VERSION ""

NS_ :

BS_:

BU_: TBOX Tester WCM MFS HUD CGW IHU

BO_ 1535 CGW_CEM_BCM_3: 8 CGW
 SG_ CEM_Remote_key_start : 54|1@0+ (1,0) [0|1] "" Vector__XXX
 SG_ CEM_6_Driver_massageSts : 63|1@0+ (1,0) [0|1] ""  IHU
 SG_ CEM_6_DriverVibrationSts : 62|2@0+ (1,0) [0|3] ""  IHU
 SG_ CEM_6_Driver_massagemodeSts : 60|3@0+ (1,0) [0|7] ""  IHU
 SG_ CEM_3_Windows_Inhibit_SW : 32|1@0+ (1,0) [0|1] ""  IHU
 SG_ CEM_3_CurrentTelematicsMode : 5|2@0+ (1,0) [0|3] ""  IHU
 SG_ CEM_3_GalleryModeSts : 26|2@0+ (1,0) [0|3] ""  IHU
 SG_ CEM_3_passenger_Welcome_Seat_Sts : 57|2@0+ (1,0) [0|3] "Bit"  IHU
 SG_ CEM_DHM_Doorkonbmode_feedback : 53|2@0+ (1,0) [0|2] "Bit"  IHU
 SG_ CEM_DHM_Driver_unlockmode_feedba : 51|2@0+ (1,0) [0|2] "bit"  IHU
 SG_ CEM_UVC_LuminanceBf : 47|3@0+ (1,0) [0|7] "Bit"  IHU
 SG_ CEM_UVC_WorkingBf : 36|2@0+ (1,0) [0|3] "Bit"  IHU
 SG_ CEM_3_Welcome_Seat_Sts : 34|2@0+ (1,0) [0|3] "Bit"  IHU
 SG_ CEM_IPM_3_ACMAXReq_Sts : 38|2@0+ (1,0) [0|3] "Bit"  IHU
 SG_ CEM_3_PM25DisplayToggle_Sts : 49|2@0+ (1,0) [0|3] "Bit"  IHU
 SG_ CEM_3_DWM_Sts_Msg : 17|2@0+ (1,0) [0|3] "Bit"  IHU
 SG_ CEM_3_EngineControlSts : 9|1@0+ (1,0) [0|1] "Bit"  IHU

BO_ 914 CGW_CEM_BCM_2: 8 CGW
 SG_ UnlockingBreathStatus : 52|2@0+ (1,0) [0|3] ""  IHU
 SG_ AidTurningIlluminationSts : 49|1@0+ (1,0) [0|1] ""  IHU
 SG_ CEM_2_AlarmMode : 59|4@0+ (1,0) [0|15] "Bit"  IHU
 SG_ CEM_2_RemoteTrunkOnlySts : 62|1@0+ (1,0) [0|1] "Bit"  IHU
 SG_ CEM_2_AutoLockSts : 63|1@0+ (1,0) [0|1] "Bit"  IHU
 SG_ CEM_2RearDefrosts : 60|1@0+ (1,0) [0|1] "Bit"  IHU
 SG_ CEM_2_HazardLampForUrgencyBrakeS : 48|1@0+ (1,0) [0|1] "Bit"  IHU
 SG_ CEM_2_Mirror_FlipSts : 50|1@0+ (1,0) [0|1] "Bit"  IHU
 SG_ CEM_2_RemoteLockFeedbackSts : 54|2@0+ (1,0) [0|3] "Bit"  IHU
 SG_ CEM_2_AutoUnlockSts : 55|1@0+ (1,0) [0|1] "Bit"  IHU
 SG_ CEM_2_WiperSts : 47|2@0+ (1,0) [0|3] "Bit"  IHU
 SG_ CEM_2_RainDetected : 45|1@0+ (1,0) [0|1] "Bit"  IHU
 SG_ CEM_2_WiperSensitivitySWSts : 44|3@0+ (1,0) [0|7] "Bit"  IHU
 SG_ CEM_2_RainSensorFailSts : 41|1@0+ (1,0) [0|1] "Bit"  IHU
 SG_ CEM_2_RARDfstCmd : 40|1@0+ (1,0) [0|1] "Bit"  IHU
 SG_ CEM_2_WiperSelectionSts : 39|2@0+ (1,0) [0|3] "Bit"  IHU
 SG_ CEM_2_FrontFogLightSts : 37|1@0+ (1,0) [0|1] "Bit"  IHU
 SG_ CEM_2_Laser_High_Beam_Assist_Sta : 36|1@0+ (1,0) [0|1] "Bit"  IHU
 SG_ CEM_2_ReverseGearSwitch : 35|1@0+ (1,0) [0|1] "Bit"  IHU
 SG_ CEM_2_RearFogLightSts : 34|1@0+ (1,0) [0|1] "Bit"  IHU
 SG_ CEM_2_External_WelcomelightSts : 33|2@0+ (1,0) [0|3] "Bit"  IHU
 SG_ CEM_2_Mirror_Fold_Sts : 31|1@0+ (1,0) [0|1] "Bit"  IHU
 SG_ CEM_2_TrunkSts : 30|1@0+ (1,0) [0|1] "Bit"  IHU
 SG_ CEM_2_LHRdoorSts : 29|1@0+ (1,0) [0|1] "Bit"  IHU
 SG_ CEM_2_RHRDoorSts : 28|1@0+ (1,0) [0|1] "Bit"  IHU
 SG_ CEM_2_SunRoofSts : 27|1@0+ (1,0) [0|1] "Bit"  IHU
 SG_ CEM_2_HoodSts : 26|1@0+ (1,0) [0|1] "Bit"  IHU
 SG_ CEM_2_PsngrDoorSts : 25|1@0+ (1,0) [0|1] "Bit"  IHU
 SG_ CEM_2_DriverDoorSts : 24|1@0+ (1,0) [0|1] "Bit"  IHU
 SG_ CEM_2_FollowMeTimeSts : 23|4@0+ (1,0) [0|15] "Bit"  IHU
 SG_ CEM_2_BlankingnumberSts : 19|2@0+ (1,0) [0|3] "Bit"  IHU
 SG_ CEM_2_DirectionIndLeft : 17|1@0+ (1,0) [0|1] "Bit"  IHU
 SG_ CEM_2_DirectionIndRight : 16|1@0+ (1,0) [0|1] "Bit"  IHU
 SG_ CEM_2_DRLSts : 15|1@0+ (1,0) [0|1] "Bit"  IHU
 SG_ CEM_2_LowBeamSts : 14|1@0+ (1,0) [0|1] "Bit"  IHU
 SG_ CEM_2_Laser_LightSts : 13|1@0+ (1,0) [0|1] "Bit"  IHU
 SG_ CEM_2_HighBeamSts : 12|1@0+ (1,0) [0|1] "Bit"  IHU
 SG_ CEM_2_ParkTailLightSts : 11|1@0+ (1,0) [0|1] "Bit"  IHU
 SG_ CEM_2_BrakePedalSts : 10|1@0+ (1,0) [0|1] "Bit"  IHU
 SG_ CEM_2_LHTurnlightSts : 9|1@0+ (1,0) [0|1] "Bit"  IHU
 SG_ CEM_2_RHTurnlightSts : 8|1@0+ (1,0) [0|1] "Bit"  IHU
 SG_ CEM_2_BlankchanginglaneSts : 7|1@0+ (1,0) [0|1] "Bit"  IHU
 SG_ CEM_2_KeySts : 6|2@0+ (1,0) [0|3] "Bit"  IHU
 SG_ CEM_2_FollowMeHomeSts : 4|1@0+ (1,0) [0|1] "Bit"  IHU
 SG_ CEM_2_KeyRemindWarning : 3|1@0+ (1,0) [0|1] "Bit"  IHU
 SG_ CEM_2_ParkLightOnWarning : 2|1@0+ (1,0) [0|1] "Bit"  IHU
 SG_ CEM_2_FollowMeHomeTimeSts : 1|2@0+ (1,0) [0|3] "Bit"  IHU

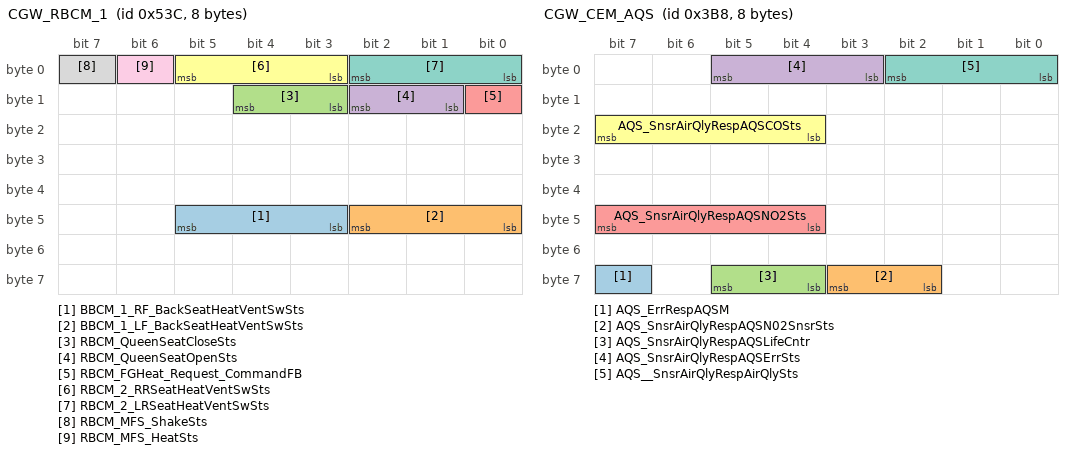
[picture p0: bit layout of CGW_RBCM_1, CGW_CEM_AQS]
BO_ 1340 CGW_RBCM_1: 8 CGW
 SG_ BBCM_1_RF_BackSeatHeatVentSwSts : 45|3@0+ (1,0) [0|4] ""  IHU
 SG_ BBCM_1_LF_BackSeatHeatVentSwSts : 42|3@0+ (1,0) [0|4] ""  IHU
 SG_ RBCM_QueenSeatCloseSts : 12|2@0+ (1,0) [0|3] ""  IHU
 SG_ RBCM_QueenSeatOpenSts : 10|2@0+ (1,0) [0|3] ""  IHU
 SG_ RBCM_FGHeat_Request_CommandFB : 8|1@0+ (1,0) [0|1] "Bit"  IHU
 SG_ RBCM_2_RRSeatHeatVentSwSts : 5|3@0+ (1,0) [0|7] "Bit"  IHU
 SG_ RBCM_2_LRSeatHeatVentSwSts : 2|3@0+ (1,0) [0|7] "Bit"  IHU
 SG_ RBCM_MFS_ShakeSts : 7|1@0+ (1,0) [0|1] "Bit"  IHU
 SG_ RBCM_MFS_HeatSts : 6|1@0+ (1,0) [0|1] "Bit"  IHU

BO_ 1306 CGW_CEM_IPM: 8 CGW
 SG_ CEM_IPM_FRSeatHeatVentSwSts : 61|3@0+ (1,0) [0|7] ""  IHU
 SG_ CEM_IPM_FLSeatHeatVentSwSts : 58|3@0+ (1,0) [0|7] ""  IHU
 SG_ CEM_IPM_ACFastHeatASts : 52|1@0+ (1,0) [0|1] ""  IHU
 SG_ CEM_IPM_FrontDefroststs : 16|1@0+ (1,0) [0|1] ""  IHU
 SG_ CEM_IPM_Blower_DelaySts : 49|1@0+ (1,0) [0|1] ""  IHU
 SG_ CEM_IPM_BT_Reduce_Wind_SpeedSts : 48|1@0+ (1,0) [0|1] "bit"  IHU
 SG_ TMM_IHU_OffRoadSts : 46|1@0+ (1,0) [0|1] "Bit"  IHU
 SG_ CEM_IPM_AC_DisplaySts : 45|1@0+ (1,0) [0|1] "Bit"  IHU
 SG_ CEM_IPM_Custom_Air_Conditioning : 54|2@0+ (1,0) [0|2] "Bit"  IHU
 SG_ CEM_IPM_Automatic_Ventilation : 51|1@0+ (1,0) [0|1] "Bit"  IHU
 SG_ CEM_IPM_First_BlowingSts : 50|1@0+ (1,0) [0|1] "Bit"  IHU
 SG_ CEM_IPM_TempknobRollingCounter : 35|5@0+ (1,0) [0|31] "Bit"  IHU
 SG_ CEM_IPM_AnionPurify : 63|1@0+ (1,0) [0|1] "Bit"  IHU
 SG_ CEM_IPM_PM25_Detect : 55|1@0+ (1,0) [0|1] "Bit"  IHU
 SG_ CEM_IPM_SyncSts : 44|1@0+ (1,0) [0|1] "Bit"  IHU
 SG_ CEM_IPM_FrontAutoACSts : 43|1@0+ (1,0) [0|1] "Bit"  IHU
 SG_ CEM_IPM_RearBlowModeSts : 42|2@0+ (1,0) [0|3] "Bit"  IHU
 SG_ CEM_IPM_RearAutoACSts : 40|1@0+ (1,0) [0|1] "Bit"  IHU
 SG_ CEM_IPM_RearBlowSpdCtrlSts : 39|4@0+ (1,0) [0|15] "Bit"  IHU
 SG_ CEM_IPM_RearTempsts : 29|6@0+ (0.5,0) [16|30] "℃"  IHU
 SG_ CEM_IPM_RearOFFsts : 31|1@0+ (1,0) [0|1] "Bit"  IHU
 SG_ CEM_IPM_RearDefrosts : 30|1@0+ (1,0) [0|1] "Bit"  IHU
 SG_ CEM_IPM_FrontOFFSts : 17|1@0+ (1,0) [0|1] "Bit"  IHU
 SG_ CEM_IPM_ACStatus : 21|1@0+ (1,0) [0|1] "Bit"  IHU
 SG_ CEM_IPM_RecyMode : 23|2@0+ (1,0) [0|3] "Bit"  IHU
 SG_ CEM_IPM_FrontBlowModeSts : 20|3@0+ (1,0) [0|7] "Bit"  IHU
 SG_ CEM_IPM_FrontBlowSpdCtrlsts : 11|4@0+ (1,0) [0|15] "Bit"  IHU
 SG_ CEM_IPM_FRTempsts : 7|6@0+ (0.5,0) [16|30] "℃"  IHU
 SG_ CEM_IPM_FLTempsts : 1|6@0+ (0.5,0) [16|30] "℃"  IHU

BO_ 952 CGW_CEM_AQS: 8 CGW
 SG_ AQS_ErrRespAQSM : 63|1@0+ (1,0) [0|1] "" Vector__XXX
 SG_ AQS_SnsrAirQlyRespAQSN02SnsrSts : 59|2@0+ (1,0) [0|3] "" Vector__XXX
 SG_ AQS_SnsrAirQlyRespAQSLifeCntr : 61|2@0+ (1,0) [0|3] ""  IHU
 SG_ AQS_SnsrAirQlyRespAQSErrSts : 5|3@0+ (1,0) [0|7] ""  IHU
 SG_ AQS_SnsrAirQlyRespAQSNO2Sts : 47|4@0+ (1,0) [0|15] ""  IHU
 SG_ AQS_SnsrAirQlyRespAQSCOSts : 23|4@0+ (1,0) [0|15] ""  IHU
 SG_ AQS__SnsrAirQlyRespAirQlySts : 2|3@0+ (1,0) [0|7] ""  IHU

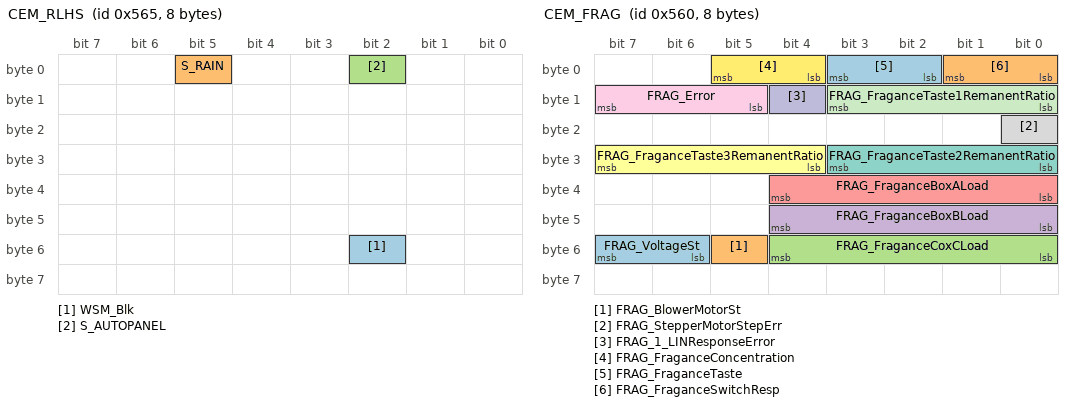
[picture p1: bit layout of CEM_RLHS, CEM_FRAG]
BO_ 1381 CEM_RLHS: 8 CGW
 SG_ WSM_Blk : 50|1@0+ (1,0) [0|1] ""  IHU
 SG_ S_RAIN : 5|1@0+ (1,0) [0|1] "Bit"  IHU
 SG_ S_AUTOPANEL : 2|1@0+ (1,0) [0|1] "Bit"  IHU

BO_ 1376 CEM_FRAG: 8 CGW
 SG_ FRAG_VoltageSt : 55|2@0+ (1,0) [0|3] "Bit"  IHU
 SG_ FRAG_BlowerMotorSt : 53|1@0+ (1,0) [0|1] "Bit"  IHU
 SG_ FRAG_FraganceCoxCLoad : 52|5@0+ (1,0) [0|31] "Bit"  IHU
 SG_ FRAG_FraganceBoxBLoad : 44|5@0+ (1,0) [0|31] "Bit"  IHU
 SG_ FRAG_FraganceBoxALoad : 36|5@0+ (1,0) [0|31] "Bit"  IHU
 SG_ FRAG_FraganceTaste3RemanentRatio : 31|4@0+ (1,0) [0|15] "Bit"  IHU
 SG_ FRAG_FraganceTaste2RemanentRatio : 27|4@0+ (1,0) [0|15] "Bit"  IHU
 SG_ FRAG_StepperMotorStepErr : 16|1@0+ (1,0) [0|1] "Bit"  IHU
 SG_ FRAG_Error : 15|3@0+ (1,0) [0|7] "Bit"  IHU
 SG_ FRAG_1_LINResponseError : 12|1@0+ (1,0) [0|1] "Bit"  IHU
 SG_ FRAG_FraganceTaste1RemanentRatio : 11|4@0+ (1,0) [0|15] "Bit"  IHU
 SG_ FRAG_FraganceConcentration : 5|2@0+ (1,0) [0|3] "Bit"  IHU
 SG_ FRAG_FraganceTaste : 3|2@0+ (1,0) [0|3] "Bit"  IHU
 SG_ FRAG_FraganceSwitchResp : 1|2@0+ (1,0) [0|3] "Bit"  IHU

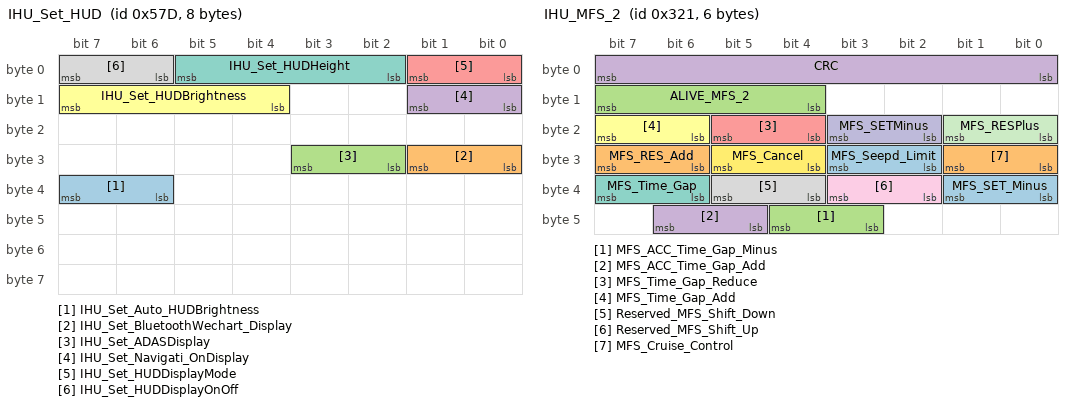
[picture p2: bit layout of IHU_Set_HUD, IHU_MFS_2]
BO_ 1405 IHU_Set_HUD: 8 IHU
 SG_ IHU_Set_Auto_HUDBrightness : 39|2@0+ (1,0) [0|3] "Bit"  CGW
 SG_ IHU_Set_BluetoothWechart_Display : 25|2@0+ (1,0) [0|3] "Bit"  CGW
 SG_ IHU_Set_ADASDisplay : 27|2@0+ (1,0) [0|3] "Bit"  CGW
 SG_ IHU_Set_Navigati_OnDisplay : 9|2@0+ (1,0) [0|3] "Bit"  CGW
 SG_ IHU_Set_HUDDisplayMode : 1|2@0+ (1,0) [0|3] "Bit"  CGW
 SG_ IHU_Set_HUDBrightness : 15|4@0+ (1,0) [0|15] "Bit"  CGW
 SG_ IHU_Set_HUDHeight : 5|4@0+ (1,0) [0|15] "Bit"  CGW
 SG_ IHU_Set_HUDDisplayOnOff : 7|2@0+ (1,0) [0|3] "Bit"  CGW

BO_ 1389 IHU_WCM_Reserved: 8 IHU
 SG_ IHU_WCM_DVD_NFC_Connect_BM_Addr : 7|48@0+ (1,0) [0|281474976710660] "Bit"  CGW

BO_ 801 IHU_MFS_2: 6 CGW
 SG_ MFS_SET_Minus : 33|2@0+ (1,0) [0|3] ""  IHU
 SG_ MFS_RES_Add : 31|2@0+ (1,0) [0|3] ""  IHU
 SG_ MFS_ACC_Time_Gap_Minus : 44|2@0+ (1,0) [0|3] ""  IHU
 SG_ MFS_ACC_Time_Gap_Add : 46|2@0+ (1,0) [0|3] ""  IHU
 SG_ MFS_Time_Gap_Reduce : 21|2@0+ (1,0) [0|3] ""  IHU
 SG_ MFS_Time_Gap_Add : 23|2@0+ (1,0) [0|3] ""  IHU
 SG_ MFS_Time_Gap : 39|2@0+ (1,0) [0|3] "Bit"  IHU
 SG_ Reserved_MFS_Shift_Down : 37|2@0+ (1,0) [0|3] "Bit"  IHU
 SG_ Reserved_MFS_Shift_Up : 35|2@0+ (1,0) [0|3] "Bit"  IHU
 SG_ MFS_SETMinus : 19|2@0+ (1,0) [0|3] "Bit"  IHU
 SG_ MFS_RESPlus : 17|2@0+ (1,0) [0|3] "Bit"  IHU
 SG_ MFS_Cancel : 29|2@0+ (1,0) [0|3] "Bit"  IHU
 SG_ MFS_Seepd_Limit : 27|2@0+ (1,0) [0|3] "Bit"  IHU
 SG_ MFS_Cruise_Control : 25|2@0+ (1,0) [0|3] "Bit"  IHU
 SG_ ALIVE_MFS_2 : 15|4@0+ (1,0) [0|15] "Bit"  IHU
 SG_ CRC : 7|8@0+ (1,0) [0|255] "Bit"  IHU

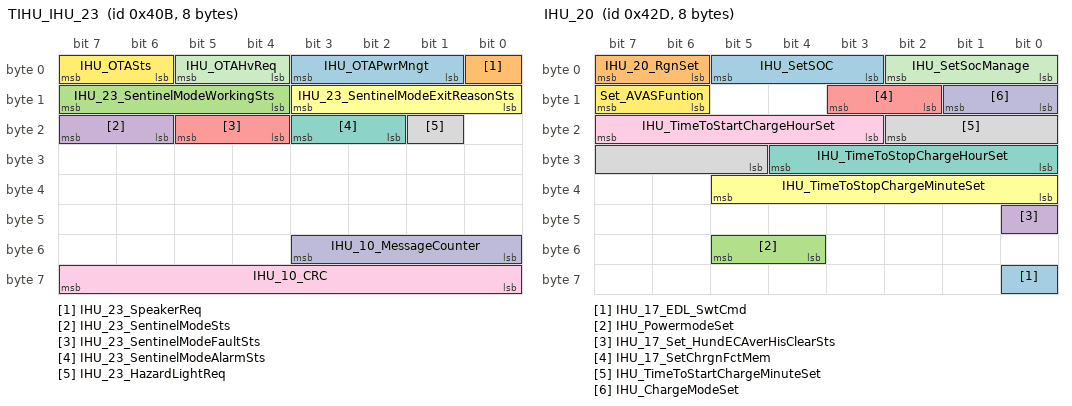
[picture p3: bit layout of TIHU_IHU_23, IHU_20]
BO_ 1035 TIHU_IHU_23: 8 IHU
 SG_ IHU_OTAPwrMngt : 3|3@0+ (1,0) [0|7] ""  CGW
 SG_ IHU_23_SpeakerReq : 0|1@0+ (1,0) [0|1] ""  CGW
 SG_ IHU_23_SentinelModeWorkingSts : 15|4@0+ (1,0) [0|15] ""  CGW
 SG_ IHU_23_SentinelModeSts : 23|2@0+ (1,0) [0|3] ""  CGW
 SG_ IHU_23_SentinelModeFaultSts : 21|2@0+ (1,0) [0|3] ""  CGW
 SG_ IHU_23_SentinelModeExitReasonSts : 11|4@0+ (1,0) [0|15] ""  CGW
 SG_ IHU_23_SentinelModeAlarmSts : 19|2@0+ (1,0) [0|3] ""  CGW
 SG_ IHU_23_HazardLightReq : 17|1@0+ (1,0) [0|1] ""  CGW
 SG_ IHU_10_CRC : 63|8@0+ (1,0) [0|255] ""  CGW
 SG_ IHU_10_MessageCounter : 51|4@0+ (1,0) [0|15] ""  CGW
 SG_ IHU_OTAHvReq : 5|2@0+ (1,0) [0|3] ""  CGW
 SG_ IHU_OTASts : 7|2@0+ (1,0) [0|3] ""  CGW

BO_ 1058 IHU_21: 8 IHU
 SG_ IHU_RIPM_Req : 39|2@0+ (1,0) [0|3] ""  CGW
 SG_ IHU_RestDriverseatMemoryReq : 23|1@0+ (1,0) [0|1] "bit"  CGW
 SG_ IHU_21_AmbientLight_SceneMode : 22|3@0+ (1,0) [0|7] "bit"  CGW
 SG_ IHU_OfficeDriverseatMemoryReq : 2|1@0+ (1,0) [0|1] "bit"  CGW
 SG_ IHU_21_Random_showLamp_SW : 37|2@0+ (1,0) [0|3] "bit"  CGW
 SG_ IHU_21NavigationalTurnType : 35|2@0+ (1,0) [0|3] "bit"  CGW
 SG_ IHU_21AssociatedNavigationModeSw : 33|1@0+ (1,0) [0|1] "bit"  CGW
 SG_ IHU_21MessageCounter : 32|6@0+ (1,0) [0|63] "bit"  CGW
 SG_ IHU_21VoiceBroadcast : 42|1@0+ (1,0) [0|1] "bit"  CGW
 SG_ IHU_21VoiceWake : 41|2@0+ (1,0) [0|3] "bit"  CGW
 SG_ IHU_21_FatigueDrivingReminder_Se : 31|3@0+ (1,0) [0|7] "h"  CGW
 SG_ IHU_21_OverspeedAlarm_Set : 28|5@0+ (5,30) [30|130] "KM/L"  CGW
 SG_ IHU_ICMBrightnessManualAdj : 15|4@0+ (1,0) [0|15] ""  CGW
 SG_ IHU_SET_ICMBrightnessMode : 11|1@0+ (1,0) [0|1] ""  CGW
 SG_ IHU_LockAnimation : 10|3@0+ (1,0) [0|7] ""  CGW
 SG_ IHU_UnlockAnimation : 7|3@0+ (1,0) [0|7] ""  CGW
 SG_ IHU_FatigueDriving : 4|1@0+ (1,0) [0|1] ""  CGW
 SG_ IHU_SmartSceneMode : 19|4@0+ (1,0) [0|15] ""  CGW

BO_ 1069 IHU_20: 8 IHU
 SG_ IHU_17_EDL_SwtCmd : 56|1@0+ (1,0) [0|1] ""  CGW
 SG_ IHU_20_RgnSet : 7|2@0+ (1,0) [0|3] ""  CGW
 SG_ IHU_PowermodeSet : 53|2@0+ (1,0) [0|3] ""  CGW
 SG_ IHU_17_Set_HundECAverHisClearSts : 40|1@0+ (1,0) [0|1] ""  CGW
 SG_ IHU_17_SetChrgnFctMem : 11|2@0+ (1,0) [0|3] ""  CGW
 SG_ IHU_TimeToStopChargeMinuteSet : 37|6@0+ (1,0) [0|59] ""  CGW
 SG_ IHU_TimeToStopChargeHourSet : 28|5@0+ (1,0) [0|23] ""  CGW
 SG_ IHU_TimeToStartChargeMinuteSet : 18|6@0+ (1,0) [0|59] ""  CGW
 SG_ IHU_TimeToStartChargeHourSet : 23|5@0+ (1,0) [0|23] ""  CGW
 SG_ IHU_ChargeModeSet : 9|2@0+ (1,0) [0|3] ""  CGW
 SG_ IHU_SetSocManage : 2|3@0+ (1,0) [0|7] ""  CGW
 SG_ Set_AVASFuntion : 15|2@0+ (1,0) [0|3] ""  CGW
 SG_ IHU_SetSOC : 5|3@0+ (1,0) [0|7] ""  CGW

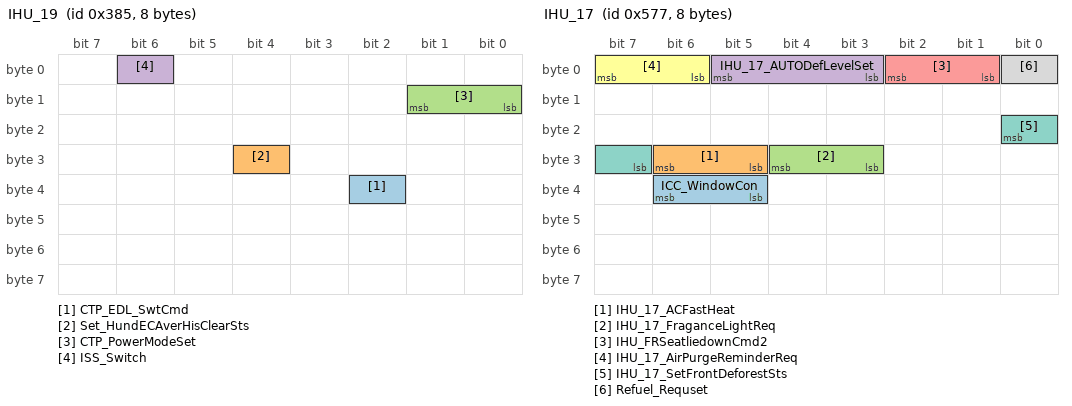
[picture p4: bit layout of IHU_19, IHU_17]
BO_ 901 IHU_19: 8 IHU
 SG_ CTP_EDL_SwtCmd : 34|1@0+ (1,0) [0|1] ""  CGW
 SG_ Set_HundECAverHisClearSts : 28|1@0+ (1,0) [0|1] ""  CGW
 SG_ CTP_PowerModeSet : 9|2@0+ (1,0) [0|3] ""  CGW
 SG_ ISS_Switch : 6|1@0+ (1,0) [0|1] "Bit"  CGW

BO_ 1399 IHU_17: 8 IHU
 SG_ ICC_WindowCon : 38|2@0+ (1,0) [0|3] ""  CGW
 SG_ IHU_17_ACFastHeat : 30|2@0+ (1,0) [0|3] ""  CGW
 SG_ IHU_17_FraganceLightReq : 28|2@0+ (1,0) [0|3] ""  CGW
 SG_ IHU_17_AUTODefLevelSet : 5|3@0+ (1,0) [0|7] ""  CGW
 SG_ IHU_FRSeatliedownCmd2 : 2|2@0+ (1,0) [0|3] ""  CGW
 SG_ IHU_17_AirPurgeReminderReq : 7|2@0+ (1,0) [0|3] ""  CGW
 SG_ IHU_17_SetFrontDeforestSts : 16|2@0+ (1,0) [0|3] ""  CGW
 SG_ Refuel_Requset : 0|1@0+ (1,0) [0|1] "Bit"  CGW

BO_ 1407 IHU_15: 8 IHU
 SG_ IHU_IPM_Delayventilation_Req : 39|2@0+ (1,0) [0|3] ""  CGW
 SG_ IHU_15_door_lock_req : 29|2@0+ (1,0) [0|3] ""  CGW
 SG_ IHU_15_GalleryModeReg : 27|2@0+ (1,0) [0|3] ""  CGW
 SG_ IHU_15_AutoDefogEnaSw : 25|2@0+ (1,0) [0|3] ""  CGW
 SG_ IHU_15_Parkingairconditioning : 31|2@0+ (1,0) [0|3] ""  CGW
 SG_ SET_IHU_ACMAXReq : 61|2@0+ (1,0) [0|3] "Bit"  CGW
 SG_ IHU15_MessageCounter : 59|4@0+ (1,0) [0|15] "Bit"  CGW
 SG_ IHU_SpeechControl : 55|2@0+ (1,0) [0|3] "Bit"  CGW
 SG_ SET_Mirror_Fold_Switch : 23|2@0+ (1,0) [0|3] "Bit"  CGW
 SG_ SET_Passenger_Mirror_Location : 20|5@0+ (1,0) [0|21] "Bit"  CGW
 SG_ SET_Driver_Mirror_Location : 50|5@0+ (1,0) [0|15] "Bit"  CGW
 SG_ SET_IPM_Automatic_Ventilation : 9|2@0+ (1,0) [0|3] "Bit"  CGW
 SG_ SET_Mirror_Flip_CFG : 12|3@0+ (1,0) [0|7] "Bit"  CGW
 SG_ SET_RightMirrorCtrl : 53|3@0+ (1,0) [0|7] "Bit"  CGW
 SG_ SET_LeftMirrorCtrl : 15|3@0+ (1,0) [0|7] "Bit"  CGW
 SG_ SET_IPMCustom_Air_Conditioning : 1|2@0+ (1,0) [0|3] "Bit"  CGW
 SG_ SET_FRSeatHeatVentSwReq : 7|3@0+ (1,0) [0|7] "Bit"  CGW
 SG_ SET_FLSeatHeatVentSwReq : 4|3@0+ (1,0) [0|7] "Bit"  CGW

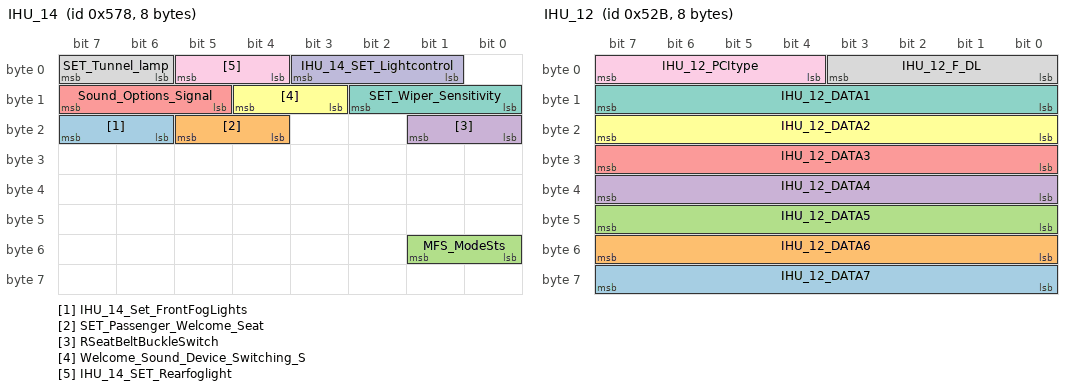
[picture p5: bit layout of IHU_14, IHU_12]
BO_ 1400 IHU_14: 8 IHU
 SG_ IHU_14_Set_FrontFogLights : 23|2@0+ (1,0) [0|3] ""  CGW
 SG_ SET_Passenger_Welcome_Seat : 21|2@0+ (1,0) [0|3] "Bit"  CGW
 SG_ MFS_ModeSts : 49|2@0+ (1,0) [0|3] ""  CGW
 SG_ RSeatBeltBuckleSwitch : 17|2@0+ (1,0) [0|3] "Bit"  CGW
 SG_ Sound_Options_Signal : 15|3@0+ (1,0) [0|5] "Bit"  CGW
 SG_ Welcome_Sound_Device_Switching_S : 12|2@0+ (1,0) [0|3] "Bit"  CGW
 SG_ SET_Wiper_Sensitivity : 10|3@0+ (1,0) [0|7] "Bit"  CGW
 SG_ SET_Tunnel_lamp : 7|2@0+ (1,0) [0|2] "Bit"  CGW
 SG_ IHU_14_SET_Rearfoglight : 5|2@0+ (1,0) [0|2] "Bit"  CGW
 SG_ IHU_14_SET_Lightcontrol : 3|3@0+ (1,0) [0|4] "Bit"  CGW

BO_ 1401 IHU_13: 8 IHU
 SG_ IHU13_MessageCounter : 59|4@0+ (1,0) [0|15] "Bit"  CGW
 SG_ SET_Welcome_Seat : 63|2@0+ (1,0) [0|3] "Bit"  CGW
 SG_ SET_MFS_Shake : 61|2@0+ (1,0) [0|3] "Bit"  CGW
 SG_ SET_MFS_Heat : 55|2@0+ (1,0) [0|3] "Bit"  CGW
 SG_ SET_UnderVoltage : 53|2@0+ (1,0) [0|3] "Bit"  CGW
 SG_ SET_RearWiper_Switch : 51|2@0+ (1,0) [0|3] "Bit"  CGW
 SG_ SET_Wiper_Maintenance : 49|2@0+ (1,0) [0|3] "Bit"  CGW
 SG_ SET_Abat_VentCMD : 47|4@0+ (1,0) [0|15] "Bit"  CGW
 SG_ SET_PSRFCMD : 43|4@0+ (1,0) [0|15] "Bit"  CGW
 SG_ SET_Massagemode : 39|3@0+ (1,0) [0|7] "Bit"  CGW
 SG_ SET_Vibrationmode : 36|3@0+ (1,0) [0|7] "Bit"  CGW
 SG_ SET_Passenger_Massage : 33|2@0+ (1,0) [0|3] "Bit"  CGW
 SG_ SET_PLG_Control : 13|2@0+ (1,0) [0|3] "Bit"  CGW
 SG_ SET_Doorkonbmode : 11|2@0+ (1,0) [0|3] "Bit"  CGW
 SG_ SET_Doorkonb_time : 9|2@0+ (1,0) [0|3] "Bit"  CGW
 SG_ SET_Driver_unlockmode : 6|2@0+ (1,0) [0|3] "Bit"  CGW
 SG_ SET_Smart_LowBeam : 4|2@0+ (1,0) [0|3] "Bit"  CGW
 SG_ SET_LowBeam_Adjust : 2|3@0+ (1,0) [0|7] "Bit"  CGW

BO_ 1323 IHU_12: 8 IHU
 SG_ IHU_12_DATA7 : 63|8@0+ (1,0) [0|255] "Bit"  CGW
 SG_ IHU_12_DATA6 : 55|8@0+ (1,0) [0|255] "Bit"  CGW
 SG_ IHU_12_DATA5 : 47|8@0+ (1,0) [0|255] "Bit"  CGW
 SG_ IHU_12_DATA4 : 39|8@0+ (1,0) [0|255] "Bit"  CGW
 SG_ IHU_12_DATA3 : 31|8@0+ (1,0) [0|255] "Bit"  CGW
 SG_ IHU_12_DATA2 : 23|8@0+ (1,0) [0|255] "Bit"  CGW
 SG_ IHU_12_DATA1 : 15|8@0+ (1,0) [0|255] "Bit"  CGW
 SG_ IHU_12_F_DL : 3|4@0+ (1,0) [0|15] "Bit"  CGW
 SG_ IHU_12_PCItype : 7|4@0+ (1,0) [0|15] "Bit"  CGW

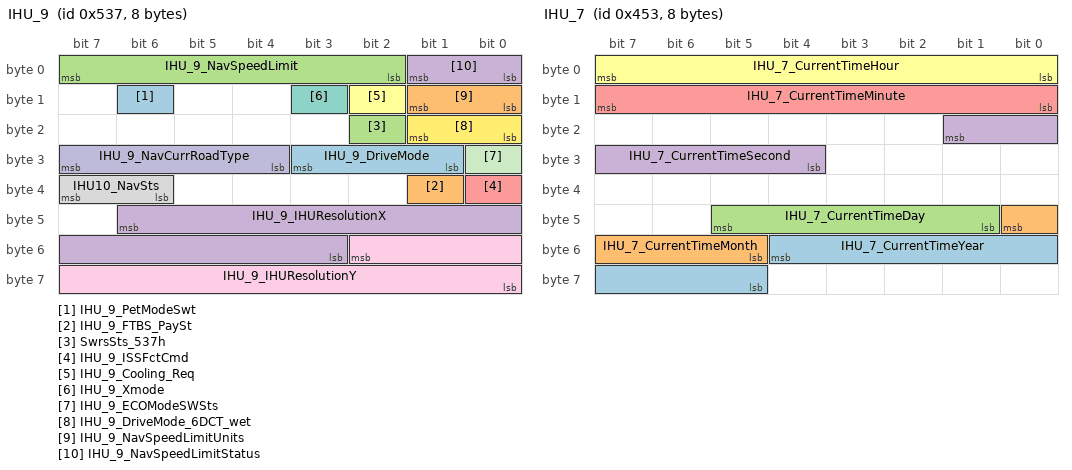
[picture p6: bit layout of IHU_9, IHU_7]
BO_ 1335 IHU_9: 8 IHU
 SG_ IHU_9_PetModeSwt : 14|1@0+ (1,0) [0|1] ""  CGW
 SG_ IHU_9_FTBS_PaySt : 33|1@0+ (1,0) [0|1] ""  CGW
 SG_ SwrsSts_537h : 18|1@0+ (1,0) [0|1] ""  CGW
 SG_ IHU_9_IHUResolutionX : 46|12@0+ (1,0) [0|4095] "Bit"  CGW
 SG_ IHU_9_ISSFctCmd : 32|1@0+ (1,0) [0|1] "bit"  CGW
 SG_ IHU_9_Cooling_Req : 10|1@0+ (1,0) [0|1] ""  CGW
 SG_ IHU_9_Xmode : 11|1@0+ (1,0) [0|1] ""  CGW
 SG_ IHU10_NavSts : 39|2@0+ (1,0) [0|3] "Bit"  CGW
 SG_ IHU_9_IHUResolutionY : 50|11@0+ (1,0) [0|2047] "Bit"  CGW
 SG_ IHU_9_NavCurrRoadType : 31|4@0+ (1,0) [0|15] "Bit"  CGW
 SG_ IHU_9_ECOModeSWSts : 24|1@0+ (1,0) [0|1] "Bit"  CGW
 SG_ IHU_9_DriveMode_6DCT_wet : 17|2@0+ (1,0) [0|3] "Bit"  CGW
 SG_ IHU_9_DriveMode : 27|3@0+ (1,0) [0|7] "Bit"  CGW
 SG_ IHU_9_NavSpeedLimitUnits : 9|2@0+ (1,0) [0|3] "Bit"  CGW
 SG_ IHU_9_NavSpeedLimit : 7|6@0+ (1,0) [0|63] "Bit"  CGW
 SG_ IHU_9_NavSpeedLimitStatus : 1|2@0+ (1,0) [0|3] "Bit"  CGW

BO_ 1309 IHU_8: 8 IHU
 SG_ IHU_EPBAUTO_Cmd : 33|2@0+ (1,0) [0|3] ""  CGW
 SG_ IHU_EPB_Cmd : 21|2@0+ (1,0) [0|3] ""  CGW
 SG_ IHU_SpeParkSet : 55|2@0+ (1,0) [0|3] ""  CGW
 SG_ IHU8Curvedeceleration_ON_OFF_Sts : 43|2@0+ (1,0) [0|3] ""  CGW
 SG_ IHU_8_CCOSwtReq : 53|2@0+ (1,0) [0|3] ""  CGW
 SG_ Child_Safety_Lock : 19|2@0+ (1,0) [0|3] "Bit"  CGW
 SG_ SET_PAS_Switch : 23|2@0+ (1,0) [0|3] "Bit"  CGW
 SG_ CGW_DVDSET_IPBAssociateDriveMode : 25|2@0+ (1,0) [0|3] "Bit"  CGW
 SG_ CGW_CST_SensitivityReq : 29|2@0+ (1,0) [0|3] "Bit"  CGW
 SG_ ESCOFF_ON_OFF : 17|2@0+ (1,0) [0|3] "Bit"  CGW
 SG_ HDC_ON_OFF : 31|2@0+ (1,0) [0|3] "Bit"  CGW
 SG_ AVH_ON_OFF : 39|2@0+ (1,0) [0|3] "Bit"  CGW
 SG_ IHU_CGW_BrakepedalfeelModeSetReq : 27|2@0+ (1,0) [0|3] "Bit"  CGW
 SG_ IHU_8_CGW_Set_CSTFunctionSts : 10|2@0+ (1,0) [0|3] "Bit"  CGW
 SG_ IHU_8_LDWLKA_LaneAssit_TypeReq : 37|2@0+ (1,0) [0|3] "Bit"  CGW
 SG_ IHU_8_SLAOnOffReq : 35|2@0+ (1,0) [0|3] "Bit"  CGW
 SG_ IHU_8_HMAOnOffReq : 41|2@0+ (1,0) [0|3] "Bit"  CGW
 SG_ IHU_8_LDW_LKA_SensitivityReq : 51|2@0+ (1,0) [0|3] "Bit"  CGW
 SG_ IHU_8_TimeGapLastSetReq : 49|2@0+ (1,0) [0|3] "Bit"  CGW
 SG_ IHU_8_DistanceWarning_On_Off : 12|2@0+ (1,0) [0|3] "Bit"  CGW
 SG_ IHU_8_TJA_ICA_ON_OFF : 14|2@0+ (1,0) [0|3] "Bit"  CGW
 SG_ IHU_8_AEB_ON_OFF : 0|2@0+ (1,0) [0|3] "Bit"  CGW
 SG_ IHU_8_FCW_OPTION : 7|2@0+ (1,0) [0|3] "Bit"  CGW
 SG_ IHU_8_FCW_ON_OFF : 5|2@0+ (1,0) [0|3] "Bit"  CGW
 SG_ IHU_8_TimeGapSet1Req : 3|3@0+ (1,0) [0|7] "Bit"  CGW

BO_ 1107 IHU_7: 8 IHU
 SG_ IHU_7_CurrentTimeYear : 52|8@0+ (1,2000) [2000|2255] "Year"  CGW
 SG_ IHU_7_CurrentTimeMonth : 40|4@0+ (1,0) [0|12] "Month"  CGW
 SG_ IHU_7_CurrentTimeDay : 45|5@0+ (1,0) [1|31] "Day"  CGW
 SG_ IHU_7_CurrentTimeSecond : 17|6@0+ (1,0) [0|59] "Second"  CGW
 SG_ IHU_7_CurrentTimeMinute : 15|8@0+ (1,0) [0|59] "Minute"  CGW
 SG_ IHU_7_CurrentTimeHour : 7|8@0+ (1,0) [0|23] "Hour"  CGW

BO_ 1344 IHU_6: 8 IHU
 SG_ IHU_6_AmbientLight_SceneMode : 38|3@0+ (1,0) [0|7] "Bit"  CGW
 SG_ IHU_6_SET_MusicLoudness_6000HZ : 35|4@0+ (1,0) [0|15] "Bit"  CGW
 SG_ IHU_6_SET_MusicLoudness_2000HZ : 47|4@0+ (1,0) [0|15] "Bit"  CGW
 SG_ IHU_6_SET_MusicLoudness_1500HZ : 43|4@0+ (1,0) [0|15] "Bit"  CGW
 SG_ IHU_6_SET_MusicLoudness_1000HZ : 55|4@0+ (1,0) [0|15] "Bit"  CGW
 SG_ IHU_6_SET_MusicLoudness_500HZ : 51|4@0+ (1,0) [0|15] "Bit"  CGW
 SG_ IHU_6_SET_MusicLoudness_250HZ : 63|4@0+ (1,0) [0|15] "Bit"  CGW
 SG_ IHU_6_SET_MusicLoudness_120HZ : 59|4@0+ (1,0) [0|15] "Bit"  CGW
 SG_ IHU_6_SET_Apiluminance : 19|4@0+ (1,0) [0|15] "Bit"  CGW
 SG_ IHU_6_SET_DMSMonitoring : 24|2@0+ (1,0) [0|3] "Bit"  CGW
 SG_ IHU_6_SET_PM2_5Monitoring : 14|2@0+ (1,0) [0|3] "Bit"  CGW
 SG_ IHU_6_SET_DriveApiluminance : 1|2@0+ (1,0) [0|3] "Bit"  CGW
 SG_ IHU_6_SET_64Colour : 31|7@0+ (1,0) [0|64] "Bit"  CGW
 SG_ IHU_6_SET_Static_Colour : 23|4@0+ (1,0) [0|15] "Bit"  CGW
 SG_ IHU_6_SET_StaticEffect : 12|3@0+ (1,0) [0|7] "Bit"  CGW
 SG_ IHU_6_SET_ControlSwitch : 9|2@0+ (1,0) [0|3] "Bit"  CGW
 SG_ IHU_6_SET_WelcomeWaterLamp : 7|2@0+ (1,0) [0|3] "Bit"  CGW
 SG_ IHU_6_SET_AssociatedWithDriverMo : 5|2@0+ (1,0) [0|3] "Bit"  CGW
 SG_ IHU_6_SET_Music : 3|2@0+ (1,0) [0|3] "Bit"  CGW

BO_ 1327 IHU_5: 8 IHU
 SG_ IHU_5_CoolantFill_Req : 23|1@0+ (1,0) [0|1] "" Vector__XXX
 SG_ IHU_5_UVC_LuminanceReq : 63|2@0+ (1,0) [0|3] "Bit"  CGW
 SG_ IHU_5_UVC_ControlReq : 61|2@0+ (1,0) [0|3] "Bit"  CGW
 SG_ IHU_5_PM25DisplayToggle : 59|2@0+ (1,0) [0|3] "Bit"  CGW
 SG_ IHU_5_DVD_DWMCon_Req : 57|2@0+ (1,0) [0|3] "Bit"  CGW
 SG_ IHU_5_SyncSwtich_Req : 49|2@0+ (1,0) [0|3] "Bit"  CGW
 SG_ IHU_5_L_Set_Temperature : 47|7@0+ (0.5,0) [16|30] "℃"  CGW
 SG_ IHU_5_R_Set_Temperature : 40|7@0+ (0.5,0) [16|30] "℃"  CGW
 SG_ IHU_5_AnionPurify_Req : 38|2@0+ (1,0) [0|3] "Bit"  CGW
 SG_ IHU_5_AutoState : 36|2@0+ (1,0) [0|3] "Bit"  CGW
 SG_ IHU_5_EngineControlEDReq : 3|1@0+ (1,0) [0|1] "Bit"  CGW
 SG_ IHU_5_RRWindowCon_Req : 34|3@0+ (1,0) [0|7] "Bit"  CGW
 SG_ IHU_5_LRWindowCon_Req : 31|3@0+ (1,0) [0|7] "Bit"  CGW
 SG_ IHU_5_FLWindowCon_Req : 28|3@0+ (1,0) [0|7] "Bit"  CGW
 SG_ IHU_5_FRWindowCon_Req : 25|3@0+ (1,0) [0|7] "Bit"  CGW
 SG_ IHU_5_Control_Mode_Req : 22|2@0+ (1,0) [0|3] "Bit"  CGW
 SG_ IHU_5_TempknobRollingCounterReq : 20|5@0+ (1,0) [0|31] "Bit"  CGW
 SG_ IHU_5_RearDefrostSwitch_Req : 15|2@0+ (1,0) [0|3] "Bit"  CGW
 SG_ IHU_5_ACRequestCommand : 13|2@0+ (1,0) [0|3] "Bit"  CGW
 SG_ IHU_5_FrontOFF_Req : 11|2@0+ (1,0) [0|3] "Bit"  CGW
 SG_ IHU_5_CirculationMode_Req : 9|2@0+ (1,0) [0|3] "Bit"  CGW
 SG_ IHU_5_ModeAdjust_Req : 2|3@0+ (1,0) [0|7] "Bit"  CGW
 SG_ IHU_5_BlowSpeedLevel_Req : 7|4@0+ (1,0) [0|15] "Bit"  CGW

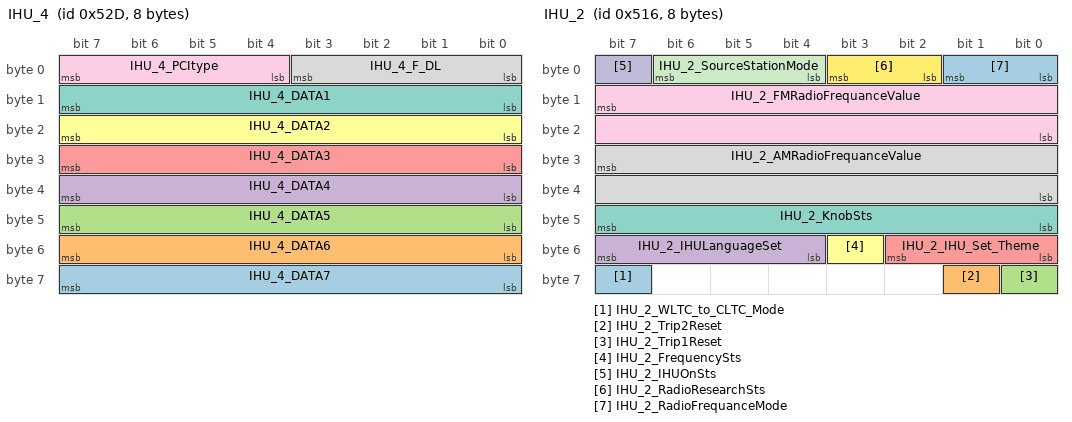
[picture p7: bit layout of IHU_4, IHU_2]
BO_ 1325 IHU_4: 8 IHU
 SG_ IHU_4_DATA7 : 63|8@0+ (1,0) [0|255] "Bit"  CGW
 SG_ IHU_4_DATA6 : 55|8@0+ (1,0) [0|255] "Bit"  CGW
 SG_ IHU_4_DATA5 : 47|8@0+ (1,0) [0|255] "Bit"  CGW
 SG_ IHU_4_DATA4 : 39|8@0+ (1,0) [0|255] "Bit"  CGW
 SG_ IHU_4_DATA3 : 31|8@0+ (1,0) [0|255] "Bit"  CGW
 SG_ IHU_4_DATA2 : 23|8@0+ (1,0) [0|255] "Bit"  CGW
 SG_ IHU_4_DATA1 : 15|8@0+ (1,0) [0|255] "Bit"  CGW
 SG_ IHU_4_F_DL : 3|4@0+ (1,0) [0|15] "Bit"  CGW
 SG_ IHU_4_PCItype : 7|4@0+ (1,0) [0|15] "Bit"  CGW

BO_ 1303 IHU_3: 8 IHU
 SG_ IHU_3_Set_Default : 63|3@0+ (1,0) [0|7] "Bit"  CGW
 SG_ IHU_3_DVD_SetScreen : 60|2@0+ (1,0) [0|3] "Bit"  CGW
 SG_ IHU_3_DVD_SetWorkModeSts : 58|3@0+ (1,0) [0|7] "Bit"  CGW
 SG_ IHU_3_DVD_OP_TP_Y : 47|16@0+ (1,0) [0|65535] "Bit"  CGW
 SG_ IHU_3_DVD_OP_TP_X : 31|16@0+ (1,0) [0|65535] "Bit"  CGW
 SG_ IHU_3_DVD_DefDispMode : 23|2@0+ (1,0) [0|3] "Bit"  CGW
 SG_ IHU_3_BT_PHONE_Sts : 21|2@0+ (1,0) [0|3] "Bit"  CGW
 SG_ IHU_3_DVD_Set_RCW : 19|2@0+ (1,0) [0|3] "Bit"  CGW
 SG_ IHU_3_DVD_Set_DOW : 17|2@0+ (1,0) [0|3] "Bit"  CGW
 SG_ IHU_3_DVD_Set_RadarWarining : 14|2@0+ (1,0) [0|3] "Bit"  CGW
 SG_ IHU_3_AVM_SET_LANG : 12|3@0+ (1,0) [0|7] "Bit"  CGW
 SG_ IHU_3_AVM_OP_VIEW_DVR_SW : 9|2@0+ (1,0) [0|3] "Bit"  CGW
 SG_ IHU_3_DVD_Set_SteeringWheel : 7|2@0+ (1,0) [0|3] "Bit"  CGW
 SG_ IHU_3_BSDSwitch : 5|2@0+ (1,0) [0|3] "Bit"  CGW
 SG_ IHU_3_LDWSwitch : 3|2@0+ (1,0) [0|3] "Bit"  CGW
 SG_ IHU_3_CalibrationRequest : 1|1@0+ (1,0) [0|1] "Bit"  CGW
 SG_ IHU_APA_OP_SW : 0|2@0+ (1,0) [0|3] "Bit"  CGW

BO_ 1302 IHU_2: 8 IHU
 SG_ IHU_2_WLTC_to_CLTC_Mode : 63|1@0+ (1,0) [0|1] ""  CGW
 SG_ IHU_2_Trip2Reset : 57|1@0+ (1,0) [0|1] "Bit"  CGW
 SG_ IHU_2_Trip1Reset : 56|1@0+ (1,0) [0|1] "Bit"  CGW
 SG_ IHU_2_IHULanguageSet : 55|4@0+ (1,0) [0|15] "Bit"  CGW
 SG_ IHU_2_IHU_Set_Theme : 50|3@0+ (1,0) [0|7] "Bit"  CGW
 SG_ IHU_2_FrequencySts : 51|1@0+ (1,0) [0|1] "Bit"  CGW
 SG_ IHU_2_KnobSts : 47|8@0+ (1,0) [0|39] "Bit"  CGW
 SG_ IHU_2_AMRadioFrequanceValue : 31|16@0+ (1,0) [520|1710] "KHz"  CGW
 SG_ IHU_2_FMRadioFrequanceValue : 15|16@0+ (0.005,0) [65|108] "MHz"  CGW
 SG_ IHU_2_IHUOnSts : 7|1@0+ (1,0) [0|1] "Bit"  CGW
 SG_ IHU_2_SourceStationMode : 6|3@0+ (1,0) [0|7] "Bit"  CGW
 SG_ IHU_2_RadioResearchSts : 3|2@0+ (1,0) [0|3] "Bit"  CGW
 SG_ IHU_2_RadioFrequanceMode : 1|2@0+ (1,0) [0|3] "Bit"  CGW

BO_ 1301 IHU_1: 8 IHU
 SG_ IHU_1_DVD_SET_Laser_High_Beam_As : 13|2@0+ (1,0) [0|3] ""  CGW
 SG_ IHU_1_DVD_SET_Mirror_Flip : 15|2@0+ (1,0) [0|3] ""  CGW
 SG_ IHU_1_DVD_SET_HazardLampForUrgen : 7|2@0+ (1,0) [0|3] ""  CGW
 SG_ DVD_EPS_AssociWithDriverModeSts : 53|2@0+ (1,0) [0|3] "bit"  CGW
 SG_ IHU_1_SET_DWD_Req : 55|2@0+ (1,0) [0|3] "Bit"  CGW
 SG_ IHU_1_RegenerateLevelCtrl : 51|2@0+ (1,0) [0|3] "Bit"  CGW
 SG_ IHU_1_DVD_SetFraganceTime : 41|2@0+ (1,0) [0|3] "Bit"  CGW
 SG_ DVD_Set_FraganceConcentration : 43|2@0+ (1,0) [0|3] "Bit"  CGW
 SG_ IHU_1_DVD_Set_FraganceTaste : 45|2@0+ (1,0) [0|3] "Bit"  CGW
 SG_ IHU_1_DVD_Set_FraganceSwitchSt : 47|2@0+ (1,0) [0|3] "Bit"  CGW
 SG_ IHU_1_DVD_SET_PLG_SAS : 63|8@0+ (1,0) [0|100] "%"  CGW
 SG_ IHU_1_DVD_Set_External_Welcome_L : 39|3@0+ (1,0) [0|7] "Bit"  CGW
 SG_ IHU_1_DVD_Set_Show_Mode : 36|2@0+ (1,0) [0|3] "Bit"  CGW
 SG_ IHU_1_DVD_SET_Polling : 34|2@0+ (1,0) [0|3] "Bit"  CGW
 SG_ IHU_1_DVD_SET_IPM_First_Blowing : 49|2@0+ (1,0) [0|3] "Bit"  CGW
 SG_ IHU_1_DVD_SET_IPM_Blower_Delay : 30|2@0+ (1,0) [0|3] "Bit"  CGW
 SG_ IHU_DVD_SET_BT_Reduce_Wind_Speed : 28|2@0+ (1,0) [0|3] "Bit"  CGW
 SG_ IHU_1_DVD_SET_RemoteLockFeedback : 26|3@0+ (1,0) [0|7] "Bit"  CGW
 SG_ IHU_1_DVD_SET_EPSmode : 23|2@0+ (1,0) [0|3] "Bit"  CGW
 SG_ IHU_1_DVD_Set_Wash_Car : 21|2@0+ (1,0) [0|3] "Bit"  CGW
 SG_ IHU_1_DVD_Set_12_24_Hour : 19|2@0+ (1,0) [0|3] "Bit"  CGW
 SG_ IHU_1_DVD_SET_Blankingnumber : 17|2@0+ (1,0) [0|3] "Bit"  CGW
 SG_ IHU_1_DVD_SET_AutoUnlockSts : 11|2@0+ (1,0) [0|3] "Bit"  CGW
 SG_ IHU_1_DVD_SET_AutoLockSts : 9|2@0+ (1,0) [0|3] "Bit"  CGW
 SG_ IHU_1_DVD_SET_AidTurningIllumina : 5|2@0+ (1,0) [0|3] "Bit"  CGW
 SG_ IHU_1_DVD_SET_FollowMeHome : 3|2@0+ (1,0) [0|3] "Bit"  CGW
 SG_ IHU_1_DVD_SET_Mirror_Fold : 1|2@0+ (1,0) [0|3] "Bit"  CGW

CM_ SG_ 1535 CEM_3_passenger_Welcome_Seat_Sts "座椅迎宾礼让反馈状态";
CM_ SG_ 1535 CEM_DHM_Doorkonbmode_feedback "门把手是否自动弹出模式反馈";
CM_ SG_ 1535 CEM_DHM_Driver_unlockmode_feedba "驾驶员解锁模式反馈";
CM_ SG_ 1535 CEM_UVC_LuminanceBf "UVC亮度反馈";
CM_ SG_ 1535 CEM_UVC_WorkingBf "UVC控制反馈";
CM_ SG_ 1535 CEM_3_Welcome_Seat_Sts "座椅迎宾礼让反馈状态";
CM_ SG_ 1535 CEM_IPM_3_ACMAXReq_Sts "AC MAX请求信号";
CM_ SG_ 1535 CEM_3_PM25DisplayToggle_Sts "PM2.5内外显示切换状态反馈";
CM_ SG_ 1535 CEM_3_DWM_Sts_Msg "天窗状况反馈";
CM_ SG_ 1535 CEM_3_EngineControlSts "语音启动发动机状态反馈";
CM_ SG_ 914 CEM_2_AlarmMode "设防状态信号";
CM_ SG_ 914 CEM_2_RemoteTrunkOnlySts "仅钥匙开启后背门反馈";
CM_ SG_ 914 CEM_2_AutoLockSts "自动上锁模式状态";
CM_ SG_ 914 CEM_2RearDefrosts "后除霜
（PHEV项目使用）";
CM_ SG_ 914 CEM_2_HazardLampForUrgencyBrakeS "紧急制动报警灯点亮提醒模式状态";
CM_ SG_ 914 CEM_2_Mirror_FlipSts "外后视镜倒车翻转";
CM_ SG_ 914 CEM_2_RemoteLockFeedbackSts "设防提示状态";
CM_ SG_ 914 CEM_2_AutoUnlockSts "自动解锁模式状态";
CM_ SG_ 914 CEM_2_WiperSts "雨刮器状态";
CM_ SG_ 914 CEM_2_RainDetected "雨量状态";
CM_ SG_ 914 CEM_2_WiperSensitivitySWSts "雨刮灵敏度开关状态反馈";
CM_ SG_ 914 CEM_2_RainSensorFailSts "雨量传感器故障状态";
CM_ SG_ 914 CEM_2_RARDfstCmd "后除霜信息";
CM_ SG_ 914 CEM_2_WiperSelectionSts "雨刮器选择状态";
CM_ SG_ 914 CEM_2_FrontFogLightSts "前雾灯状态";
CM_ SG_ 914 CEM_2_ReverseGearSwitch "倒挡开关状态";
CM_ SG_ 914 CEM_2_RearFogLightSts "后雾灯";
CM_ SG_ 914 CEM_2_External_WelcomelightSts "外部灯光迎宾";
CM_ SG_ 914 CEM_2_Mirror_Fold_Sts "后视镜折叠状态";
CM_ SG_ 914 CEM_2_TrunkSts "后背门状态";
CM_ SG_ 914 CEM_2_LHRdoorSts "左后门状态";
CM_ SG_ 914 CEM_2_RHRDoorSts "右后门状态";
CM_ SG_ 914 CEM_2_SunRoofSts "天窗状态";
CM_ SG_ 914 CEM_2_HoodSts "引擎盖状态";
CM_ SG_ 914 CEM_2_PsngrDoorSts "副驾门状态";
CM_ SG_ 914 CEM_2_DriverDoorSts "主驾门状态";
CM_ SG_ 914 CEM_2_FollowMeTimeSts "伴我回家时间状态";
CM_ SG_ 914 CEM_2_BlankingnumberSts "变道灯次数状态";
CM_ SG_ 914 CEM_2_DirectionIndLeft "左侧方向指示灯";
CM_ SG_ 914 CEM_2_DirectionIndRight "右侧方向指示灯";
CM_ SG_ 914 CEM_2_DRLSts "逻辑灯状态";
CM_ SG_ 914 CEM_2_LowBeamSts "近光状态";
CM_ SG_ 914 CEM_2_Laser_LightSts "照地灯状态";
CM_ SG_ 914 CEM_2_HighBeamSts "远光状态";
CM_ SG_ 914 CEM_2_ParkTailLightSts "制动灯状态";
CM_ SG_ 914 CEM_2_BrakePedalSts "刹车踏板信号";
CM_ SG_ 914 CEM_2_LHTurnlightSts "左后转向灯状态";
CM_ SG_ 914 CEM_2_RHTurnlightSts "右后转向灯状态";
CM_ SG_ 914 CEM_2_BlankchanginglaneSts "变道闪光开关状态";
CM_ SG_ 914 CEM_2_KeySts "钥匙状态";
CM_ SG_ 914 CEM_2_FollowMeHomeSts "伴我回家开关状态";
CM_ SG_ 914 CEM_2_KeyRemindWarning "钥匙遗忘提醒";
CM_ SG_ 914 CEM_2_ParkLightOnWarning "制动灯亮报警";
CM_ SG_ 914 CEM_2_FollowMeHomeTimeSts "伴我回家时间状态";
CM_ SG_ 1340 RBCM_FGHeat_Request_CommandFB "(前风档喷雾加热反馈)（JX65国际二阶段用）";
CM_ SG_ 1340 RBCM_2_RRSeatHeatVentSwSts "右后座椅加热状态（JX65国际二阶段用）";
CM_ SG_ 1340 RBCM_2_LRSeatHeatVentSwSts "左后座椅加热状态（JX65国际二阶段用）";
CM_ SG_ 1340 RBCM_MFS_ShakeSts "方向盘震动";
CM_ SG_ 1340 RBCM_MFS_HeatSts "方向盘加热";
CM_ SG_ 1306 CEM_IPM_AC_DisplaySts "AC显示状态反馈";
CM_ SG_ 1306 CEM_IPM_Custom_Air_Conditioning "自定义空调";
CM_ SG_ 1306 CEM_IPM_Automatic_Ventilation "空调自动通风";
CM_ SG_ 1306 CEM_IPM_First_BlowingSts "空调启动时第一口风状态；";
CM_ SG_ 1306 CEM_IPM_TempknobRollingCounter "温度档位_电动需求";
CM_ SG_ 1306 CEM_IPM_AnionPurify "负离子开启请求";
CM_ SG_ 1306 CEM_IPM_PM25_Detect "PM2_5检测功能";
CM_ SG_ 1306 CEM_IPM_SyncSts "同步功能";
CM_ SG_ 1306 CEM_IPM_FrontAutoACSts "前排自动功能";
CM_ SG_ 1306 CEM_IPM_RearBlowModeSts "后排吹风模式设置";
CM_ SG_ 1306 CEM_IPM_RearAutoACSts "空调工作状态
Active关闭空调
Not_Active打开空调";
CM_ SG_ 1306 CEM_IPM_RearBlowSpdCtrlSts "后排风速设置";
CM_ SG_ 1306 CEM_IPM_RearTempsts "后排温度设置功能";
CM_ SG_ 1306 CEM_IPM_RearOFFsts "后排关闭功能";
CM_ SG_ 1306 CEM_IPM_RearDefrosts "后除霜
（主项目使用）";
CM_ SG_ 1306 CEM_IPM_FrontOFFSts "空调关闭";
CM_ SG_ 1306 CEM_IPM_ACStatus "AC_状态";
CM_ SG_ 1306 CEM_IPM_RecyMode "内外循环";
CM_ SG_ 1306 CEM_IPM_FrontBlowModeSts "前排吹风模式设置";
CM_ SG_ 1306 CEM_IPM_FrontBlowSpdCtrlsts "前排风速设置";
CM_ SG_ 1306 CEM_IPM_FRTempsts "前排右侧温度设置";
CM_ SG_ 1306 CEM_IPM_FLTempsts "前排左侧温度设置";
CM_ SG_ 1381 S_RAIN "Rain_detected
检测到有无雨量";
CM_ SG_ 1381 S_AUTOPANEL "Auto_Panel_Dim_Request
自动亮灯:小灯";
CM_ SG_ 1376 FRAG_VoltageSt "电压状态";
CM_ SG_ 1376 FRAG_BlowerMotorSt "0=无故障，默认值；
1=故障";
CM_ SG_ 1376 FRAG_FraganceCoxCLoad "0=无香盒；
1-30：不同 ID 对应香盒；
31：无效香盒；";
CM_ SG_ 1376 FRAG_FraganceBoxBLoad "0=无香盒；
1-30：不同 ID 对应香盒；
31：无效香盒；";
CM_ SG_ 1376 FRAG_FraganceBoxALoad "0=无香盒；
1-30：不同 ID 对应香盒；
31：无效香盒；";
CM_ SG_ 1376 FRAG_FraganceTaste3RemanentRatio "香氛盒 3 香料（对应taste3）剩余量，10%精
度；";
CM_ SG_ 1376 FRAG_FraganceTaste2RemanentRatio "香氛盒 2 香料（对应taste2）剩余量，10%精
度；";
CM_ SG_ 1376 FRAG_StepperMotorStepErr "0=无故障；
1=故障；";
CM_ SG_ 1376 FRAG_Error "0=无故障，默认值； 
1=重启故障；
2=过压；
3=欠压；
4= Tx Bit error;
5=Checksum Error
6=Byte Field Framing Error
7=ID Parity Error";
CM_ SG_ 1376 FRAG_1_LINResponseError "LIN响应错误";
CM_ SG_ 1376 FRAG_FraganceTaste1RemanentRatio "香氛盒 1 香料（对应taste1）剩余量，10%精
度；";
CM_ SG_ 1376 FRAG_FraganceConcentration "0=无请求,默认值；1=低浓度，2=中浓度，3=高
浓度；";
CM_ SG_ 1376 FRAG_FraganceTaste "0=不动作,默认值；Taste1与装香装置 A 对应，
Taste2 与装香装置 B对应, Taste3 与装香装 置 C 对应";
CM_ SG_ 1376 FRAG_FraganceSwitchResp "0=关闭，默认值；1=开启；
注意：该信号用于主机显示香氛运行状态，非真正代表FRAG 内部实际运行和停止状态，考虑到香氛运行时候需要定时开启和关闭一段时间；";
CM_ SG_ 1405 IHU_Set_Auto_HUDBrightness "HUD亮度调节模式
Feedback:0x57E:STAT_Auto_HUDBrightness";
CM_ SG_ 1405 IHU_Set_BluetoothWechart_Display "开启和关闭蓝牙电话显示
Feedback:0x57E:STAT_BluetoothWechart_Display";
CM_ SG_ 1405 IHU_Set_ADASDisplay "开启和关闭智能驾驶辅助显示
Feedback:0x57E:STAT_ADASDisplay";
CM_ SG_ 1405 IHU_Set_Navigati_OnDisplay "开启和关闭导航信息显示
Feedback:0x57E:STAT_Navigati_OnDisplay";
CM_ SG_ 1405 IHU_Set_HUDDisplayMode "HUD模式设置
Feedback:0x57E:STAT_HUDDisplayMod";
CM_ SG_ 1405 IHU_Set_HUDBrightness "图像亮度调节
Feedback:0x57E:STAT_HUDBrightness";
CM_ SG_ 1405 IHU_Set_HUDHeight "图像高度调节
Feedback:0x57E:STAT_HUDHeight";
CM_ SG_ 1405 IHU_Set_HUDDisplayOnOff "HUD开关
Feedback:0x57E:STAT_HUDDisplayOnOff";
CM_ SG_ 1389 IHU_WCM_DVD_NFC_Connect_BM_Addr "6字节蓝牙地址";
CM_ SG_ 801 MFS_Time_Gap_Reduce "跟车时距调节（ACC配置）:车间距减少1";
CM_ SG_ 801 MFS_Time_Gap_Add "跟车时距调节（ACC配置）:车间距增加1";
CM_ SG_ 801 MFS_Time_Gap "跟车时距调节（ACC配置）：车间距增加1";
CM_ SG_ 801 Reserved_MFS_Shift_Down "预留";
CM_ SG_ 801 Reserved_MFS_Shift_Up "预留";
CM_ SG_ 801 MFS_SETMinus "短按：进入巡航，巡航以1km/h减小；
长按：巡航速度持续减小，以10km/h为止;";
CM_ SG_ 801 MFS_RESPlus "短按：恢复巡航，巡航以1km/h增加；
长按：巡航速度持续增加，以10km/h为止;";
CM_ SG_ 801 MFS_Cancel "暂时退出巡航（ACC配置）";
CM_ SG_ 801 MFS_Seepd_Limit "电子限速";
CM_ SG_ 801 MFS_Cruise_Control "进入预巡航/退出预巡航
Feedback:
0x0FA:
EMS_1_CruiseControlStatus
0x4B2:GSM_GearShiftPos
ACC_Cruise_Control";
CM_ SG_ 801 ALIVE_MFS_2 "计数";
CM_ SG_ 801 CRC "CRC";
CM_ BO_ 1035 "PHEV";
CM_ SG_ 1035 IHU_10_CRC "SAE J1850 CRC-8";
CM_ SG_ 1035 IHU_10_MessageCounter "Alivecounter";
CM_ SG_ 1035 IHU_OTAHvReq "OTA high voltage power down request";
CM_ SG_ 1035 IHU_OTASts "OTA status";
CM_ SG_ 1058 IHU_21_Random_showLamp_SW "随机音乐灯光秀开关";
CM_ SG_ 1058 IHU_21NavigationalTurnType "导航转向类型";
CM_ SG_ 1058 IHU_21AssociatedNavigationModeSw "关联导航模式开关";
CM_ SG_ 1058 IHU_21MessageCounter "同步信号";
CM_ SG_ 1058 IHU_21VoiceBroadcast "语音播报";
CM_ SG_ 1058 IHU_21VoiceWake "语音唤醒信号";
CM_ SG_ 1058 IHU_21_FatigueDrivingReminder_Se "疲劳驾驶提示设置";
CM_ SG_ 1058 IHU_21_OverspeedAlarm_Set "超速报警设置";
CM_ SG_ 1058 IHU_ICMBrightnessManualAdj "仪表亮度手动调节
Feedback:0x530:ICM_4_BrightnessFed";
CM_ SG_ 1058 IHU_SET_ICMBrightnessMode "设置仪表亮度调节模式";
CM_ SG_ 1058 IHU_LockAnimation "闭锁动画";
CM_ SG_ 1058 IHU_UnlockAnimation "解锁动画";
CM_ SG_ 1058 IHU_FatigueDriving "疲劳驾驶";
CM_ SG_ 1058 IHU_SmartSceneMode "智能场景模式
0x1:赛道模式
0x2:舒享模式(休息模式、主驾驶）
0x3:女王模式(副驾)
0x4:智能健康座舱模式
0x5:看护模式
0x6:冥想模式
0xF:场景模式关闭";
CM_ BO_ 1069 "HCU开关";
CM_ SG_ 1069 IHU_TimeToStopChargeHourSet "预约充电时间设置";
CM_ SG_ 1069 IHU_TimeToStartChargeMinuteSet "预约充电时间设置";
CM_ SG_ 1069 IHU_TimeToStartChargeHourSet "预约充电时间设置";
CM_ SG_ 1069 IHU_ChargeModeSet "充电模式设置开关";
CM_ SG_ 1069 IHU_SetSocManage "电量模式切换开关";
CM_ SG_ 1069 Set_AVASFuntion "行人提示设置开关";
CM_ SG_ 1069 IHU_SetSOC "SOC设置开关
发3次，间隔20ms，之后发3帧Not_ActiveIHU在Save、charge模式下显示的目标电池电量SOC与真实SOC对应关系如下表所示：

IHU_SetSOC信号取值  HCU_SetSOCFed信号取值 对应IHU显示的SOC 对应HCU真实SOC
      0x1            0x0             20%        30%
      0x2            0x1             30%        39%
      0x3            0x2             40%         47%
      0x4            0x3             50%         55%
      0x5            0x4             60%         63%
      0x6            0x5             70%          71%";
CM_ BO_ 901 "HCU开关及启停设置(原BCM_15)";
CM_ SG_ 901 CTP_PowerModeSet "动力模式切换";
CM_ SG_ 901 ISS_Switch "启停开关状态";
CM_ BO_ 1399 "PHEV HCU设置";
CM_ SG_ 1399 Refuel_Requset "油箱盖请求开启信号";
CM_ SG_ 1407 SET_IHU_ACMAXReq "AC MAX请求信号
Feedback:0x5FF:
CEM_IPM_3_ACMAXReq_Sts";
CM_ SG_ 1407 IHU15_MessageCounter "计数";
CM_ SG_ 1407 IHU_SpeechControl "当前车机指令状态";
CM_ SG_ 1407 SET_Mirror_Fold_Switch "后视镜折叠开关
Feedback:0x5C4：CEM_Mirror Fold_switchSts";
CM_ SG_ 1407 SET_Passenger_Mirror_Location "副驾座椅记忆
Feedback:0x53C：
RBCM__Psngrseat_location";
CM_ SG_ 1407 SET_Driver_Mirror_Location "外后视镜及主驾座椅记忆
Feedback:0x5C4：
CEM_Mirror_Driverseat_location";
CM_ SG_ 1407 SET_IPM_Automatic_Ventilation "座舱自动换气
Feedback:0x51A:
CEM_IPM_Automatic_Ventilation";
CM_ SG_ 1407 SET_Mirror_Flip_CFG "外后视镜倒车翻转设置
Feedback:0x5C4：
CEM_MirrorFlip_CFGSts";
CM_ SG_ 1407 SET_RightMirrorCtrl "右后视镜镜片控制
Feedback:0x5C4:
CEM_RightMirrorCtrlSts";
CM_ SG_ 1407 SET_LeftMirrorCtrl "左后视镜镜片控制
Feedback:0x5C4:
CEM_LeftMirrorCtrlSts";
CM_ SG_ 1407 SET_IPMCustom_Air_Conditioning "自定义空调
Feedback:0x51A:
CEM_IPM_Custom_Air_Conditioning";
CM_ SG_ 1407 SET_FRSeatHeatVentSwReq "副驾温度及通风设置
Feedback:0x51A:
CEM_IPM_FRSeatHeatVentSwSts";
CM_ SG_ 1407 SET_FLSeatHeatVentSwReq "主驾温度及通风设置
Feedback:0x51A:
CEM_IPM_FLSeatHeatVentSwSts";
CM_ SG_ 1400 SET_Passenger_Welcome_Seat "座椅迎宾礼让开关";
CM_ SG_ 1400 RSeatBeltBuckleSwitch "后排座椅安全带未系开关
Feedback:0x452:
ICM_2_RSeatBeltBuckleSwitchSts";
CM_ SG_ 1400 Sound_Options_Signal "声音选择信号
Feedback:0x401:
Welcome_OutsoundSts";
CM_ SG_ 1400 Welcome_Sound_Device_Switching_S "迎宾装置开关信号
Feedback:0x401:
Welcome_Outsound_SwitchSts";
CM_ SG_ 1400 SET_Wiper_Sensitivity "雨刮灵敏度
需要大屏记忆
Feedback:0x392:CEM_2_WiperSensitivitySWSts";
CM_ SG_ 1400 SET_Tunnel_lamp "隧道灯是否开启
需要大屏记忆";
CM_ SG_ 1400 IHU_14_SET_Rearfoglight "后雾灯命令开关
需要大屏记忆
Feedback:0x392:CEM_2_RearFogLightSts";
CM_ SG_ 1400 IHU_14_SET_Lightcontrol "灯光模式控制
需要大屏记忆";
CM_ BO_ 1401 "域控事件设置（座椅及灯光设置）";
CM_ SG_ 1401 IHU13_MessageCounter "计数";
CM_ SG_ 1401 SET_Welcome_Seat "座椅迎宾礼让开关
Feedback:0x5FF:
CEM_3_Welcome_Seat_Sts";
CM_ SG_ 1401 SET_MFS_Shake "方向盘震动
Feedback:0x53C:
RBCM_MFS_ShakeSts";
CM_ SG_ 1401 SET_MFS_Heat "方向盘加热
Feedback:0x53C:
RBCM_MFS_HeatSts";
CM_ SG_ 1401 SET_UnderVoltage "亏电提醒
Feedback:0x5C4:
CEM_UnderVoltageSts";
CM_ SG_ 1401 SET_RearWiper_Switch "后雨刮倒车自动开启
Feedback:0x5C4:
CEM_RearWiper_SwitchSts";
CM_ SG_ 1401 SET_Wiper_Maintenance "雨刮维修模式
Feedback:0x5C4:CEM_Wiper_MaintenanceSts";
CM_ SG_ 1401 SET_Abat_VentCMD "遮阳帘开启百分制命令
Feedback:0x5E0:
CEM_Abat_VentCMDSts";
CM_ SG_ 1401 SET_PSRFCMD "天窗开启百分制命令
Feedback:0x5E0：
CEM_PSRFCMDSts";
CM_ SG_ 1401 SET_Massagemode "副驾按摩模式设置
Feedback:0x53C:
RBCM_massagemodeSts";
CM_ SG_ 1401 SET_Vibrationmode "副驾按摩强度设置
Feedback:0x53C:
RBCM_passageVibrationSts";
CM_ SG_ 1401 SET_Passenger_Massage "副驾按摩开关
Feedback:0x53C:
RBCM_Passenger_massageSts";
CM_ SG_ 1401 SET_PLG_Control "电尾门开启请求
Feedback:0x436:
PLG_1_RearDoorStatus,PLG_1_RearDoorMoveDir";
CM_ SG_ 1401 SET_Doorkonbmode "门把手是否自动弹出请求
Feedback:0x5EE：
CEM_DHM_Doorkonbmode_Feedback";
CM_ SG_ 1401 SET_Doorkonb_time "门把手收回时间请求
Feedback:0x5E3:
DHM_1_Doorkonb_Time_Freeback";
CM_ SG_ 1401 SET_Driver_unlockmode "驾驶员解锁模式请求
Feedback:0x5EE:
CEM_DHM_Driver_unlockmode_feedback";
CM_ SG_ 1401 SET_Smart_LowBeam "智能大灯使能开关
Feedback:0x5C4：
CEM_Smart_HighBeamSts";
CM_ SG_ 1401 SET_LowBeam_Adjust "大灯高度调节请求
Feedback:0x5C4：
CEM_HighBeam_adjustSts";
CM_ SG_ 1335 IHU_9_IHUResolutionX "屏幕分辨率X轴";
CM_ SG_ 1335 IHU10_NavSts "导航状态
导航是否开启，给HCU智能电量模式使用";
CM_ SG_ 1335 IHU_9_IHUResolutionY "屏幕分辨率Y轴";
CM_ SG_ 1335 IHU_9_NavCurrRoadType "Nav道路类型";
CM_ SG_ 1335 IHU_9_ECOModeSWSts "ECO模式干式6DCT预留拆帧路由
Feedback:0x301:DriveMode";
CM_ SG_ 1335 IHU_9_DriveMode_6DCT_wet "驾驶模式开关湿式6DCT专用拆帧路由
Feedback:0x301:DriveMode";
CM_ SG_ 1335 IHU_9_DriveMode "驾驶模式开关
Feedback:0x301:DriveMode";
CM_ SG_ 1335 IHU_9_NavSpeedLimitUnits "Nav速度限制单位";
CM_ SG_ 1335 IHU_9_NavSpeedLimit "Nav速度限制";
CM_ SG_ 1335 IHU_9_NavSpeedLimitStatus "Nav速度限制状态";
CM_ SG_ 1309 Child_Safety_Lock "儿童锁开关";
CM_ SG_ 1309 SET_PAS_Switch "前雷达开关
Feedback:0x440:RAD1_Pas_Switch";
CM_ SG_ 1309 CGW_DVDSET_IPBAssociateDriveMode "制动踏板感关联驾驶模式请求";
CM_ SG_ 1309 CGW_CST_SensitivityReq "制动俯仰控制灵敏度请求";
CM_ SG_ 1309 ESCOFF_ON_OFF "车身稳定控制系统关闭ESC—OFF开关";
CM_ SG_ 1309 HDC_ON_OFF "陡坡缓降AVH开关";
CM_ SG_ 1309 AVH_ON_OFF "自动驻车AUTO_HOLD开关
add_Last_Memory";
CM_ SG_ 1309 IHU_CGW_BrakepedalfeelModeSetReq "制动踏板感模式设置请求";
CM_ SG_ 1309 IHU_8_CGW_Set_CSTFunctionSts "制动俯仰控制CST功能开关";
CM_ SG_ 1309 IHU_8_LDWLKA_LaneAssit_TypeReq "车道偏离预警_车道保持辅助选择
需要大屏记忆
Feedback:0x307:
FCM_2_LDWLKA_LaneAssitfeedback";
CM_ SG_ 1309 IHU_8_SLAOnOffReq "限速标识识别开关请求
Feedback:0x307:
FCM_2_SLAOnOffsts";
CM_ SG_ 1309 IHU_8_HMAOnOffReq "DVD上软开关HMA funtion switch signal
Feedback:0x307:
FCM_2_HMAOnOffsts";
CM_ SG_ 1309 IHU_8_LDW_LKA_SensitivityReq "LDW灵敏度
Feedback:0x307:
FCM_2_LDWLKA_Sensitivityfeedback";
CM_ SG_ 1309 IHU_8_TimeGapLastSetReq "时距设置请求开关
Feedback:0x305:
FRM_3_TimeGapLastSet_DVD";
CM_ SG_ 1309 IHU_8_DistanceWarning_On_Off "安全距离报警开关
Feedback:0x305:
FRM_3_DistanceWarning_On_Off_Sts";
CM_ SG_ 1309 IHU_8_TJA_ICA_ON_OFF "交通拥堵辅助—自适应巡航辅助开关
Feedback:0x307:
FCM_2_TJA_ICA_ON_OFF_Sts";
CM_ SG_ 1309 IHU_8_AEB_ON_OFF "自动紧急制动开关
Feedback:0x305:
FRM_3_AEB_ON_OFF_Sts";
CM_ SG_ 1309 IHU_8_FCW_OPTION "前碰撞预警灵敏度
Feedback:0x305:
FRM_3_FCW_OPTION_Sts";
CM_ SG_ 1309 IHU_8_FCW_ON_OFF "前碰撞预警开关—AEB
Feedback:0x305:
FRM_3_FCW_ON_OFF_Sts";
CM_ SG_ 1309 IHU_8_TimeGapSet1Req "跟车时距信号设置
Feedback:0x305:
FRM_3_TimeGapSet_DVD";
CM_ SG_ 1107 IHU_7_CurrentTimeYear "年";
CM_ SG_ 1107 IHU_7_CurrentTimeMonth "月";
CM_ SG_ 1107 IHU_7_CurrentTimeDay "日";
CM_ SG_ 1107 IHU_7_CurrentTimeSecond "秒";
CM_ SG_ 1107 IHU_7_CurrentTimeMinute "分";
CM_ SG_ 1107 IHU_7_CurrentTimeHour "小时";
CM_ SG_ 1344 IHU_6_AmbientLight_SceneMode "氛围灯关联智能场景开关
Feedback:0x490:
CEM_ALM_1_SceneMode_ControlSwitch";
CM_ SG_ 1344 IHU_6_SET_MusicLoudness_6000HZ "均衡器设置
当前60000HZ音乐律动，当前6000HZ颜色及亮度调节";
CM_ SG_ 1344 IHU_6_SET_MusicLoudness_2000HZ "均衡器设置
当前2000HZ音乐律动，当前2000HZ颜色及亮度调节";
CM_ SG_ 1344 IHU_6_SET_MusicLoudness_1500HZ "均衡器设置
当前1500HZ音乐律动，当前1500HZ颜色及亮度调节";
CM_ SG_ 1344 IHU_6_SET_MusicLoudness_1000HZ "均衡器设置
当前1000HZ音乐律动，当前1000HZ颜色及亮度调节";
CM_ SG_ 1344 IHU_6_SET_MusicLoudness_500HZ "均衡器设置
当前500HZ音乐律动，当前500HZ颜色及亮度调节";
CM_ SG_ 1344 IHU_6_SET_MusicLoudness_250HZ "均衡器设置
当前250HZ音乐律动，当前250HZ颜色及亮度调节";
CM_ SG_ 1344 IHU_6_SET_MusicLoudness_120HZ "均衡器设置
当前120HZ音乐律动，当前120HZ颜色及亮度调节";
CM_ SG_ 1344 IHU_6_SET_Apiluminance "氛围灯亮度
Feedback:0x490:
CEM_ALM_1_STAT_Apiluminance";
CM_ SG_ 1344 IHU_6_SET_DMSMonitoring "DMS监测开关
Feedback:0x490:
CEM_ALM_1_STAT_DMSMonitoring";
CM_ SG_ 1344 IHU_6_SET_PM2_5Monitoring "PM2.5监测开关
Feedback:0x490:
CEM_ALM_1_STAT_PM2_5Monitoring";
CM_ SG_ 1344 IHU_6_SET_DriveApiluminance "行驶中氛围灯亮度
Feedback:0x490:
CEM_ALM_1_STAT_DriveApiluminance";
CM_ SG_ 1344 IHU_6_SET_64Colour "多元颜色设置
Feedback:0x490:CEM_ALM_1_STAT_64Colour";
CM_ SG_ 1344 IHU_6_SET_Static_Colour "静态颜色
Feedback:0x490:
CEM_ALM_1_STAT_Static_Colour";
CM_ SG_ 1344 IHU_6_SET_StaticEffect "静态效果
Feedback:0x490:
CEM_ALM_1_STAT_StaticEffect";
CM_ SG_ 1344 IHU_6_SET_ControlSwitch "氛围灯关联背光开关
Feedback:0x490:
CEM_ALM_1_STAT_ControlSwitch";
CM_ SG_ 1344 IHU_6_SET_WelcomeWaterLamp "氛围灯迎宾欢送
Feedback:0x490:
CEM_ALM_1_STAT_WelcomeWaterLamp";
CM_ SG_ 1344 IHU_6_SET_AssociatedWithDriverMo "关联驾驶模式开关
Feedback:0x490:
CEM_ALM_1_STAT_AssociatedWithDriverMode";
CM_ SG_ 1344 IHU_6_SET_Music "当前播放的音乐是否允许音乐律动
Feedback:0x490:CEM_ALM_1_STAT_Music";
CM_ SG_ 1327 IHU_5_UVC_LuminanceReq "杀菌强度请求
Feedback:0x5FF：CEM_3_SterilzeStrengthReq_Sts";
CM_ SG_ 1327 IHU_5_UVC_ControlReq "紫外线杀菌灯请求
Feedback:0x5FF：CEM_3_UVLampReq_Sts";
CM_ SG_ 1327 IHU_5_PM25DisplayToggle "PM2.5内外显示切换
Feedback:0x5FF：CEM_3_PM25DisplayToggle_Sts";
CM_ SG_ 1327 IHU_5_DVD_DWMCon_Req "天窗控制信号
Feedback:0x5FF:CEM_3_DWM_Sts_Msg";
CM_ SG_ 1327 IHU_5_SyncSwtich_Req "同步开关请求
Feedback:0x51A:CEM_IPM_SyncSts";
CM_ SG_ 1327 IHU_5_L_Set_Temperature "主驾侧温度设置
Feedback:0x51A:CEM_IPM_FLTempsts";
CM_ SG_ 1327 IHU_5_R_Set_Temperature "副驾侧温度设置
Feedback:0x51A:CEM_IPM_FRTempsts";
CM_ SG_ 1327 IHU_5_AnionPurify_Req "负离子净化
Feedback:0x51A:CEM_IPM_AnionPurify";
CM_ SG_ 1327 IHU_5_AutoState "空调自动模式设置
Feedback: 0x51A:CEM_IPM_FrontAutoACSts";
CM_ SG_ 1327 IHU_5_EngineControlEDReq "语音启动发动机
Feedback: 0x5FF：CEM_3_EngineControlSts";
CM_ SG_ 1327 IHU_5_RRWindowCon_Req "右后窗玻璃控制
Feedback:0x58D：CEM_4_RR_WIN_Position";
CM_ SG_ 1327 IHU_5_LRWindowCon_Req "左后窗玻璃控制
Feedback:0x58D：CEM_4_LR_WIN_Position";
CM_ SG_ 1327 IHU_5_FLWindowCon_Req "左前窗玻璃控制
Feedback:0x58D：CEM_4_FL_WIN_Position";
CM_ SG_ 1327 IHU_5_FRWindowCon_Req "右前窗玻璃控制
Feedback:0x58D：CEM_4_FR_WIN_Position";
CM_ SG_ 1327 IHU_5_Control_Mode_Req "空调冷暖控制模式";
CM_ SG_ 1327 IHU_5_TempknobRollingCounterReq "电动空调
Feedback:0x51A:
CEM_IPM_TempknobRollingCounter";
CM_ SG_ 1327 IHU_5_RearDefrostSwitch_Req "后除霜请求
Feedback:0x51A:
CEM_IPM_RearDefrosts";
CM_ SG_ 1327 IHU_5_FrontOFF_Req "空调工作状态请求
Feedback:0x51A:
CEM_IPM_FrontOFFSts";
CM_ SG_ 1327 IHU_5_CirculationMode_Req "内外循环
Feedback:0x51A:
CEM_IPM_RecyMode";
CM_ SG_ 1327 IHU_5_ModeAdjust_Req "空调吹风模式调节请求
Feedback:0x51A:
CEM_IPM_FrontBlowModeSts";
CM_ SG_ 1327 IHU_5_BlowSpeedLevel_Req "鼓风机转速请求
Feedback:0x51A:
CEM_IPM_FrontBlowSpdCtrlsts,CEM_IPM_RearBlowSpdCtrlSts";
CM_ SG_ 1325 IHU_4_DATA7 "此字节为数据帧；
其中当功能ID=0x31时，DATA5-7为距离下一个路口距离，距离（Unit24），单位米；";
CM_ SG_ 1325 IHU_4_DATA6 "此字节为数据帧；
其中当功能ID=0x31时，DATA5-7为距离下一个路口距离，距离（Unit24），单位米；";
CM_ SG_ 1325 IHU_4_DATA5 "此字节为数据帧；
其中当功能ID=0x31时，DATA5-7为距离下一个路口距离，距离（Unit24），单位米；";
CM_ SG_ 1325 IHU_4_DATA4 "此字节为数据帧；
其中当功能ID=0x31时，DATA3_4为导航引导图标信息；
导航引导图标:
_0:NO_Info；
_1-100:导航引导信息列表；
_101--:预留；";
CM_ SG_ 1325 IHU_4_DATA3 "当PCItype=0时，此字节为数据帧，其中当功能ID=0x31时，DATA3_4为导航引导图标信息；
当PCItype=1时，此字节为有效数据长度；
当PCItype=2时，此字节数据帧；
有效数据长度:
不包含功能ID_BYTE，不包含有效数据长度BYTE，不包含每帧Byte0；
导航引导图标:
_0:NO_Info；
_1-100:导航引导信息列表；
_101--:预留；";
CM_ SG_ 1325 IHU_4_DATA2 "当PCItype=0时，此字节为有效数据长度；
当PCItype=1时，此字节为功能ID；
当PCItype=2时，此字节数据帧；

功能ID:
连接请求指令:0x01；交互显示信息清除指令:0x03；下一个街道、道路:0x30；导航信息:0x31；歌曲名称:0x50；演唱者:0x51；通话人电话号码:0x70；通话人名称:0x71；通话信息:0x72；
有效数据长度:
不包含功能ID_BYTE，不包含有效数据长度BYTE，不包含每帧Byte0；";
CM_ SG_ 1325 IHU_4_DATA1 "当PCItype=0时，此字节为功能ID；
当PCItype=1时，此字节为连续帧中的数据总个数；
当PCItype=2时，此字节为数据帧；

功能ID:
连接请求指令:0x01；交互显示信息清除指令:0x03；下一个街道、道路:0x30；导航信息:0x31；歌曲名称:0x50；演唱者:0x51；通话人电话号码:0x70；通话人名称:0x71；通话信息:0x72；
数据总个数:
含功能ID_BYTE及有效数据长度BYTE，不包含每帧Byte0；";
CM_ SG_ 1325 IHU_4_F_DL "当PCItype=0时，F_DL表示帧内数据总个数；
当PCItype=1时，F_DL=0X0；
当PCItype=2时，F_DL表示代表此帧为连续帧中的第几帧；
当PCItype=3时，F_DL表示代表发送端是否能继续传输数据；
数据总个数:含功能ID_BYTE及有效数据长度BYTE，不包含每帧Byte0；";
CM_ SG_ 1325 IHU_4_PCItype "PCI类型";
CM_ SG_ 1303 IHU_3_Set_Default "初始化指令
0x1:初始化个性化关联的功能
0x2:初始化所有功能";
CM_ SG_ 1303 IHU_3_DVD_SetScreen "画面设置";
CM_ SG_ 1303 IHU_3_DVD_SetWorkModeSts "大屏设置显示模式";
CM_ SG_ 1303 IHU_3_DVD_OP_TP_Y "Y轴坐标值";
CM_ SG_ 1303 IHU_3_DVD_OP_TP_X "X轴坐标值";
CM_ SG_ 1303 IHU_3_DVD_DefDispMode "AVM 2D和3D视图切换";
CM_ SG_ 1303 IHU_3_BT_PHONE_Sts "大屏电话状态";
CM_ SG_ 1303 IHU_3_DVD_Set_RCW "后碰撞报警设置
Feedback:0x449:SRR_1_RCWSts";
CM_ SG_ 1303 IHU_3_DVD_Set_DOW "开门预警功能设置
Feedback:0x449:SRR_1_DOWSts";
CM_ SG_ 1303 IHU_3_DVD_Set_RadarWarining "大屏设置雷达报警";
CM_ SG_ 1303 IHU_3_AVM_SET_LANG "设置语言格式";
CM_ SG_ 1303 IHU_3_AVM_OP_VIEW_DVR_SW "开启关闭AVM/DVR命令";
CM_ SG_ 1303 IHU_3_DVD_Set_SteeringWheel "大屏设置方向盘";
CM_ SG_ 1303 IHU_3_BSDSwitch "设置BSD功能开关状态
Feedback:0x449:SRR_1_BSDState";
CM_ SG_ 1303 IHU_3_LDWSwitch "设置LDW功能开关状态";
CM_ SG_ 1303 IHU_3_CalibrationRequest "进入标定请求";
CM_ SG_ 1303 IHU_APA_OP_SW "APA在大屏上的软开关";
CM_ SG_ 1302 IHU_2_Trip2Reset "小计里程2清零
Feedback:0x4E0:ICM_6_Trip2back";
CM_ SG_ 1302 IHU_2_Trip1Reset "小计里程1清零
Feedback:0x4E0:ICM_6_Trip1back";
CM_ SG_ 1302 IHU_2_IHULanguageSet "大屏设置语言
Feedback:0x530:
ICM_4_ICMLanguageSet";
CM_ SG_ 1302 IHU_2_IHU_Set_Theme "大屏设置主题
Feedback:0x530:
ICM_4_ThemeSys";
CM_ SG_ 1302 IHU_2_FrequencySts "当前收音机频率";
CM_ SG_ 1302 IHU_2_KnobSts "音量旋钮";
CM_ SG_ 1302 IHU_2_AMRadioFrequanceValue "AM调频频率信号
If_IHU_Is_Off_Or_Event_Of_This_Signal_Isn’t_Happen_This_Signal_Value_Shall_Be_0x0000_(Not_Active)";
CM_ SG_ 1302 IHU_2_FMRadioFrequanceValue "FM调频频率信号
If_IHU_Is_Off_Or_Event_Of_This_Signal_Isn’t_Happen_This_Signal_Value_Shall_Be_0x0000_(Not_Active)";
CM_ SG_ 1302 IHU_2_IHUOnSts "音响主机是否开机信号";
CM_ SG_ 1302 IHU_2_SourceStationMode "播放模式信号
If_IHU_Is_Off_Or_Event_Of_This_Signal_Isn’t_Happen_This_Signal_Value_Shall_Be_000_(Not_Active)";
CM_ SG_ 1302 IHU_2_RadioResearchSts "收音机状态信号";
CM_ SG_ 1302 IHU_2_RadioFrequanceMode "收音频率模式信号";
CM_ SG_ 1301 IHU_1_SET_DWD_Req "涉水雷达开关";
CM_ SG_ 1301 IHU_1_RegenerateLevelCtrl "能量回收等级调节+/-";
CM_ SG_ 1301 IHU_1_DVD_SetFraganceTime "0=无请求,默认值；Taste1 与装香装置 A对应，Taste2 与装香装 置 B 对应, Taste3 与装香装置 C 对应，重置后香氛剩余量为 100%；";
CM_ SG_ 1301 DVD_Set_FraganceConcentration "0=不动作,默认值；
1=低浓度，
2=中浓度，
3=高浓度；
Feedback:0x560:FRAG_FraganceConcentration";
CM_ SG_ 1301 IHU_1_DVD_Set_FraganceTaste "0=不动作,默认值；
Taste1与装香装置 A 对应，
Taste2 与装香装置 B对应, 
Taste3 与装香装置 C 对应
Feedback:0x560:FRAG_FraganceTaste";
CM_ SG_ 1301 IHU_1_DVD_Set_FraganceSwitchSt "0=关闭，默认值，此时香氛不响应下述香味选择、浓度选择请求； 
1=打开，与下面香味选择、浓度选择可同步发出；
Feedback:0x560:FRAG_FraganceSwitchResp";
CM_ SG_ 1301 IHU_1_DVD_SET_PLG_SAS "设置后背门的开启角度
Feedback:0x436:PLG_1_SAS_Sts";
CM_ SG_ 1301 IHU_1_DVD_Set_External_Welcome_L "外部灯光迎宾
Feedback:0x392:CEM_2_External_WelcomelightSts";
CM_ SG_ 1301 IHU_1_DVD_Set_Show_Mode "灯光秀激活开关";
CM_ SG_ 1301 IHU_1_DVD_SET_Polling "迎宾模式
Feedback:0x480：
CEM_PEPS_Polling_Sts";
CM_ SG_ 1301 IHU_1_DVD_SET_IPM_First_Blowing "大屏设置空调启动时第一口风
Feedback:0x51A:
CEM_IPM_First_BlowingSts";
CM_ SG_ 1301 IHU_1_DVD_SET_IPM_Blower_Delay "大屏设置车辆熄火空调鼓风机延时
Feedback:0x51A:
CEM_IPM_Blower_DelaySts";
CM_ SG_ 1301 IHU_DVD_SET_BT_Reduce_Wind_Speed "大屏设置蓝牙通话降低风速
Feedback:0x51A:
CEM_IPM_BT_Reduce_Wind_SpeedSts";
CM_ SG_ 1301 IHU_1_DVD_SET_RemoteLockFeedback "设防提示状态
Feedback：0x392：
CEM_2_RemoteLockFeedbackSts";
CM_ SG_ 1301 IHU_1_DVD_SET_EPSmode "显示EPS_禁止模式转换
Feedback: 0x380:
EPS_1_EPSModeSts";
CM_ SG_ 1301 IHU_1_DVD_Set_Wash_Car "洗车模式开启和关闭开关
Feedback:0x490：
CEM_ALM_1_Wash_Car_Status";
CM_ SG_ 1301 IHU_1_DVD_Set_12_24_Hour "大屏设置时制";
CM_ SG_ 1301 IHU_1_DVD_SET_Blankingnumber "设置变道闪光功能每次激活闪烁的次数
Feedback:0x392:
CEM_2_BlankingnumberSts";
CM_ SG_ 1301 IHU_1_DVD_SET_AutoUnlockSts "设置熄火自动解锁功能是否存在
Feedback:0x392：
CEM_2_AutoUnlockSts";
CM_ SG_ 1301 IHU_1_DVD_SET_AutoLockSts "设置超速落锁功能是否存在
Feedback:0x392：
CEM_2_AutoLockSts";
CM_ SG_ 1301 IHU_1_DVD_SET_AidTurningIllumina "设置辅助转向照明模式
Feedback:0x392：CEM_2_AidTurningIlluminationSts";
CM_ SG_ 1301 IHU_1_DVD_SET_FollowMeHome "伴我回家功能
Feedback:0x392：CEM_2_FollowMeHomeTimeSts";
CM_ SG_ 1301 IHU_1_DVD_SET_Mirror_Fold "大屏设置上锁自动折叠
Feedback:0x392：CEM_2_Mirror_Fold_Sts";
BA_DEF_ SG_  "GenSigTimeoutValue" INT 0 2147483647;
BA_DEF_ SG_  "GenSigStartValue" INT 0 2147483647;
BA_DEF_ SG_  "GenSigInactiveValue" INT 0 2147483647;
BA_DEF_ BO_  "TpTxIndex" INT 0 255;
BA_DEF_ BO_  "DiagUudtResponse" ENUM  "False","True";
BA_DEF_ BO_  "DiagResponse" ENUM  "No","Yes";
BA_DEF_ BO_  "DiagRequest" ENUM  "No","Yes";
BA_DEF_ BO_  "DiagState" ENUM  "No","Yes";
BA_DEF_ BO_  "NmAsrMessage" ENUM  "No","Yes";
BA_DEF_ BO_  "GenMsgFastOnStart" INT 0 65535;
BA_DEF_ BO_  "GenMsgCycleTimeFast" INT 0 65535;
BA_DEF_ BO_  "GenMsgNrOfRepetition" INT 0 65535;
BA_DEF_ BO_  "GenMsgStartDelayTime" INT 0 65535;
BA_DEF_ BO_  "GenMsgCycleTime" INT 0 65535;
BA_DEF_ BO_  "GenMsgDelayTime" INT 0 65535;
BA_DEF_ SG_  "GenSigSendType" ENUM  "Cyclic","OnWrite","OnWriteWithRepetition","OnChange","OnChangeWithRepetition","IfActive","IfActiveWithRepetition","NoSigSendType","OnChangeAndIfActive","OnChangeAndIfActiveWithRepetition";
BA_DEF_ BO_  "GenMsgSendType" ENUM  "Cyclic","NotUsed","NotUsed","NotUsed","NotUsed","NotUsed","NotUsed","IfActive","NoMsgSendType";
BA_DEF_ BO_  "GenMsgILSupport" ENUM  "No","Yes";
BA_DEF_ SG_  "SystemSignalLongSymbol" STRING ;
BA_DEF_REL_ BU_SG_REL_  "GenSigTimeoutTime" INT 0 65535;
BA_DEF_DEF_  "GenSigTimeoutValue" 0;
BA_DEF_DEF_  "GenSigStartValue" 0;
BA_DEF_DEF_  "GenSigInactiveValue" 0;
BA_DEF_DEF_  "TpTxIndex" 0;
BA_DEF_DEF_  "DiagUudtResponse" "False";
BA_DEF_DEF_  "DiagResponse" "No";
BA_DEF_DEF_  "DiagRequest" "No";
BA_DEF_DEF_  "DiagState" "No";
BA_DEF_DEF_  "NmAsrMessage" "No";
BA_DEF_DEF_  "GenMsgFastOnStart" 0;
BA_DEF_DEF_  "GenMsgCycleTimeFast" 0;
BA_DEF_DEF_  "GenMsgNrOfRepetition" 3;
BA_DEF_DEF_  "GenMsgStartDelayTime" 0;
BA_DEF_DEF_  "GenMsgCycleTime" 0;
BA_DEF_DEF_  "GenMsgDelayTime" 0;
BA_DEF_DEF_  "GenSigSendType" "Cyclic";
BA_DEF_DEF_  "GenMsgSendType" "Cyclic";
BA_DEF_DEF_  "GenMsgILSupport" "No";
BA_DEF_DEF_REL_ "GenSigTimeoutTime" 0;
BA_DEF_DEF_  "SystemSignalLongSymbol" "";
BA_ "GenMsgILSupport" BO_ 1535 1;
BA_ "GenMsgCycleTimeFast" BO_ 1535 500;
BA_ "GenMsgCycleTime" BO_ 1535 500;
BA_ "GenMsgILSupport" BO_ 914 1;
BA_ "GenMsgNrOfRepetition" BO_ 914 0;
BA_ "GenMsgCycleTime" BO_ 914 20;
BA_ "GenMsgILSupport" BO_ 1340 1;
BA_ "GenMsgNrOfRepetition" BO_ 1340 2;
BA_ "GenMsgCycleTimeFast" BO_ 1340 50;
BA_ "GenMsgCycleTime" BO_ 1340 1000;
BA_ "GenMsgILSupport" BO_ 1306 1;
BA_ "GenMsgNrOfRepetition" BO_ 1306 0;
BA_ "GenMsgCycleTime" BO_ 1306 100;
BA_ "GenMsgILSupport" BO_ 952 1;
BA_ "GenMsgNrOfRepetition" BO_ 952 0;
BA_ "GenMsgCycleTime" BO_ 952 100;
BA_ "GenMsgILSupport" BO_ 1381 1;
BA_ "GenMsgNrOfRepetition" BO_ 1381 0;
BA_ "GenMsgCycleTime" BO_ 1381 500;
BA_ "GenMsgILSupport" BO_ 1376 1;
BA_ "GenMsgNrOfRepetition" BO_ 1376 0;
BA_ "GenMsgCycleTime" BO_ 1376 500;
BA_ "GenMsgILSupport" BO_ 1405 1;
BA_ "GenMsgSendType" BO_ 1405 8;
BA_ "GenMsgNrOfRepetition" BO_ 1405 2;
BA_ "GenMsgCycleTimeFast" BO_ 1405 100;
BA_ "GenMsgILSupport" BO_ 1389 1;
BA_ "GenMsgSendType" BO_ 1389 8;
BA_ "GenMsgNrOfRepetition" BO_ 1389 2;
BA_ "GenMsgCycleTimeFast" BO_ 1389 100;
BA_ "GenMsgILSupport" BO_ 801 1;
BA_ "GenMsgSendType" BO_ 801 8;
BA_ "GenMsgCycleTimeFast" BO_ 801 50;
BA_ "GenMsgNrOfRepetition" BO_ 801 2;
BA_ "GenMsgILSupport" BO_ 1035 1;
BA_ "GenMsgNrOfRepetition" BO_ 1035 0;
BA_ "GenMsgCycleTime" BO_ 1035 100;
BA_ "GenMsgILSupport" BO_ 1058 1;
BA_ "GenMsgNrOfRepetition" BO_ 1058 0;
BA_ "GenMsgCycleTime" BO_ 1058 100;
BA_ "GenMsgILSupport" BO_ 1069 1;
BA_ "GenMsgSendType" BO_ 1069 8;
BA_ "GenMsgNrOfRepetition" BO_ 1069 2;
BA_ "GenMsgCycleTimeFast" BO_ 1069 100;
BA_ "GenMsgILSupport" BO_ 901 1;
BA_ "GenMsgCycleTime" BO_ 901 50;
BA_ "GenMsgCycleTimeFast" BO_ 901 50;
BA_ "GenMsgNrOfRepetition" BO_ 901 2;
BA_ "GenMsgILSupport" BO_ 1399 1;
BA_ "GenMsgSendType" BO_ 1399 8;
BA_ "GenMsgNrOfRepetition" BO_ 1399 2;
BA_ "GenMsgCycleTimeFast" BO_ 1399 100;
BA_ "GenMsgILSupport" BO_ 1407 1;
BA_ "GenMsgNrOfRepetition" BO_ 1407 2;
BA_ "GenMsgCycleTimeFast" BO_ 1407 100;
BA_ "GenMsgCycleTime" BO_ 1407 1000;
BA_ "GenMsgILSupport" BO_ 1400 1;
BA_ "GenMsgNrOfRepetition" BO_ 1400 2;
BA_ "GenMsgCycleTimeFast" BO_ 1400 100;
BA_ "GenMsgCycleTime" BO_ 1400 500;
BA_ "GenMsgILSupport" BO_ 1401 1;
BA_ "GenMsgSendType" BO_ 1401 8;
BA_ "GenMsgNrOfRepetition" BO_ 1401 2;
BA_ "GenMsgCycleTimeFast" BO_ 1401 100;
BA_ "GenMsgILSupport" BO_ 1323 1;
BA_ "GenMsgSendType" BO_ 1323 8;
BA_ "GenMsgCycleTimeFast" BO_ 1323 100;
BA_ "GenMsgNrOfRepetition" BO_ 1323 2;
BA_ "GenMsgILSupport" BO_ 1335 1;
BA_ "GenMsgNrOfRepetition" BO_ 1335 0;
BA_ "GenMsgCycleTime" BO_ 1335 100;
BA_ "GenMsgILSupport" BO_ 1309 1;
BA_ "GenMsgSendType" BO_ 1309 8;
BA_ "GenMsgNrOfRepetition" BO_ 1309 2;
BA_ "GenMsgCycleTimeFast" BO_ 1309 100;
BA_ "GenMsgILSupport" BO_ 1107 1;
BA_ "GenMsgNrOfRepetition" BO_ 1107 0;
BA_ "GenMsgCycleTime" BO_ 1107 500;
BA_ "GenMsgILSupport" BO_ 1344 1;
BA_ "GenMsgNrOfRepetition" BO_ 1344 0;
BA_ "GenMsgCycleTime" BO_ 1344 100;
BA_ "GenMsgILSupport" BO_ 1327 1;
BA_ "GenMsgSendType" BO_ 1327 8;
BA_ "GenMsgNrOfRepetition" BO_ 1327 2;
BA_ "GenMsgCycleTimeFast" BO_ 1327 100;
BA_ "GenMsgILSupport" BO_ 1325 1;
BA_ "GenMsgSendType" BO_ 1325 8;
BA_ "GenMsgCycleTimeFast" BO_ 1325 100;
BA_ "GenMsgNrOfRepetition" BO_ 1325 2;
BA_ "GenMsgILSupport" BO_ 1303 1;
BA_ "GenMsgNrOfRepetition" BO_ 1303 2;
BA_ "GenMsgCycleTimeFast" BO_ 1303 100;
BA_ "GenMsgCycleTime" BO_ 1303 1000;
BA_ "GenMsgILSupport" BO_ 1302 1;
BA_ "GenMsgNrOfRepetition" BO_ 1302 0;
BA_ "GenMsgCycleTime" BO_ 1302 500;
BA_ "GenMsgILSupport" BO_ 1301 1;
BA_ "GenMsgSendType" BO_ 1301 8;
BA_ "GenMsgNrOfRepetition" BO_ 1301 2;
BA_ "GenMsgCycleTimeFast" BO_ 1301 100;
BA_ "SystemSignalLongSymbol" SG_ 1535 CEM_DHM_Driver_unlockmode_feedba "CEM_DHM_Driver_unlockmode_feedback";
BA_ "SystemSignalLongSymbol" SG_ 914 CEM_2_HazardLampForUrgencyBrakeS "CEM_2_HazardLampForUrgencyBrakeSts";
BA_ "SystemSignalLongSymbol" SG_ 914 CEM_2_Laser_High_Beam_Assist_Sta "CEM_2_Laser_High_Beam_Assist_Status";
BA_ "GenSigStartValue" SG_ 914 CEM_2_FollowMeHomeTimeSts 1;
BA_ "GenSigSendType" SG_ 1340 RBCM_QueenSeatCloseSts 4;
BA_ "GenSigSendType" SG_ 1340 RBCM_QueenSeatOpenSts 4;
BA_ "GenSigSendType" SG_ 1340 RBCM_FGHeat_Request_CommandFB 4;
BA_ "GenSigSendType" SG_ 1340 RBCM_2_RRSeatHeatVentSwSts 4;
BA_ "GenSigSendType" SG_ 1340 RBCM_2_LRSeatHeatVentSwSts 4;
BA_ "GenSigSendType" SG_ 1340 RBCM_MFS_ShakeSts 4;
BA_ "GenSigSendType" SG_ 1340 RBCM_MFS_HeatSts 4;
BA_ "GenSigSendType" SG_ 1405 IHU_Set_Auto_HUDBrightness 2;
BA_ "GenSigSendType" SG_ 1405 IHU_Set_BluetoothWechart_Display 2;
BA_ "GenSigSendType" SG_ 1405 IHU_Set_ADASDisplay 2;
BA_ "GenSigSendType" SG_ 1405 IHU_Set_Navigati_OnDisplay 2;
BA_ "GenSigSendType" SG_ 1405 IHU_Set_HUDDisplayMode 2;
BA_ "GenSigSendType" SG_ 1405 IHU_Set_HUDBrightness 2;
BA_ "GenSigSendType" SG_ 1405 IHU_Set_HUDHeight 2;
BA_ "GenSigSendType" SG_ 1405 IHU_Set_HUDDisplayOnOff 2;
BA_ "GenSigSendType" SG_ 1389 IHU_WCM_DVD_NFC_Connect_BM_Addr 2;
BA_ "GenSigSendType" SG_ 801 MFS_Time_Gap 2;
BA_ "GenSigSendType" SG_ 801 MFS_Cancel 2;
BA_ "SystemSignalLongSymbol" SG_ 1058 IHU_21AssociatedNavigationModeSw "IHU_21AssociatedNavigationModeSwitch";
BA_ "GenSigStartValue" SG_ 1058 IHU_21_FatigueDrivingReminder_Se 3;
BA_ "SystemSignalLongSymbol" SG_ 1058 IHU_21_FatigueDrivingReminder_Se "IHU_21_FatigueDrivingReminder_Set";
BA_ "GenSigStartValue" SG_ 1058 IHU_21_OverspeedAlarm_Set 18;
BA_ "GenSigSendType" SG_ 1069 IHU_17_EDL_SwtCmd 2;
BA_ "GenSigSendType" SG_ 1069 IHU_20_RgnSet 2;
BA_ "GenSigSendType" SG_ 1069 IHU_PowermodeSet 2;
BA_ "GenSigSendType" SG_ 1069 IHU_17_Set_HundECAverHisClearSts 2;
BA_ "GenSigSendType" SG_ 1069 IHU_17_SetChrgnFctMem 2;
BA_ "GenSigStartValue" SG_ 1069 IHU_17_SetChrgnFctMem 3;
BA_ "GenSigSendType" SG_ 1069 IHU_TimeToStopChargeMinuteSet 2;
BA_ "GenSigStartValue" SG_ 1069 IHU_TimeToStopChargeMinuteSet 62;
BA_ "GenSigSendType" SG_ 1069 IHU_TimeToStopChargeHourSet 2;
BA_ "GenSigStartValue" SG_ 1069 IHU_TimeToStopChargeHourSet 30;
BA_ "GenSigSendType" SG_ 1069 IHU_TimeToStartChargeMinuteSet 2;
BA_ "GenSigStartValue" SG_ 1069 IHU_TimeToStartChargeMinuteSet 62;
BA_ "GenSigSendType" SG_ 1069 IHU_TimeToStartChargeHourSet 2;
BA_ "GenSigStartValue" SG_ 1069 IHU_TimeToStartChargeHourSet 30;
BA_ "GenSigSendType" SG_ 1069 IHU_ChargeModeSet 2;
BA_ "GenSigSendType" SG_ 1069 IHU_SetSocManage 2;
BA_ "GenSigSendType" SG_ 1069 Set_AVASFuntion 2;
BA_ "GenSigSendType" SG_ 1069 IHU_SetSOC 2;
BA_ "GenSigSendType" SG_ 901 CTP_EDL_SwtCmd 4;
BA_ "GenSigSendType" SG_ 901 Set_HundECAverHisClearSts 4;
BA_ "GenSigSendType" SG_ 901 CTP_PowerModeSet 4;
BA_ "GenSigSendType" SG_ 901 ISS_Switch 4;
BA_ "GenSigSendType" SG_ 1399 ICC_WindowCon 2;
BA_ "GenSigSendType" SG_ 1399 IHU_17_ACFastHeat 2;
BA_ "GenSigSendType" SG_ 1399 IHU_17_FraganceLightReq 2;
BA_ "GenSigSendType" SG_ 1399 IHU_17_AUTODefLevelSet 2;
BA_ "GenSigSendType" SG_ 1399 IHU_FRSeatliedownCmd2 2;
BA_ "GenSigSendType" SG_ 1399 IHU_17_AirPurgeReminderReq 2;
BA_ "GenSigSendType" SG_ 1399 IHU_17_SetFrontDeforestSts 2;
BA_ "GenSigSendType" SG_ 1399 Refuel_Requset 2;
BA_ "GenSigSendType" SG_ 1407 IHU_IPM_Delayventilation_Req 2;
BA_ "GenSigSendType" SG_ 1407 IHU_15_door_lock_req 2;
BA_ "GenSigSendType" SG_ 1407 IHU_15_GalleryModeReg 2;
BA_ "GenSigSendType" SG_ 1407 IHU_15_AutoDefogEnaSw 2;
BA_ "GenSigSendType" SG_ 1407 IHU_15_Parkingairconditioning 2;
BA_ "GenSigSendType" SG_ 1407 SET_IHU_ACMAXReq 2;
BA_ "GenSigSendType" SG_ 1407 IHU15_MessageCounter 2;
BA_ "GenSigSendType" SG_ 1407 IHU_SpeechControl 2;
BA_ "GenSigSendType" SG_ 1407 SET_Mirror_Fold_Switch 2;
BA_ "GenSigSendType" SG_ 1407 SET_Passenger_Mirror_Location 2;
BA_ "GenSigSendType" SG_ 1407 SET_Driver_Mirror_Location 2;
BA_ "GenSigSendType" SG_ 1407 SET_IPM_Automatic_Ventilation 2;
BA_ "GenSigSendType" SG_ 1407 SET_Mirror_Flip_CFG 2;
BA_ "GenSigSendType" SG_ 1407 SET_RightMirrorCtrl 2;
BA_ "GenSigStartValue" SG_ 1407 SET_RightMirrorCtrl 7;
BA_ "GenSigSendType" SG_ 1407 SET_LeftMirrorCtrl 2;
BA_ "GenSigStartValue" SG_ 1407 SET_LeftMirrorCtrl 7;
BA_ "GenSigSendType" SG_ 1407 SET_IPMCustom_Air_Conditioning 2;
BA_ "GenSigSendType" SG_ 1407 SET_FRSeatHeatVentSwReq 2;
BA_ "GenSigSendType" SG_ 1407 SET_FLSeatHeatVentSwReq 2;
BA_ "GenSigSendType" SG_ 1400 IHU_14_Set_FrontFogLights 2;
BA_ "GenSigSendType" SG_ 1400 SET_Passenger_Welcome_Seat 2;
BA_ "GenSigSendType" SG_ 1400 MFS_ModeSts 2;
BA_ "GenSigSendType" SG_ 1400 RSeatBeltBuckleSwitch 2;
BA_ "GenSigSendType" SG_ 1400 Sound_Options_Signal 2;
BA_ "GenSigSendType" SG_ 1400 Welcome_Sound_Device_Switching_S 2;
BA_ "SystemSignalLongSymbol" SG_ 1400 Welcome_Sound_Device_Switching_S "Welcome_Sound_Device_Switching_Signal";
BA_ "GenSigSendType" SG_ 1400 SET_Wiper_Sensitivity 2;
BA_ "GenSigSendType" SG_ 1400 SET_Tunnel_lamp 2;
BA_ "GenSigSendType" SG_ 1400 IHU_14_SET_Rearfoglight 2;
BA_ "GenSigSendType" SG_ 1400 IHU_14_SET_Lightcontrol 2;
BA_ "GenSigSendType" SG_ 1401 IHU13_MessageCounter 2;
BA_ "GenSigSendType" SG_ 1401 SET_Welcome_Seat 2;
BA_ "GenSigSendType" SG_ 1401 SET_MFS_Shake 2;
BA_ "GenSigSendType" SG_ 1401 SET_MFS_Heat 2;
BA_ "GenSigSendType" SG_ 1401 SET_UnderVoltage 2;
BA_ "GenSigSendType" SG_ 1401 SET_RearWiper_Switch 2;
BA_ "GenSigSendType" SG_ 1401 SET_Wiper_Maintenance 2;
BA_ "GenSigSendType" SG_ 1401 SET_Abat_VentCMD 2;
BA_ "GenSigSendType" SG_ 1401 SET_PSRFCMD 2;
BA_ "GenSigSendType" SG_ 1401 SET_Massagemode 2;
BA_ "GenSigSendType" SG_ 1401 SET_Vibrationmode 2;
BA_ "GenSigSendType" SG_ 1401 SET_Passenger_Massage 2;
BA_ "GenSigSendType" SG_ 1401 SET_PLG_Control 2;
BA_ "GenSigSendType" SG_ 1401 SET_Doorkonbmode 2;
BA_ "GenSigSendType" SG_ 1401 SET_Doorkonb_time 2;
BA_ "GenSigSendType" SG_ 1401 SET_Driver_unlockmode 2;
BA_ "GenSigSendType" SG_ 1401 SET_Smart_LowBeam 2;
BA_ "GenSigSendType" SG_ 1401 SET_LowBeam_Adjust 2;
BA_ "GenSigSendType" SG_ 1323 IHU_12_DATA7 1;
BA_ "GenSigSendType" SG_ 1323 IHU_12_DATA6 1;
BA_ "GenSigSendType" SG_ 1323 IHU_12_DATA5 1;
BA_ "GenSigSendType" SG_ 1323 IHU_12_DATA4 1;
BA_ "GenSigSendType" SG_ 1323 IHU_12_DATA3 1;
BA_ "GenSigSendType" SG_ 1323 IHU_12_DATA2 1;
BA_ "GenSigSendType" SG_ 1323 IHU_12_DATA1 1;
BA_ "GenSigSendType" SG_ 1323 IHU_12_F_DL 1;
BA_ "GenSigSendType" SG_ 1323 IHU_12_PCItype 1;
BA_ "GenSigStartValue" SG_ 1335 IHU_9_ISSFctCmd 1;
BA_ "GenSigStartValue" SG_ 1335 IHU10_NavSts 3;
BA_ "GenSigStartValue" SG_ 1335 IHU_9_ECOModeSWSts 1;
BA_ "GenSigStartValue" SG_ 1335 IHU_9_DriveMode 1;
BA_ "GenSigSendType" SG_ 1309 IHU_EPBAUTO_Cmd 2;
BA_ "GenSigSendType" SG_ 1309 IHU_EPB_Cmd 2;
BA_ "GenSigSendType" SG_ 1309 IHU_SpeParkSet 2;
BA_ "GenSigSendType" SG_ 1309 IHU8Curvedeceleration_ON_OFF_Sts 2;
BA_ "GenSigSendType" SG_ 1309 IHU_8_CCOSwtReq 2;
BA_ "GenSigSendType" SG_ 1309 Child_Safety_Lock 2;
BA_ "GenSigSendType" SG_ 1309 SET_PAS_Switch 2;
BA_ "GenSigSendType" SG_ 1309 CGW_DVDSET_IPBAssociateDriveMode 2;
BA_ "GenSigSendType" SG_ 1309 CGW_CST_SensitivityReq 2;
BA_ "GenSigSendType" SG_ 1309 ESCOFF_ON_OFF 2;
BA_ "GenSigSendType" SG_ 1309 HDC_ON_OFF 2;
BA_ "GenSigSendType" SG_ 1309 AVH_ON_OFF 2;
BA_ "GenSigSendType" SG_ 1309 IHU_CGW_BrakepedalfeelModeSetReq 2;
BA_ "GenSigSendType" SG_ 1309 IHU_8_CGW_Set_CSTFunctionSts 2;
BA_ "GenSigSendType" SG_ 1309 IHU_8_LDWLKA_LaneAssit_TypeReq 2;
BA_ "GenSigSendType" SG_ 1309 IHU_8_SLAOnOffReq 2;
BA_ "GenSigStartValue" SG_ 1309 IHU_8_SLAOnOffReq 2;
BA_ "GenSigSendType" SG_ 1309 IHU_8_HMAOnOffReq 2;
BA_ "GenSigStartValue" SG_ 1309 IHU_8_HMAOnOffReq 2;
BA_ "GenSigSendType" SG_ 1309 IHU_8_LDW_LKA_SensitivityReq 2;
BA_ "GenSigStartValue" SG_ 1309 IHU_8_LDW_LKA_SensitivityReq 2;
BA_ "GenSigSendType" SG_ 1309 IHU_8_TimeGapLastSetReq 2;
BA_ "GenSigStartValue" SG_ 1309 IHU_8_TimeGapLastSetReq 2;
BA_ "GenSigSendType" SG_ 1309 IHU_8_DistanceWarning_On_Off 2;
BA_ "GenSigSendType" SG_ 1309 IHU_8_TJA_ICA_ON_OFF 2;
BA_ "GenSigSendType" SG_ 1309 IHU_8_AEB_ON_OFF 2;
BA_ "GenSigSendType" SG_ 1309 IHU_8_FCW_OPTION 2;
BA_ "GenSigSendType" SG_ 1309 IHU_8_FCW_ON_OFF 2;
BA_ "GenSigSendType" SG_ 1309 IHU_8_TimeGapSet1Req 2;
BA_ "GenSigStartValue" SG_ 1107 IHU_7_CurrentTimeMonth 1;
BA_ "GenSigStartValue" SG_ 1107 IHU_7_CurrentTimeDay 1;
BA_ "GenSigStartValue" SG_ 1344 IHU_6_SET_MusicLoudness_6000HZ 15;
BA_ "GenSigStartValue" SG_ 1344 IHU_6_SET_MusicLoudness_2000HZ 15;
BA_ "GenSigStartValue" SG_ 1344 IHU_6_SET_MusicLoudness_1500HZ 15;
BA_ "GenSigStartValue" SG_ 1344 IHU_6_SET_MusicLoudness_1000HZ 15;
BA_ "GenSigStartValue" SG_ 1344 IHU_6_SET_MusicLoudness_500HZ 15;
BA_ "GenSigStartValue" SG_ 1344 IHU_6_SET_MusicLoudness_250HZ 15;
BA_ "GenSigStartValue" SG_ 1344 IHU_6_SET_MusicLoudness_120HZ 15;
BA_ "GenSigStartValue" SG_ 1344 IHU_6_SET_Apiluminance 15;
BA_ "GenSigStartValue" SG_ 1344 IHU_6_SET_DMSMonitoring 3;
BA_ "GenSigStartValue" SG_ 1344 IHU_6_SET_PM2_5Monitoring 3;
BA_ "GenSigStartValue" SG_ 1344 IHU_6_SET_64Colour 127;
BA_ "GenSigStartValue" SG_ 1344 IHU_6_SET_Static_Colour 15;
BA_ "GenSigStartValue" SG_ 1344 IHU_6_SET_StaticEffect 7;
BA_ "GenSigStartValue" SG_ 1344 IHU_6_SET_ControlSwitch 3;
BA_ "GenSigStartValue" SG_ 1344 IHU_6_SET_WelcomeWaterLamp 3;
BA_ "GenSigStartValue" SG_ 1344 IHU_6_SET_AssociatedWithDriverMo 3;
BA_ "SystemSignalLongSymbol" SG_ 1344 IHU_6_SET_AssociatedWithDriverMo "IHU_6_SET_AssociatedWithDriverMode";
BA_ "GenSigStartValue" SG_ 1344 IHU_6_SET_Music 3;
BA_ "GenSigSendType" SG_ 1327 IHU_5_CoolantFill_Req 2;
BA_ "GenSigSendType" SG_ 1327 IHU_5_UVC_LuminanceReq 2;
BA_ "GenSigSendType" SG_ 1327 IHU_5_UVC_ControlReq 2;
BA_ "GenSigSendType" SG_ 1327 IHU_5_PM25DisplayToggle 2;
BA_ "GenSigSendType" SG_ 1327 IHU_5_DVD_DWMCon_Req 2;
BA_ "GenSigSendType" SG_ 1327 IHU_5_SyncSwtich_Req 2;
BA_ "GenSigSendType" SG_ 1327 IHU_5_L_Set_Temperature 2;
BA_ "GenSigSendType" SG_ 1327 IHU_5_R_Set_Temperature 2;
BA_ "GenSigSendType" SG_ 1327 IHU_5_AnionPurify_Req 2;
BA_ "GenSigSendType" SG_ 1327 IHU_5_AutoState 2;
BA_ "GenSigSendType" SG_ 1327 IHU_5_EngineControlEDReq 2;
BA_ "GenSigSendType" SG_ 1327 IHU_5_RRWindowCon_Req 2;
BA_ "GenSigSendType" SG_ 1327 IHU_5_LRWindowCon_Req 2;
BA_ "GenSigSendType" SG_ 1327 IHU_5_FLWindowCon_Req 2;
BA_ "GenSigSendType" SG_ 1327 IHU_5_FRWindowCon_Req 2;
BA_ "GenSigSendType" SG_ 1327 IHU_5_Control_Mode_Req 2;
BA_ "GenSigSendType" SG_ 1327 IHU_5_TempknobRollingCounterReq 2;
BA_ "GenSigSendType" SG_ 1327 IHU_5_RearDefrostSwitch_Req 2;
BA_ "GenSigSendType" SG_ 1327 IHU_5_ACRequestCommand 2;
BA_ "GenSigSendType" SG_ 1327 IHU_5_FrontOFF_Req 2;
BA_ "GenSigSendType" SG_ 1327 IHU_5_CirculationMode_Req 2;
BA_ "GenSigSendType" SG_ 1327 IHU_5_ModeAdjust_Req 2;
BA_ "GenSigStartValue" SG_ 1327 IHU_5_ModeAdjust_Req 7;
BA_ "GenSigSendType" SG_ 1327 IHU_5_BlowSpeedLevel_Req 2;
BA_ "GenSigSendType" SG_ 1325 IHU_4_DATA7 1;
BA_ "GenSigSendType" SG_ 1325 IHU_4_DATA6 1;
BA_ "GenSigSendType" SG_ 1325 IHU_4_DATA5 1;
BA_ "GenSigSendType" SG_ 1325 IHU_4_DATA4 1;
BA_ "GenSigSendType" SG_ 1325 IHU_4_DATA3 1;
BA_ "GenSigSendType" SG_ 1325 IHU_4_DATA2 1;
BA_ "GenSigSendType" SG_ 1325 IHU_4_DATA1 1;
BA_ "GenSigSendType" SG_ 1325 IHU_4_F_DL 1;
BA_ "GenSigSendType" SG_ 1325 IHU_4_PCItype 1;
BA_ "GenSigSendType" SG_ 1303 IHU_3_Set_Default 4;
BA_ "GenSigSendType" SG_ 1303 IHU_3_DVD_SetScreen 4;
BA_ "GenSigSendType" SG_ 1303 IHU_3_DVD_SetWorkModeSts 4;
BA_ "GenSigSendType" SG_ 1303 IHU_3_DVD_OP_TP_Y 4;
BA_ "GenSigSendType" SG_ 1303 IHU_3_DVD_OP_TP_X 4;
BA_ "GenSigSendType" SG_ 1303 IHU_3_DVD_DefDispMode 4;
BA_ "GenSigSendType" SG_ 1303 IHU_3_BT_PHONE_Sts 4;
BA_ "GenSigSendType" SG_ 1303 IHU_3_DVD_Set_RCW 4;
BA_ "GenSigSendType" SG_ 1303 IHU_3_DVD_Set_DOW 4;
BA_ "GenSigSendType" SG_ 1303 IHU_3_DVD_Set_RadarWarining 4;
BA_ "GenSigSendType" SG_ 1303 IHU_3_AVM_SET_LANG 4;
BA_ "GenSigSendType" SG_ 1303 IHU_3_AVM_OP_VIEW_DVR_SW 4;
BA_ "GenSigStartValue" SG_ 1303 IHU_3_AVM_OP_VIEW_DVR_SW 3;
BA_ "GenSigSendType" SG_ 1303 IHU_3_DVD_Set_SteeringWheel 4;
BA_ "GenSigSendType" SG_ 1303 IHU_3_BSDSwitch 4;
BA_ "GenSigSendType" SG_ 1303 IHU_3_LDWSwitch 4;
BA_ "GenSigSendType" SG_ 1303 IHU_3_CalibrationRequest 4;
BA_ "GenSigSendType" SG_ 1303 IHU_APA_OP_SW 4;
BA_ "GenSigStartValue" SG_ 1303 IHU_APA_OP_SW 3;
BA_ "GenSigStartValue" SG_ 1302 IHU_2_AMRadioFrequanceValue 531;
BA_ "GenSigStartValue" SG_ 1302 IHU_2_FMRadioFrequanceValue 17500;
BA_ "GenSigStartValue" SG_ 1302 IHU_2_RadioResearchSts 1;
BA_ "GenSigSendType" SG_ 1301 IHU_1_DVD_SET_Laser_High_Beam_As 2;
BA_ "GenSigSendType" SG_ 1301 IHU_1_DVD_SET_Mirror_Flip 2;
BA_ "GenSigSendType" SG_ 1301 IHU_1_DVD_SET_HazardLampForUrgen 2;
BA_ "GenSigSendType" SG_ 1301 DVD_EPS_AssociWithDriverModeSts 2;
BA_ "GenSigSendType" SG_ 1301 IHU_1_SET_DWD_Req 2;
BA_ "GenSigSendType" SG_ 1301 IHU_1_RegenerateLevelCtrl 2;
BA_ "GenSigSendType" SG_ 1301 IHU_1_DVD_SetFraganceTime 2;
BA_ "GenSigSendType" SG_ 1301 DVD_Set_FraganceConcentration 2;
BA_ "GenSigSendType" SG_ 1301 IHU_1_DVD_Set_FraganceTaste 2;
BA_ "GenSigSendType" SG_ 1301 IHU_1_DVD_Set_FraganceSwitchSt 2;
BA_ "GenSigStartValue" SG_ 1301 IHU_1_DVD_Set_FraganceSwitchSt 3;
BA_ "GenSigSendType" SG_ 1301 IHU_1_DVD_SET_PLG_SAS 2;
BA_ "GenSigStartValue" SG_ 1301 IHU_1_DVD_SET_PLG_SAS 255;
BA_ "GenSigSendType" SG_ 1301 IHU_1_DVD_Set_External_Welcome_L 2;
BA_ "SystemSignalLongSymbol" SG_ 1301 IHU_1_DVD_Set_External_Welcome_L "IHU_1_DVD_Set_External_Welcome_Light";
BA_ "GenSigSendType" SG_ 1301 IHU_1_DVD_Set_Show_Mode 2;
BA_ "GenSigSendType" SG_ 1301 IHU_1_DVD_SET_Polling 2;
BA_ "GenSigSendType" SG_ 1301 IHU_1_DVD_SET_IPM_First_Blowing 2;
BA_ "GenSigSendType" SG_ 1301 IHU_1_DVD_SET_IPM_Blower_Delay 2;
BA_ "GenSigSendType" SG_ 1301 IHU_DVD_SET_BT_Reduce_Wind_Speed 2;
BA_ "GenSigSendType" SG_ 1301 IHU_1_DVD_SET_RemoteLockFeedback 2;
BA_ "GenSigSendType" SG_ 1301 IHU_1_DVD_SET_EPSmode 2;
BA_ "GenSigSendType" SG_ 1301 IHU_1_DVD_Set_Wash_Car 2;
BA_ "GenSigSendType" SG_ 1301 IHU_1_DVD_Set_12_24_Hour 2;
BA_ "GenSigSendType" SG_ 1301 IHU_1_DVD_SET_Blankingnumber 2;
BA_ "GenSigSendType" SG_ 1301 IHU_1_DVD_SET_AutoUnlockSts 2;
BA_ "GenSigSendType" SG_ 1301 IHU_1_DVD_SET_AutoLockSts 2;
BA_ "GenSigSendType" SG_ 1301 IHU_1_DVD_SET_AidTurningIllumina 2;
BA_ "SystemSignalLongSymbol" SG_ 1301 IHU_1_DVD_SET_AidTurningIllumina "IHU_1_DVD_SET_AidTurningIllumination";
BA_ "GenSigSendType" SG_ 1301 IHU_1_DVD_SET_FollowMeHome 2;
BA_ "GenSigSendType" SG_ 1301 IHU_1_DVD_SET_Mirror_Fold 2;
BA_REL_ "GenSigTimeoutTime" BU_SG_REL_ IHU SG_ 1535 CEM_DHM_Doorkonbmode_feedback 4000;
BA_REL_ "GenSigTimeoutTime" BU_SG_REL_ IHU SG_ 1535 CEM_DHM_Driver_unlockmode_feedba 4000;
BA_REL_ "GenSigTimeoutTime" BU_SG_REL_ IHU SG_ 1535 CEM_UVC_LuminanceBf 4000;
BA_REL_ "GenSigTimeoutTime" BU_SG_REL_ IHU SG_ 1535 CEM_UVC_WorkingBf 4000;
BA_REL_ "GenSigTimeoutTime" BU_SG_REL_ IHU SG_ 1535 CEM_3_Welcome_Seat_Sts 4000;
BA_REL_ "GenSigTimeoutTime" BU_SG_REL_ IHU SG_ 1535 CEM_IPM_3_ACMAXReq_Sts 4000;
BA_REL_ "GenSigTimeoutTime" BU_SG_REL_ IHU SG_ 1535 CEM_3_PM25DisplayToggle_Sts 4000;
BA_REL_ "GenSigTimeoutTime" BU_SG_REL_ IHU SG_ 1535 CEM_3_DWM_Sts_Msg 4000;
BA_REL_ "GenSigTimeoutTime" BU_SG_REL_ IHU SG_ 1535 CEM_3_EngineControlSts 4000;
BA_REL_ "GenSigTimeoutTime" BU_SG_REL_ IHU SG_ 914 CEM_2_AlarmMode 400;
BA_REL_ "GenSigTimeoutTime" BU_SG_REL_ IHU SG_ 914 CEM_2_RemoteTrunkOnlySts 400;
BA_REL_ "GenSigTimeoutTime" BU_SG_REL_ IHU SG_ 914 CEM_2_AutoLockSts 400;
BA_REL_ "GenSigTimeoutTime" BU_SG_REL_ IHU SG_ 914 CEM_2RearDefrosts 400;
BA_REL_ "GenSigTimeoutTime" BU_SG_REL_ IHU SG_ 914 CEM_2_HazardLampForUrgencyBrakeS 400;
BA_REL_ "GenSigTimeoutTime" BU_SG_REL_ IHU SG_ 914 CEM_2_Mirror_FlipSts 400;
BA_REL_ "GenSigTimeoutTime" BU_SG_REL_ IHU SG_ 914 CEM_2_RemoteLockFeedbackSts 400;
BA_REL_ "GenSigTimeoutTime" BU_SG_REL_ IHU SG_ 914 CEM_2_AutoUnlockSts 400;
BA_REL_ "GenSigTimeoutTime" BU_SG_REL_ IHU SG_ 914 CEM_2_WiperSts 400;
BA_REL_ "GenSigTimeoutTime" BU_SG_REL_ IHU SG_ 914 CEM_2_RainDetected 400;
BA_REL_ "GenSigTimeoutTime" BU_SG_REL_ IHU SG_ 914 CEM_2_WiperSensitivitySWSts 400;
BA_REL_ "GenSigTimeoutTime" BU_SG_REL_ IHU SG_ 914 CEM_2_RainSensorFailSts 400;
BA_REL_ "GenSigTimeoutTime" BU_SG_REL_ IHU SG_ 914 CEM_2_RARDfstCmd 400;
BA_REL_ "GenSigTimeoutTime" BU_SG_REL_ IHU SG_ 914 CEM_2_WiperSelectionSts 400;
BA_REL_ "GenSigTimeoutTime" BU_SG_REL_ IHU SG_ 914 CEM_2_FrontFogLightSts 400;
BA_REL_ "GenSigTimeoutTime" BU_SG_REL_ IHU SG_ 914 CEM_2_Laser_High_Beam_Assist_Sta 400;
BA_REL_ "GenSigTimeoutTime" BU_SG_REL_ IHU SG_ 914 CEM_2_ReverseGearSwitch 400;
BA_REL_ "GenSigTimeoutTime" BU_SG_REL_ IHU SG_ 914 CEM_2_RearFogLightSts 400;
BA_REL_ "GenSigTimeoutTime" BU_SG_REL_ IHU SG_ 914 CEM_2_External_WelcomelightSts 400;
BA_REL_ "GenSigTimeoutTime" BU_SG_REL_ IHU SG_ 914 CEM_2_Mirror_Fold_Sts 400;
BA_REL_ "GenSigTimeoutTime" BU_SG_REL_ IHU SG_ 914 CEM_2_TrunkSts 400;
BA_REL_ "GenSigTimeoutTime" BU_SG_REL_ IHU SG_ 914 CEM_2_LHRdoorSts 400;
BA_REL_ "GenSigTimeoutTime" BU_SG_REL_ IHU SG_ 914 CEM_2_RHRDoorSts 400;
BA_REL_ "GenSigTimeoutTime" BU_SG_REL_ IHU SG_ 914 CEM_2_SunRoofSts 400;
BA_REL_ "GenSigTimeoutTime" BU_SG_REL_ IHU SG_ 914 CEM_2_HoodSts 400;
BA_REL_ "GenSigTimeoutTime" BU_SG_REL_ IHU SG_ 914 CEM_2_PsngrDoorSts 400;
BA_REL_ "GenSigTimeoutTime" BU_SG_REL_ IHU SG_ 914 CEM_2_DriverDoorSts 400;
BA_REL_ "GenSigTimeoutTime" BU_SG_REL_ IHU SG_ 914 CEM_2_FollowMeTimeSts 400;
BA_REL_ "GenSigTimeoutTime" BU_SG_REL_ IHU SG_ 914 CEM_2_BlankingnumberSts 400;
BA_REL_ "GenSigTimeoutTime" BU_SG_REL_ IHU SG_ 914 CEM_2_DirectionIndLeft 400;
BA_REL_ "GenSigTimeoutTime" BU_SG_REL_ IHU SG_ 914 CEM_2_DirectionIndRight 400;
BA_REL_ "GenSigTimeoutTime" BU_SG_REL_ IHU SG_ 914 CEM_2_DRLSts 400;
BA_REL_ "GenSigTimeoutTime" BU_SG_REL_ IHU SG_ 914 CEM_2_LowBeamSts 400;
BA_REL_ "GenSigTimeoutTime" BU_SG_REL_ IHU SG_ 914 CEM_2_Laser_LightSts 400;
BA_REL_ "GenSigTimeoutTime" BU_SG_REL_ IHU SG_ 914 CEM_2_HighBeamSts 400;
BA_REL_ "GenSigTimeoutTime" BU_SG_REL_ IHU SG_ 914 CEM_2_ParkTailLightSts 400;
BA_REL_ "GenSigTimeoutTime" BU_SG_REL_ IHU SG_ 914 CEM_2_BrakePedalSts 400;
BA_REL_ "GenSigTimeoutTime" BU_SG_REL_ IHU SG_ 914 CEM_2_LHTurnlightSts 400;
BA_REL_ "GenSigTimeoutTime" BU_SG_REL_ IHU SG_ 914 CEM_2_RHTurnlightSts 400;
BA_REL_ "GenSigTimeoutTime" BU_SG_REL_ IHU SG_ 914 CEM_2_BlankchanginglaneSts 400;
BA_REL_ "GenSigTimeoutTime" BU_SG_REL_ IHU SG_ 914 CEM_2_KeySts 400;
BA_REL_ "GenSigTimeoutTime" BU_SG_REL_ IHU SG_ 914 CEM_2_FollowMeHomeSts 400;
BA_REL_ "GenSigTimeoutTime" BU_SG_REL_ IHU SG_ 914 CEM_2_KeyRemindWarning 400;
BA_REL_ "GenSigTimeoutTime" BU_SG_REL_ IHU SG_ 914 CEM_2_ParkLightOnWarning 400;
BA_REL_ "GenSigTimeoutTime" BU_SG_REL_ IHU SG_ 914 CEM_2_FollowMeHomeTimeSts 400;
BA_REL_ "GenSigTimeoutTime" BU_SG_REL_ IHU SG_ 1340 RBCM_FGHeat_Request_CommandFB 2000;
BA_REL_ "GenSigTimeoutTime" BU_SG_REL_ IHU SG_ 1340 RBCM_2_RRSeatHeatVentSwSts 2000;
BA_REL_ "GenSigTimeoutTime" BU_SG_REL_ IHU SG_ 1340 RBCM_2_LRSeatHeatVentSwSts 2000;
BA_REL_ "GenSigTimeoutTime" BU_SG_REL_ IHU SG_ 1340 RBCM_MFS_ShakeSts 2000;
BA_REL_ "GenSigTimeoutTime" BU_SG_REL_ IHU SG_ 1340 RBCM_MFS_HeatSts 2000;
BA_REL_ "GenSigTimeoutTime" BU_SG_REL_ IHU SG_ 1306 CEM_IPM_AC_DisplaySts 2000;
BA_REL_ "GenSigTimeoutTime" BU_SG_REL_ IHU SG_ 1306 CEM_IPM_Custom_Air_Conditioning 2000;
BA_REL_ "GenSigTimeoutTime" BU_SG_REL_ IHU SG_ 1306 CEM_IPM_Automatic_Ventilation 2000;
BA_REL_ "GenSigTimeoutTime" BU_SG_REL_ IHU SG_ 1306 CEM_IPM_First_BlowingSts 2000;
BA_REL_ "GenSigTimeoutTime" BU_SG_REL_ IHU SG_ 1306 CEM_IPM_TempknobRollingCounter 2000;
BA_REL_ "GenSigTimeoutTime" BU_SG_REL_ IHU SG_ 1306 CEM_IPM_AnionPurify 2000;
BA_REL_ "GenSigTimeoutTime" BU_SG_REL_ IHU SG_ 1306 CEM_IPM_PM25_Detect 2000;
BA_REL_ "GenSigTimeoutTime" BU_SG_REL_ IHU SG_ 1306 CEM_IPM_SyncSts 2000;
BA_REL_ "GenSigTimeoutTime" BU_SG_REL_ IHU SG_ 1306 CEM_IPM_FrontAutoACSts 2000;
BA_REL_ "GenSigTimeoutTime" BU_SG_REL_ IHU SG_ 1306 CEM_IPM_RearBlowModeSts 2000;
BA_REL_ "GenSigTimeoutTime" BU_SG_REL_ IHU SG_ 1306 CEM_IPM_RearAutoACSts 2000;
BA_REL_ "GenSigTimeoutTime" BU_SG_REL_ IHU SG_ 1306 CEM_IPM_RearBlowSpdCtrlSts 2000;
BA_REL_ "GenSigTimeoutTime" BU_SG_REL_ IHU SG_ 1306 CEM_IPM_RearTempsts 2000;
BA_REL_ "GenSigTimeoutTime" BU_SG_REL_ IHU SG_ 1306 CEM_IPM_RearOFFsts 2000;
BA_REL_ "GenSigTimeoutTime" BU_SG_REL_ IHU SG_ 1306 CEM_IPM_RearDefrosts 2000;
BA_REL_ "GenSigTimeoutTime" BU_SG_REL_ IHU SG_ 1306 CEM_IPM_FrontOFFSts 2000;
BA_REL_ "GenSigTimeoutTime" BU_SG_REL_ IHU SG_ 1306 CEM_IPM_ACStatus 2000;
BA_REL_ "GenSigTimeoutTime" BU_SG_REL_ IHU SG_ 1306 CEM_IPM_RecyMode 2000;
BA_REL_ "GenSigTimeoutTime" BU_SG_REL_ IHU SG_ 1306 CEM_IPM_FrontBlowModeSts 2000;
BA_REL_ "GenSigTimeoutTime" BU_SG_REL_ IHU SG_ 1306 CEM_IPM_FrontBlowSpdCtrlsts 2000;
BA_REL_ "GenSigTimeoutTime" BU_SG_REL_ IHU SG_ 1306 CEM_IPM_FRTempsts 2000;
BA_REL_ "GenSigTimeoutTime" BU_SG_REL_ IHU SG_ 1306 CEM_IPM_FLTempsts 2000;
BA_REL_ "GenSigTimeoutTime" BU_SG_REL_ IHU SG_ 952 AQS_SnsrAirQlyRespAQSLifeCntr 2000;
BA_REL_ "GenSigTimeoutTime" BU_SG_REL_ IHU SG_ 952 AQS_SnsrAirQlyRespAQSErrSts 2000;
BA_REL_ "GenSigTimeoutTime" BU_SG_REL_ IHU SG_ 952 AQS_SnsrAirQlyRespAQSNO2Sts 2000;
BA_REL_ "GenSigTimeoutTime" BU_SG_REL_ IHU SG_ 952 AQS_SnsrAirQlyRespAQSCOSts 2000;
BA_REL_ "GenSigTimeoutTime" BU_SG_REL_ IHU SG_ 952 AQS__SnsrAirQlyRespAirQlySts 2000;
BA_REL_ "GenSigTimeoutTime" BU_SG_REL_ IHU SG_ 1381 S_RAIN 4000;
BA_REL_ "GenSigTimeoutTime" BU_SG_REL_ IHU SG_ 1381 S_AUTOPANEL 4000;
BA_REL_ "GenSigTimeoutTime" BU_SG_REL_ IHU SG_ 1376 FRAG_VoltageSt 4000;
BA_REL_ "GenSigTimeoutTime" BU_SG_REL_ IHU SG_ 1376 FRAG_BlowerMotorSt 4000;
BA_REL_ "GenSigTimeoutTime" BU_SG_REL_ IHU SG_ 1376 FRAG_FraganceCoxCLoad 4000;
BA_REL_ "GenSigTimeoutTime" BU_SG_REL_ IHU SG_ 1376 FRAG_FraganceBoxBLoad 4000;
BA_REL_ "GenSigTimeoutTime" BU_SG_REL_ IHU SG_ 1376 FRAG_FraganceBoxALoad 4000;
BA_REL_ "GenSigTimeoutTime" BU_SG_REL_ IHU SG_ 1376 FRAG_FraganceTaste3RemanentRatio 4000;
BA_REL_ "GenSigTimeoutTime" BU_SG_REL_ IHU SG_ 1376 FRAG_FraganceTaste2RemanentRatio 4000;
BA_REL_ "GenSigTimeoutTime" BU_SG_REL_ IHU SG_ 1376 FRAG_StepperMotorStepErr 4000;
BA_REL_ "GenSigTimeoutTime" BU_SG_REL_ IHU SG_ 1376 FRAG_Error 4000;
BA_REL_ "GenSigTimeoutTime" BU_SG_REL_ IHU SG_ 1376 FRAG_1_LINResponseError 4000;
BA_REL_ "GenSigTimeoutTime" BU_SG_REL_ IHU SG_ 1376 FRAG_FraganceTaste1RemanentRatio 4000;
BA_REL_ "GenSigTimeoutTime" BU_SG_REL_ IHU SG_ 1376 FRAG_FraganceConcentration 4000;
BA_REL_ "GenSigTimeoutTime" BU_SG_REL_ IHU SG_ 1376 FRAG_FraganceTaste 4000;
BA_REL_ "GenSigTimeoutTime" BU_SG_REL_ IHU SG_ 1376 FRAG_FraganceSwitchResp 4000;
VAL_ 1535 CEM_3_passenger_Welcome_Seat_Sts 2 "No_Active" 1 "Active" 0 "lnvalid_Default" ;
VAL_ 1535 CEM_DHM_Doorkonbmode_feedback 2 "No_Popup(2)" 1 "Popup(1)" 0 "Invalid_Default(0)" ;
VAL_ 1535 CEM_DHM_Driver_unlockmode_feedba 2 "Fourdoor_unlock(2)" 1 "Drivedoor_unlock(1)" 0 "Invalid_Default(0)" ;
VAL_ 1535 CEM_UVC_LuminanceBf 7 "Reserved(7)" 6 "Reserved(6)" 5 "Reserved(5)" 4 "Reserved(4)" 3 "high(3)" 2 "Reserved(2)" 1 "Low(1)" 0 " No request_Initial value(0)" ;
VAL_ 1535 CEM_UVC_WorkingBf 3 "Auto request(3)" 2 "Open request(2)" 1 "Close request(1)" 0 " No request_ Initial value(0)" ;
VAL_ 1535 CEM_3_Welcome_Seat_Sts 2 "No_Active(2)" 1 "Active(1)" 0 "Invalid_Default(0)" ;
VAL_ 1535 CEM_IPM_3_ACMAXReq_Sts 2 " Active(2)" 1 "NOT Active(1)" 0 "Invalid(0)" ;
VAL_ 1535 CEM_3_PM25DisplayToggle_Sts 2 "Out(2)" 1 "In(1)" 0 "No Request(0)" ;
VAL_ 1535 CEM_3_DWM_Sts_Msg 0 "Error(0)" 3 "Rise(3)" 2 "Close(2)" 1 "Open(1)" ;
VAL_ 1535 CEM_3_EngineControlSts 0 "Receive_Fail(0)" 1 "Receive_Succeed(1)" ;
VAL_ 914 CEM_2_AlarmMode 15 "Invalid(15)" 14 "Invalid(14)" 13 "Invalid(13)" 12 "Invalid(12)" 11 "Invalid(11)" 10 "Invalid(10)" 9 "Invalid(9)" 8 "Invalid(8)" 7 "Invalid(7)" 6 "Invalid(6)" 5 "TrunkReleaseMode(5)" 4 "ArmingFaultMode(4)" 3 "DisableIntrusionMode(3)" 2 "IntrusionMode(2)" 1 "ArmingMode(1)" 0 "DisarmingMode(0)" ;
VAL_ 914 CEM_2_RemoteTrunkOnlySts 1 "Remote_Trunk_Only_Mode(1)" 0 "Not_Remote_Trunk_Only_Mode(0)" ;
VAL_ 914 CEM_2_AutoLockSts 1 "AutoLock Active(1)" 0 "AutoLock  NOT Active(0)" ;
VAL_ 914 CEM_2RearDefrosts 1 "Active(1)" 0 "Not_Active(0)" ;
VAL_ 914 CEM_2_HazardLampForUrgencyBrakeS 1 "HazardLampForUrgBrkMode(1)" 0 "HazardLampNotForUrgBrkMode(0)" ;
VAL_ 914 CEM_2_Mirror_FlipSts 1 "Off(1)" 0 "Active(0)" ;
VAL_ 914 CEM_2_RemoteLockFeedbackSts 3 "Not_Feedback(3)" 2 "Only_Speaker(2)" 1 "Only_Lamp(1)" 0 "Lamp_And_Speaker(0)" ;
VAL_ 914 CEM_2_AutoUnlockSts 1 "Auto_Unlock_Mode(1)" 0 "Not_Auto_Unlock_Mode(0)" ;
VAL_ 914 CEM_2_WiperSts 3 "ContinuousFast(3)" 2 "ContinuousSlow(2)" 1 "Auto_Or_Intermittent(1)" 0 "OFF(0)" ;
VAL_ 914 CEM_2_RainDetected 0 "Not_Detected(0)" 1 "Detected(1)" ;
VAL_ 914 CEM_2_WiperSensitivitySWSts 7 "Not_Used(7)" 6 "Not_Used(6)" 5 "High_Sens(5)" 4 "Med_High_Sens(4)" 3 "Med_Sens(3)" 2 "Med_Low_Sens(2)" 1 "Low_Sens(1)" 0 "Not_Active(0)" ;
VAL_ 914 CEM_2_RARDfstCmd 0 "Off(0)" 1 "On(1)" ;
VAL_ 914 CEM_2_FrontFogLightSts 0 "Off(0)" 1 "Active(1)" ;
VAL_ 914 CEM_2_Laser_High_Beam_Assist_Sta 0 "Close(0)" 1 "Open(1)" ;
VAL_ 914 CEM_2_ReverseGearSwitch 0 "Notactive(0)" 1 "Active(1)" ;
VAL_ 914 CEM_2_RearFogLightSts 0 "Off(0)" 1 "Active(1)" ;
VAL_ 914 CEM_2_External_WelcomelightSts 3 "OFF(3)" 2 "Mode3(2)" 1 "Mode2(1)" 0 "Mode1(0)" ;
VAL_ 914 CEM_2_Mirror_Fold_Sts 1 "Off(1)" 0 "Active(0)" ;
VAL_ 914 CEM_2_TrunkSts 0 "Close(0)" 1 "Open(1)" ;
VAL_ 914 CEM_2_LHRdoorSts 0 "Close(0)" 1 "Open(1)" ;
VAL_ 914 CEM_2_RHRDoorSts 0 "Close(0)" 1 "Open(1)" ;
VAL_ 914 CEM_2_SunRoofSts 0 "Close(0)" 1 "Open(1)" ;
VAL_ 914 CEM_2_HoodSts 0 "Close(0)" 1 "Open(1)" ;
VAL_ 914 CEM_2_PsngrDoorSts 0 "Close(0)" 1 "Open(1)" ;
VAL_ 914 CEM_2_DriverDoorSts 0 "Close(0)" 1 "Open(1)" ;
VAL_ 914 CEM_2_FollowMeTimeSts 8 "Eight_Times(8)" 7 "Seven_Times(7)" 6 "Six_Times(6)" 5 "Five_Times(5)" 4 "Four_Times(4)" 3 "Three_Times(3)" 2 "Two_Times(2)" 1 "One_Time(1)" 0 "Not_Active(0)" ;
VAL_ 914 CEM_2_DirectionIndLeft 0 "Not_Active(0)" 1 "Active(1)" ;
VAL_ 914 CEM_2_DirectionIndRight 0 "Not_Active(0)" 1 "Active(1)" ;
VAL_ 914 CEM_2_DRLSts 0 "Off(0)" 1 "Active(1)" ;
VAL_ 914 CEM_2_LowBeamSts 0 "Off(0)" 1 "Active(1)" ;
VAL_ 914 CEM_2_Laser_LightSts 0 "Off(0)" 1 "Active(1)" ;
VAL_ 914 CEM_2_HighBeamSts 0 "Off(0)" 1 "Active(1)" ;
VAL_ 914 CEM_2_ParkTailLightSts 0 "Off(0)" 1 "Active(1)" ;
VAL_ 914 CEM_2_BrakePedalSts 1 "Applied(1)" 0 "Not applied(0)" ;
VAL_ 914 CEM_2_LHTurnlightSts 0 "Off(0)" 1 "Active(1)" ;
VAL_ 914 CEM_2_RHTurnlightSts 0 "Off(0)" 1 "Active(1)" ;
VAL_ 914 CEM_2_BlankchanginglaneSts 1 "Blanking_Not_Active(1)" 0 "Blanking_Active(0)" ;
VAL_ 914 CEM_2_KeySts 3 "Crank_ON(3)" 2 "On(2)" 1 "ACC(1)" 0 "Off(0)" ;
VAL_ 914 CEM_2_FollowMeHomeSts 1 "Close(1)" 0 "Open(0)" ;
VAL_ 914 CEM_2_KeyRemindWarning 0 "Off(0)" 1 "Active(1)" ;
VAL_ 914 CEM_2_ParkLightOnWarning 0 "Off(0)" 1 "Active(1)" ;
VAL_ 914 CEM_2_FollowMeHomeTimeSts 3 "Close(3)" 2 "60s(2)" 1 "30s(1)" ;
VAL_ 1340 RBCM_FGHeat_Request_CommandFB 1 "Active(1)" 0 "Not Active(0)" ;
VAL_ 1340 RBCM_2_RRSeatHeatVentSwSts 7 "Reserved" 6 "Reserved" 5 "Reserved" 4 "Level_3_Heat_Request" 3 "Level_2_Heat_Request" 2 "Level_1_Heat_Request" 1 "OFF" 0 "NoActive" ;
VAL_ 1340 RBCM_2_LRSeatHeatVentSwSts 7 "Reserved" 6 "Reserved" 5 "Reserved" 4 "Level_3_Heat_Request" 3 "Level_2_Heat_Request" 2 "Level_1_Heat_Request" 1 "OFF" 0 "NoActive" ;
VAL_ 1340 RBCM_MFS_ShakeSts 1 "Active(1)" 0 "Not Active(0)" ;
VAL_ 1340 RBCM_MFS_HeatSts 1 "Active(1)" 0 "Not Active(0)" ;
VAL_ 1306 CEM_IPM_Blower_DelaySts 1 "Active(1)" 0 "Off(0)" ;
VAL_ 1306 CEM_IPM_AC_DisplaySts 0 "Not_Active(0)" 1 "Active(1)" ;
VAL_ 1306 CEM_IPM_Custom_Air_Conditioning 2 "powerful(2)" 1 "comfort(1)" 0 "energy_Conservation(0)" ;
VAL_ 1306 CEM_IPM_Automatic_Ventilation 1 "Not_Active(1)" 0 "Active(0)" ;
VAL_ 1306 CEM_IPM_First_BlowingSts 1 "Active(1)" 0 "Off(0)" ;
VAL_ 1306 CEM_IPM_TempknobRollingCounter 15 "15(15)" 14 "14(14)" 13 "13(13)" 12 "12(12)" 11 "11(11)" 10 "10(10)" 0 "Not_Active(0)" ;
VAL_ 1306 CEM_IPM_AnionPurify 1 "Active(1)" 0 "NotActive(0)" ;
VAL_ 1306 CEM_IPM_PM25_Detect 1 "Active(1)" 0 "NotActive(0)" ;
VAL_ 1306 CEM_IPM_SyncSts 1 "Active(1)" 0 "NotActive(0)" ;
VAL_ 1306 CEM_IPM_FrontAutoACSts 1 "Active(1)" 0 "NotActive(0)" ;
VAL_ 1306 CEM_IPM_RearBlowModeSts 3 "No_Pressed(3)" 2 "Foot(2)" 1 "Face_&Foot(1)" 0 "Face(0)" ;
VAL_ 1306 CEM_IPM_RearAutoACSts 1 "Active(1)" 0 "Not_Active(0)" ;
VAL_ 1306 CEM_IPM_RearBlowSpdCtrlSts 15 "Invalid(15)" 5 "Speed_5_Request(5)" 4 "Speed_4_Request(4)" 3 "Speed_3_Request(3)" 2 "Speed_2_Request(2)" 1 "Speed_1_Request(1)" 0 "No_Request(0)" ;
VAL_ 1306 CEM_IPM_RearOFFsts 1 "Active(1)" 0 "Not_Active(0)" ;
VAL_ 1306 CEM_IPM_RearDefrosts 1 "Active(1)" 0 "Not_Active(0)" ;
VAL_ 1306 CEM_IPM_FrontOFFSts 1 "Active(1)" 0 "NotActive(0)" ;
VAL_ 1306 CEM_IPM_ACStatus 1 "Active(1)" 0 "NotActive(0)" ;
VAL_ 1306 CEM_IPM_RecyMode 3 "auto_Recycle_Request(3)" 2 "external_Recycle_Request(2)" 1 "internal_Recycle_Request(1)" 0 "no_Request(0)" ;
VAL_ 1306 CEM_IPM_FrontBlowModeSts 7 "No_Pressed(7)" 6 "Reserved(6)" 5 "Reserved(5)" 4 "Defrost(4)" 3 "Foot_Defrost(3)" 2 "Foot(2)" 1 "Face_Foot(1)" 0 "Face(0)" ;
VAL_ 1306 CEM_IPM_FrontBlowSpdCtrlsts 15 "Invalid(15)" 7 "Speed_7_Request(7)" 6 "Speed_6_Request(6)" 5 "Speed_5_Request(5)" 4 "Speed_4_Request(4)" 3 "Speed_3_Request(3)" 2 "Speed_2_Request(2)" 1 "Speed_1_Request(1)" 0 "No_Request(0)" ;
VAL_ 1381 S_RAIN 1 "TRUE(1)" 0 "FALSE_Startup(0)" ;
VAL_ 1381 S_AUTOPANEL 1 "PanelDimActivate(1)" 0 "PanelDimDeactivate_Startup(0)" ;
VAL_ 1376 FRAG_VoltageSt 3 "not_used(3)" 2 "under_voltage(2)" 1 "over_voltage(1)" 0 "normal(0)" ;
VAL_ 1376 FRAG_BlowerMotorSt 1 "error(1)" 0 "No_error(0)" ;
VAL_ 1376 FRAG_FraganceCoxCLoad 31 "Reserved(31)" 30 "Reserved(30)" 29 "Reserved(29)" 28 "Reserved(28)" 27 "Reserved(27)" 26 "Reserved(26)" 25 "Reserved(25)" 24 "Reserved(24)" 23 "Reserved(23)" 22 "Reserved(22)" 21 "Reserved(21)" 20 "Reserved(20)" 19 "Reserved(19)" 18 "Reserved(18)" 17 "Reserved(17)" 16 "Reserved(16)" 15 "Reserved(15)" 14 "Reserved(14)" 13 "Reserved(13)" 12 "Reserved(12)" 11 "Reserved(11)" 10 "Reserved(10)" 7 " 雨后晨沁(7)" 5 "  春日檀韵(5)" 1 "流星幻影(1)" 0 "no_frag_bottle(0)" ;
VAL_ 1376 FRAG_FraganceBoxBLoad 31 "Reserved(31)" 30 "Reserved(30)" 29 "Reserved(29)" 28 "Reserved(28)" 27 "Reserved(27)" 26 "Reserved(26)" 25 "Reserved(25)" 24 "Reserved(24)" 23 "Reserved(23)" 22 "Reserved(22)" 21 "Reserved(21)" 20 "Reserved(20)" 19 "Reserved(19)" 18 "Reserved(18)" 17 "Reserved(17)" 16 "Reserved(16)" 15 "Reserved(15)" 14 "Reserved(14)" 13 "Reserved(13)" 12 "Reserved(12)" 11 "Reserved(11)" 10 "Reserved(10)" 7 " 雨后晨沁(7)" 5 "  春日檀韵(5)" 1 "流星幻影(1)" 0 "no_frag_bottle(0)" ;
VAL_ 1376 FRAG_FraganceBoxALoad 31 "Reserved(31)" 30 "Reserved(30)" 29 "Reserved(29)" 28 "Reserved(28)" 27 "Reserved(27)" 26 "Reserved(26)" 25 "Reserved(25)" 24 "Reserved(24)" 23 "Reserved(23)" 22 "Reserved(22)" 21 "Reserved(21)" 20 "Reserved(20)" 19 "Reserved(19)" 18 "Reserved(18)" 17 "Reserved(17)" 16 "Reserved(16)" 15 "Reserved(15)" 14 "Reserved(14)" 13 "Reserved(13)" 12 "Reserved(12)" 11 "Reserved(11)" 10 "Reserved(10)" 7 " 雨后晨沁(7)" 5 "  春日檀韵(5)" 1 "流星幻影(1)" 0 "no_frag_bottle(0)" ;
VAL_ 1376 FRAG_FraganceTaste3RemanentRatio 15 "Invalid(15)" 14 "Reserved(14)" 13 "Reserved(13)" 12 "Reserved(12)" 11 "Reserved(11)" 10 "10%_per_bit(10)" 9 "10%_per_bit(9)" 8 "10%_per_bit(8)" 7 "10%_per_bit(7)" 6 "10%_per_bit(6)" 5 "10%_per_bit(5)" 4 "10%_per_bit(4)" 3 "10%_per_bit(3)" 2 "10%_per_bit(2)" 1 "10%_per_bit(1)" 0 "10%_per_bit(0)" ;
VAL_ 1376 FRAG_FraganceTaste2RemanentRatio 15 "Invalid(15)" 14 "Reserved(14)" 13 "Reserved(13)" 12 "Reserved(12)" 11 "Reserved(11)" 10 "10%_per_bit(10)" 9 "10%_per_bit(9)" 8 "10%_per_bit(8)" 7 "10%_per_bit(7)" 6 "10%_per_bit(6)" 5 "10%_per_bit(5)" 4 "10%_per_bit(4)" 3 "10%_per_bit(3)" 2 "10%_per_bit(2)" 1 "10%_per_bit(1)" 0 "10%_per_bit(0)" ;
VAL_ 1376 FRAG_StepperMotorStepErr 1 "Error(1)" 0 "No_error(0)" ;
VAL_ 1376 FRAG_Error 7 "ID_Parity_Error(7)" 6 "Byte_Field_Framing_Error(6)" 5 "Checksum_Error(5)" 4 "Tx_Bit_Error(4)" 3 "Under_Volt(3)" 2 "Over_Volt(2)" 1 "Reset(1)" 0 "No_Detected_Fault(0)" ;
VAL_ 1376 FRAG_1_LINResponseError 1 "Error(1)" 0 "No_error(0)" ;
VAL_ 1376 FRAG_FraganceTaste1RemanentRatio 15 "Invalid(15)" 14 "Reserved(14)" 13 "Reserved(13)" 12 "Reserved(12)" 11 "Reserved(11)" 10 "10%_per_bit(10)" 9 "10%_per_bit(9)" 8 "10%_per_bit(8)" 7 "10%_per_bit(7)" 6 "10%_per_bit(6)" 5 "10%_per_bit(5)" 4 "10%_per_bit(4)" 3 "10%_per_bit(3)" 2 "10%_per_bit(2)" 1 "10%_per_bit(1)" 0 "10%_per_bit(0)" ;
VAL_ 1376 FRAG_FraganceConcentration 3 "High(3)" 2 "Mid(2)" 1 "Low(1)" 0 "No_Request(0)" ;
VAL_ 1376 FRAG_FraganceTaste 3 "Taste_3(3)" 2 "Taste_2(2)" 1 "Taste_1(1)" 0 "No_Action(0)" ;
VAL_ 1376 FRAG_FraganceSwitchResp 3 "Invalid(3)" 2 "Reserved(2)" 1 "AFU_ON(1)" 0 "AFU_OFF(0)" ;
VAL_ 1405 IHU_Set_Auto_HUDBrightness 3 "Reserved(3)" 2 "manual(2)" 1 "Auto(1)" 0 "Invalid(0)" ;
VAL_ 1405 IHU_Set_BluetoothWechart_Display 3 "Reserved(3)" 2 "Display(2)" 1 "No_Display(1)" 0 "Invalid(0)" ;
VAL_ 1405 IHU_Set_ADASDisplay 3 "Reserved(3)" 2 "Display(2)" 1 "No_Display(1)" 0 "Invalid(0)" ;
VAL_ 1405 IHU_Set_Navigati_OnDisplay 3 "Reserved(3)" 2 "Display(2)" 1 "No_Display(1)" 0 "Invalid(0)" ;
VAL_ 1405 IHU_Set_HUDDisplayMode 3 "ignore(3)" 2 "snowy(2)" 1 "sport(1)" 0 "Invalid(0)" ;
VAL_ 1405 IHU_Set_HUDBrightness 15 "Ignore(15)" 14 "Reserved(14)" 13 "Reserved(13)" 12 "Reserved(12)" 11 "Reserved(11)" 10 "Level10(10)" 9 "Level9(9)" 8 "Level8(8)" 7 "Level7(7)" 6 "Level6(6)" 5 "Level5(5)" 4 "Level4(4)" 3 "Level3(3)" 2 "Level2(2)" 1 "Level1(1)" 0 "Invalid(0)" ;
VAL_ 1405 IHU_Set_HUDHeight 15 "Ignore(15)" 14 "Reserved(14)" 13 "Reserved(13)" 12 "Reserved(12)" 11 "Reserved(11)" 10 "Level10(10)" 9 "Level9(9)" 8 "Level8(8)" 7 "Level7(7)" 6 "Level6(6)" 5 "Level5(5)" 4 "Level4(4)" 3 "Level3(3)" 2 "Level2(2)" 1 "Level1(1)" 0 "Invalid(0)" ;
VAL_ 1405 IHU_Set_HUDDisplayOnOff 3 "Reserved(3)" 2 "OFF(2)" 1 "ON(1)" 0 "Invalid(0)" ;
VAL_ 801 MFS_Time_Gap 3 "invalid(3)" 2 "Stuck(2)" 1 "Pressed(1)" 0 "Notaction(0)" ;
VAL_ 801 Reserved_MFS_Shift_Down 3 "invalid(3)" 2 "Stuck(2)" 1 "Pressed(1)" 0 "Notaction(0)" ;
VAL_ 801 Reserved_MFS_Shift_Up 3 "invalid(3)" 2 "Stuck(2)" 1 "Pressed(1)" 0 "Notaction(0)" ;
VAL_ 801 MFS_SETMinus 3 "invalid(3)" 2 "Stuck(2)" 1 "Pressed(1)" 0 "Notaction(0)" ;
VAL_ 801 MFS_RESPlus 3 "invalid(3)" 2 "Stuck(2)" 1 "Pressed(1)" 0 "Notaction(0)" ;
VAL_ 801 MFS_Cancel 3 "invalid(3)" 2 "Stuck(2)" 1 "Pressed(1)" 0 "Notaction(0)" ;
VAL_ 801 MFS_Seepd_Limit 3 "invalid(3)" 2 "Stuck(2)" 1 "Pressed(1)" 0 "Notaction(0)" ;
VAL_ 801 MFS_Cruise_Control 3 "invalid(3)" 2 "Stuck(2)" 1 "Pressed(1)" 0 "Notaction(0)" ;
VAL_ 1035 IHU_OTAHvReq 3 " Reserved(3)" 2 " Reserved(2)" 1 " Power Down(1)" 0 " No Request(0)" ;
VAL_ 1035 IHU_OTASts 3 " Reserved(3)" 2 " Reserved(2)" 1 " OTA Status(1)" 0 " Normal Status(0)" ;
VAL_ 1058 IHU_21_Random_showLamp_SW 3 "Invalid" 2 "Reserved" 1 "ON" 0 "OFF" ;
VAL_ 1058 IHU_21AssociatedNavigationModeSw 1 "on(1)" 0 "off(0)" ;
VAL_ 1058 IHU_21VoiceBroadcast 1 "on(1)" 0 "off(0)" ;
VAL_ 1058 IHU_21VoiceWake 3 "副驾唤醒(3)" 2 "主驾唤醒(2)" 1 "on（不区分主副驾）(1)" 0 "off(0)" ;
VAL_ 1058 IHU_21_FatigueDrivingReminder_Se 7 "4h(7)" 6 "3.5h(6)" 5 "3h(5)" 4 "2.5h(4)" 3 "2h(3)" 2 "1.5h(2)" 1 "1h(1)" 0 "Invalid(0)" ;
VAL_ 1058 IHU_ICMBrightnessManualAdj 10 "10(10)" 0 "Invalid(0)" ;
VAL_ 1058 IHU_SET_ICMBrightnessMode 1 "Manual(1)" 0 "Auto_Default(0)" ;
VAL_ 1058 IHU_LockAnimation 3 "Animation3(3)" 2 "Animation2(2)" 1 "Animation1(1)" 0 "Random Animation(0)" ;
VAL_ 1058 IHU_UnlockAnimation 3 "Animation3(3)" 2 "Animation2(2)" 1 "Animation1(1)" 0 "Random Animation(0)" ;
VAL_ 1058 IHU_FatigueDriving 1 "Driver_fatigue_driving(1)" 0 "Driver_status_normal(0)" ;
VAL_ 1058 IHU_SmartSceneMode 15 "场景模式关闭" 6 "冥想模式" 5 "care mode(5)" 4 "Smart health cockpit mode(4)" 3 "queen mode(3)" 2 "舒享模式（休息模式、主驾）(2)" 1 "track mode(1)" 0 "No Request(0)" ;
VAL_ 1069 IHU_17_SetChrgnFctMem 3 " Reserved(3)" 2 " No Remember(2)" 1 " Remember(1)" 0 " Not active(0)" ;
VAL_ 1069 IHU_TimeToStopChargeMinuteSet 63 "Invalid" 62 "Inactive" 61 "Reserved" 60 "Reserved" 59 "Minute 59" 58 "Minute 58" 57 "Minute 57" 56 "Minute 56" 55 "Minute 55" 54 "Minute 54" 53 "Minute 53" 52 "Minute 52" 51 "Minute 51" 50 "Minute 50" 49 "Minute 49" 48 "Minute 48" 47 "Minute 47" 46 "Minute 46" 45 "Minute 45" 44 "Minute 44" 43 "Minute 43" 42 "Minute 42" 41 "Minute 41" 40 "Minute 40" 39 "Minute 39" 38 "Minute 38" 37 "Minute 37" 36 "Minute 36" 35 "Minute 35" 34 "Minute 34" 33 "Minute 33" 31 "Minute 31" 30 "Minute 30" 29 "Minute 29" 28 "Minute 28" 27 "Minute 27" 26 "Minute 26" 25 "Minute 25" 24 "Minute 24" 23 "Minute 23" 22 "Minute 22" 21 "Minute 21" 20 "Minute 20" 19 "Minute 19" 18 "Minute 18" 17 "Minute 17" 15 "Minute 15" 14 "Minute 14" 13 "Minute 13" 12 "Minute 12" 11 "Minute 11" 10 "Minute 10" 9 "Minute 9" 7 "Minute 7" 6 "Minute 6" 5 "Minute 5" 3 "Minute 3" 32 "Minute 32" 16 "Minute 16" 8 "Minute 8" 4 "Minute 4" 2 "Minute 2" 1 "Minute 1" 0 "Minute 0" ;
VAL_ 1069 IHU_TimeToStopChargeHourSet 31 "Invalid" 30 "Inactive" 29 "Reserved(29)" 28 "Reserved(28)" 27 "Reserved(27)" 26 "Reserved(26)" 25 "Reserved(25)" 24 "Reserved" 23 "23" 22 "22" 21 "21" 20 "20" 19 "19" 18 "18" 17 "17" 16 "16" 15 "15" 14 "14" 13 "13" 12 "12" 11 "11" 10 "10" 9 "9" 8 "8" 7 "7" 6 "6" 5 "5" 4 "4" 3 "3" 2 "2" 1 "1" 0 "0" ;
VAL_ 1069 IHU_TimeToStartChargeMinuteSet 63 "Invalid" 62 "Inactive" 61 " Reserved(61)" 60 "Reserved" 59 "59" 58 "58" 57 "57" 56 "56" 55 "55" 54 "54" 53 "53" 52 "52" 51 "51" 50 "50" 49 "49" 48 "48" 47 "47" 46 "46" 45 "45" 44 "44" 43 "43" 42 "42" 41 "41" 40 "40" 39 "39" 38 "38" 37 "37" 36 "36" 35 "35" 34 "34" 33 "33" 32 "32" 31 "31" 30 "30" 29 "29" 28 "28" 27 "27" 26 "26" 25 "25" 24 "24" 23 "23" 22 "22" 21 "21" 20 "20" 19 "19" 18 "18" 17 "17" 16 "16" 15 "15" 14 "14" 13 "13" 12 "12" 11 "11" 10 "10" 9 "9" 8 "8" 7 "7" 6 "6" 5 "5" 4 "4" 3 "3" 2 "2" 1 "1" 0 "0" ;
VAL_ 1069 IHU_TimeToStartChargeHourSet 31 "Invalid" 30 "Inactive" 29 " Reserved(29)" 28 " Reserved(28)" 27 " Reserved(27)" 26 " Reserved(26)" 25 " Reserved(25)" 24 "Reserved" 23 "23" 22 "22" 21 "21" 20 "20" 19 "19" 18 "18" 17 "17" 16 "16" 15 "15" 14 "14" 13 "13" 12 "12" 11 "11" 10 "10" 9 "9" 8 "8" 7 "7" 6 "6" 5 "5" 4 "4" 3 "3" 2 "2" 1 "1" 0 "0" ;
VAL_ 1069 IHU_ChargeModeSet 3 "Cycel Reservation Charge(3)" 2 " Singel Reservation Charge(2)" 1 "Immediate Charge(1)" 0 "Not Active(0)" ;
VAL_ 1069 IHU_SetSocManage 7 " Reserved(7)" 6 " Reserved(6)" 5 " Reserved(5)" 4 "Charge(4)" 3 " Auto(3)" 2 " SAVE (2)" 1 " Default(1)" 0 " NotActive(0)" ;
VAL_ 1069 Set_AVASFuntion 3 " Not Used(3)" 2 " AVAS OFF(2)" 1 " AVAS ON(1)" 0 " Not active(0)" ;
VAL_ 1069 IHU_SetSOC 7 "Not_Used(7)" 6 "70%(6)" 5 "60%(5)" 4 "50%(4)" 3 "40%(3)" 2 "30%(2)" 1 "20%(1)" 0 " Not active(0)" ;
VAL_ 901 Set_HundECAverHisClearSts 1 " Clear(1)" 0 " Not Clear(0)" ;
VAL_ 901 CTP_PowerModeSet 3 " Not Used(3)" 2 " HEV(2)" 1 " EV (1)" 0 " Not Active(0)" ;
VAL_ 901 ISS_Switch 1 " Active(1)" 0 " Not Active(0)" ;
VAL_ 1399 Refuel_Requset 1 "OPEN(1)" 0 "Startup_Default(0)" ;
VAL_ 1407 SET_IHU_ACMAXReq 2 " Active(2)" 1 "NOT Active(1)" 0 "Invalid(0)" ;
VAL_ 1407 IHU_SpeechControl 2 "manual(2)" 1 "Speech(1)" 0 "No request(0)" ;
VAL_ 1407 SET_Mirror_Fold_Switch 2 "No Fold(2)" 1 "Fold(1)" 0 "No request(0)" ;
VAL_ 1407 SET_Passenger_Mirror_Location 21 "M+10(21)" 20 "M+9(20)" 19 "M+8(19)" 18 "M+7(18)" 17 "M+6(17)" 16 "M+5(16)" 15 "M+4(15)" 14 "M+3(14)" 13 "M+2(13)" 12 "M+1(12)" 10 "location 10(10)" 9 "location 9(9)" 8 "location 8(8)" 7 "location 7(7)" 6 "location 6(6)" 5 "location 5(5)" 4 "location 4(4)" 3 "location 3(3)" 2 "location 2(2)" 1 "location 1(1)" 0 "Startup/Default(0)" ;
VAL_ 1407 SET_Driver_Mirror_Location 21 "M+10(21)" 20 "M+9(20)" 19 "M+8(19)" 18 "M+7(18)" 17 "M+6(17)" 16 "M+5(16)" 15 "M+4(15)" 14 "M+3(14)" 13 "M+2(13)" 12 "M+1(12)" 10 "location 10(10)" 9 "location 9(9)" 8 "location 8(8)" 7 "location 7(7)" 6 "location 6(6)" 5 "location 5(5)" 4 "location 4(4)" 3 "location 3(3)" 2 "location 2(2)" 1 "location 1(1)" 0 "Startup/Default(0)" ;
VAL_ 1407 SET_IPM_Automatic_Ventilation 2 "Not Active(2)" 1 "Active(1)" 0 "NO Request (0)" ;
VAL_ 1407 SET_Mirror_Flip_CFG 4 "Left side and right side(4)" 3 "Right side(3)" 2 "Left side(2)" 1 "off(1)" 0 "No command(0)" ;
VAL_ 1407 SET_RightMirrorCtrl 7 "Invalid Value(7)" 6 "Error Value(6)" 5 "Reserved(5)" 4 "Move Right(4)" 3 "Move Left(3)" 2 "Move Down(2)" 1 "Move Up(1)" 0 "No Command(0)" ;
VAL_ 1407 SET_LeftMirrorCtrl 7 "Invalid Value(7)" 6 "Error Value(6)" 5 "Reserved(5)" 4 "Move Right(4)" 3 "Move Left(3)" 2 "Move Down(2)" 1 "Move Up(1)" 0 "No Command(0)" ;
VAL_ 1407 SET_IPMCustom_Air_Conditioning 3 "powerful(3)" 2 "comfort (2)" 1 "energy conservation (1)" 0 "NO Request (0)" ;
VAL_ 1407 SET_FRSeatHeatVentSwReq 7 "Level 3 Ventilation Request(7)" 6 "Level 2 Ventilation Request (6)" 5 "Level 1 Ventilation Request (5)" 4 "Level 3 Heat Request (4)" 3 "Level 2 Heat Request (3)" 2 "Level 1 Heat Request (2)" 1 "OFF (1)" 0 "NO Request (0)" ;
VAL_ 1407 SET_FLSeatHeatVentSwReq 7 "Level 3 Ventilation Request(7)" 6 "Level 2 Ventilation Request (6)" 5 "Level 1 Ventilation Request (5)" 4 "Level 3 Heat Request (4)" 3 "Level 2 Heat Request (3)" 2 "Level 1 Heat Request (2)" 1 "OFF (1)" 0 "NO Request (0)" ;
VAL_ 1400 SET_Passenger_Welcome_Seat 2 "No_Active" 1 "Active" 0 "Invalid/Default" ;
VAL_ 1400 RSeatBeltBuckleSwitch 3 "Reserved(3)" 2 "No active(2)" 1 "Active(1)" 0 "No Request(0)" ;
VAL_ 1400 Sound_Options_Signal 5 "Music_5(5)" 4 "Music_4(4)" 3 "Music_3(3)" 2 "Music_2(2)" 1 "Music_1(1)" 0 "Invalid_Default(0)" ;
VAL_ 1400 Welcome_Sound_Device_Switching_S 2 "No_Active(2)" 1 "Active(1)" 0 "Invalid_Default(0)" ;
VAL_ 1400 SET_Wiper_Sensitivity 4 "High Sens(4)" 3 "Med High Sens(3)" 2 "Med Sens(2)" 1 "Low Sens(1)" 0 "Invalid/default(0)" ;
VAL_ 1400 SET_Tunnel_lamp 2 "No_Active(2)" 1 "Active(1)" 0 "Invalid_default(0)" ;
VAL_ 1400 IHU_14_SET_Rearfoglight 2 "No_Active(2)" 1 "Active(1)" 0 "Invalid_default(0)" ;
VAL_ 1400 IHU_14_SET_Lightcontrol 4 "OFF(4)" 3 "ParkTailLight_LowBeam(3)" 2 "ParkTailLight(2)" 1 "AUTO(1)" 0 "Invalid_default(0)" ;
VAL_ 1401 SET_Welcome_Seat 2 "No_Active(2)" 1 "Active(1)" 0 "Invalid/Default(0)" ;
VAL_ 1401 SET_MFS_Shake 2 "No_Active(2)" 1 "Active(1)" 0 "Invalid/Default(0)" ;
VAL_ 1401 SET_MFS_Heat 2 "No_Active(2)" 1 "Active(1)" 0 "Invalid/Default(0)" ;
VAL_ 1401 SET_UnderVoltage 2 "No_Active(2)" 1 "Active(1)" 0 "Invalid/Default(0)" ;
VAL_ 1401 SET_RearWiper_Switch 2 "No_Active(2)" 1 "Active(1)" 0 "Invalid/Default(0)" ;
VAL_ 1401 SET_Wiper_Maintenance 2 "No_Active(2)" 1 "Active(1)" 0 "Invalid/Default(0)" ;
VAL_ 1401 SET_Abat_VentCMD 15 "Not used(15)" 14 "Not used(14)" 13 "Not used(13)" 12 "tilt(12)" 11 "100%(11)" 10 "90%(10)" 9 "80%(9)" 8 "70%(8)" 7 "60%(7)" 6 "50%(6)" 5 "40%(5)" 4 "30%(4)" 3 "20%(3)" 2 "10%(2)" 1 "0%(1)" 0 "NoAcitive(0)" ;
VAL_ 1401 SET_PSRFCMD 15 "Not used(15)" 14 "Not used(14)" 13 "Not used(13)" 12 "tilt(12)" 11 "100%(11)" 10 "90%(10)" 9 "80%(9)" 8 "70%(8)" 7 "60%(7)" 6 "50%(6)" 5 "40%(5)" 4 "30%(4)" 3 "20%(3)" 2 "10%(2)" 1 "0%(1)" 0 "NoAcitive(0)" ;
VAL_ 1401 SET_Massagemode 5 "5 Mode(5)" 4 "4 Mode(4)" 3 "3 Mode(3)" 2 "2 Mode(2)" 1 "1 Mode(1)" 0 "Invalid/default(0)" ;
VAL_ 1401 SET_Vibrationmode 3 "High(3)" 2 "Middle(2)" 1 "Low(1)" 0 "Invalid/default (0)" ;
VAL_ 1401 SET_Passenger_Massage 2 "No_Active(2)" 1 "Active(1)" 0 "Invalid/Default(0)" ;
VAL_ 1401 SET_PLG_Control 2 "Stop(2)" 1 "Open/Close(1)" 0 "Invalid/Default(0)" ;
VAL_ 1401 SET_Doorkonbmode 2 "No Popup(2)" 1 "Popup(1)" 0 "Invalid/Default(0)" ;
VAL_ 1401 SET_Doorkonb_time 3 "180S(3)" 2 "90S(2)" 1 "30S(1)" 0 "Invalid/Default(0)" ;
VAL_ 1401 SET_Driver_unlockmode 2 "Fourdoor unlock(2)" 1 "Drivedoor unlock(1)" 0 "Invalid/Default(0)" ;
VAL_ 1401 SET_Smart_LowBeam 2 "No_Active(2)" 1 "Active(1)" 0 "Invalid/Default(0)" ;
VAL_ 1401 SET_LowBeam_Adjust 4 "The third gear(4)" 3 "The second gear(3)" 2 "The first gear(2)" 1 "The Zeroth gear(1)" 0 "Invalid/default (0)" ;
VAL_ 1323 IHU_12_PCItype 2 "Consecutive_Frame(2)" 1 "The_First_Frame(1)" 0 "The_Single_Frame(0)" ;
VAL_ 1335 IHU_9_IHUResolutionX 4094 "Not_Used(4094)" 4093 "Not_Used(4093)" 4092 "Not_Used(4092)" 4091 "Not_Used(4091)" 4090 "Not_Used(4090)" 4089 "Not_Used(4089)" 4088 "Not_Used(4088)" 4087 "Not_Used(4087)" 4086 "Not_Used(4086)" 4085 "Not_Used(4085)" 4084 "Not_Used(4084)" 4083 "Not_Used(4083)" 4082 "Not_Used(4082)" 4081 "Not_Used(4081)" 4080 "Not_Used(4080)" 4079 "Not_Used(4079)" 4078 "Not_Used(4078)" 4077 "Not_Used(4077)" 4076 "Not_Used(4076)" 4075 "Not_Used(4075)" 4074 "Not_Used(4074)" 4073 "Not_Used(4073)" 4072 "Not_Used(4072)" 4071 "Not_Used(4071)" 4070 "Not_Used(4070)" 4069 "Not_Used(4069)" 4068 "Not_Used(4068)" 4067 "Not_Used(4067)" 4066 "Not_Used(4066)" 4065 "Not_Used(4065)" 4064 "Not_Used(4064)" 4063 "Not_Used(4063)" 4062 "Not_Used(4062)" 4061 "Not_Used(4061)" 4060 "Not_Used(4060)" 4059 "Not_Used(4059)" 4058 "Not_Used(4058)" 4057 "Not_Used(4057)" 4056 "Not_Used(4056)" 4055 "Not_Used(4055)" 4054 "Not_Used(4054)" 4053 "Not_Used(4053)" 4052 "Not_Used(4052)" 4051 "Not_Used(4051)" 4050 "Not_Used(4050)" 4049 "Not_Used(4049)" 4048 "Not_Used(4048)" 4047 "Not_Used(4047)" 4046 "Not_Used(4046)" 4045 "Not_Used(4045)" 4044 "Not_Used(4044)" 4043 "Not_Used(4043)" 4042 "Not_Used(4042)" 4041 "Not_Used(4041)" 4040 "Not_Used(4040)" 4039 "Not_Used(4039)" 4038 "Not_Used(4038)" 4037 "Not_Used(4037)" 4036 "Not_Used(4036)" 4035 "Not_Used(4035)" 4034 "Not_Used(4034)" 4033 "Not_Used(4033)" 4032 "Not_Used(4032)" 4031 "Not_Used(4031)" 4030 "Not_Used(4030)" 4029 "Not_Used(4029)" 4028 "Not_Used(4028)" 4027 "Not_Used(4027)" 4026 "Not_Used(4026)" 4025 "Not_Used(4025)" 4024 "Not_Used(4024)" 4023 "Not_Used(4023)" 4022 "Not_Used(4022)" 4021 "Not_Used(4021)" 4020 "Not_Used(4020)" 4019 "Not_Used(4019)" 4018 "Not_Used(4018)" 4017 "Not_Used(4017)" 4016 "Not_Used(4016)" 4015 "Not_Used(4015)" 4014 "Not_Used(4014)" 4013 "Not_Used(4013)" 4012 "Not_Used(4012)" 4011 "Not_Used(4011)" 4010 "Not_Used(4010)" 4009 "Not_Used(4009)" 4008 "Not_Used(4008)" 4007 "Not_Used(4007)" 4006 "Not_Used(4006)" 4005 "Not_Used(4005)" 4004 "Not_Used(4004)" 4003 "Not_Used(4003)" 4002 "Not_Used(4002)" 4001 "Not_Used(4001)" 4000 "Not_Used(4000)" 3999 "Not_Used(3999)" 3998 "Not_Used(3998)" 3997 "Not_Used(3997)" 3996 "Not_Used(3996)" 3995 "Not_Used(3995)" 3994 "Not_Used(3994)" 3993 "Not_Used(3993)" 3992 "Not_Used(3992)" 3991 "Not_Used(3991)" 3990 "Not_Used(3990)" 3989 "Not_Used(3989)" 3988 "Not_Used(3988)" 3987 "Not_Used(3987)" 3986 "Not_Used(3986)" 3985 "Not_Used(3985)" 3984 "Not_Used(3984)" 3983 "Not_Used(3983)" 3982 "Not_Used(3982)" 3981 "Not_Used(3981)" 3980 "Not_Used(3980)" 3979 "Not_Used(3979)" 3978 "Not_Used(3978)" 3977 "Not_Used(3977)" 3976 "Not_Used(3976)" 3975 "Not_Used(3975)" 3974 "Not_Used(3974)" 3973 "Not_Used(3973)" 3972 "Not_Used(3972)" 3971 "Not_Used(3971)" 3970 "Not_Used(3970)" 3969 "Not_Used(3969)" 3968 "Not_Used(3968)" 3967 "Not_Used(3967)" 3966 "Not_Used(3966)" 3965 "Not_Used(3965)" 3964 "Not_Used(3964)" 3963 "Not_Used(3963)" 3962 "Not_Used(3962)" 3961 "Not_Used(3961)" 3960 "Not_Used(3960)" 3959 "Not_Used(3959)" 3958 "Not_Used(3958)" 3957 "Not_Used(3957)" 3956 "Not_Used(3956)" 3955 "Not_Used(3955)" 3954 "Not_Used(3954)" 3953 "Not_Used(3953)" 3952 "Not_Used(3952)" 3951 "Not_Used(3951)" 3950 "Not_Used(3950)" 3949 "Not_Used(3949)" 3948 "Not_Used(3948)" 3947 "Not_Used(3947)" 3946 "Not_Used(3946)" 3945 "Not_Used(3945)" 3944 "Not_Used(3944)" 3943 "Not_Used(3943)" 3942 "Not_Used(3942)" 3941 "Not_Used(3941)" 3940 "Not_Used(3940)" 3939 "Not_Used(3939)" 3938 "Not_Used(3938)" 3937 "Not_Used(3937)" 3936 "Not_Used(3936)" 3935 "Not_Used(3935)" 3934 "Not_Used(3934)" 3933 "Not_Used(3933)" 3932 "Not_Used(3932)" 3931 "Not_Used(3931)" 3930 "Not_Used(3930)" 3929 "Not_Used(3929)" 3928 "Not_Used(3928)" 3927 "Not_Used(3927)" 3926 "Not_Used(3926)" 3925 "Not_Used(3925)" 3924 "Not_Used(3924)" 3923 "Not_Used(3923)" 3922 "Not_Used(3922)" 3921 "Not_Used(3921)" 3920 "Not_Used(3920)" 3919 "Not_Used(3919)" 3918 "Not_Used(3918)" 3917 "Not_Used(3917)" 3916 "Not_Used(3916)" 3915 "Not_Used(3915)" 3914 "Not_Used(3914)" 3913 "Not_Used(3913)" 3912 "Not_Used(3912)" 3911 "Not_Used(3911)" 3910 "Not_Used(3910)" 3909 "Not_Used(3909)" 3908 "Not_Used(3908)" 3907 "Not_Used(3907)" 3906 "Not_Used(3906)" 3905 "Not_Used(3905)" 3904 "Not_Used(3904)" 3903 "Not_Used(3903)" 3902 "Not_Used(3902)" 3901 "Not_Used(3901)" 3900 "Not_Used(3900)" 3899 "Not_Used(3899)" 3898 "Not_Used(3898)" 3897 "Not_Used(3897)" 3896 "Not_Used(3896)" 3895 "Not_Used(3895)" 3894 "Not_Used(3894)" 3893 "Not_Used(3893)" 3892 "Not_Used(3892)" 3891 "Not_Used(3891)" 3890 "Not_Used(3890)" 3889 "Not_Used(3889)" 3888 "Not_Used(3888)" 3887 "Not_Used(3887)" 3886 "Not_Used(3886)" 3885 "Not_Used(3885)" 3884 "Not_Used(3884)" 3883 "Not_Used(3883)" 3882 "Not_Used(3882)" 3881 "Not_Used(3881)" 3880 "Not_Used(3880)" 3879 "Not_Used(3879)" 3878 "Not_Used(3878)" 3877 "Not_Used(3877)" 3876 "Not_Used(3876)" 3875 "Not_Used(3875)" 3874 "Not_Used(3874)" 3873 "Not_Used(3873)" 3872 "Not_Used(3872)" 3871 "Not_Used(3871)" 3870 "Not_Used(3870)" 3869 "Not_Used(3869)" 3868 "Not_Used(3868)" 3867 "Not_Used(3867)" 3866 "Not_Used(3866)" 3865 "Not_Used(3865)" 3864 "Not_Used(3864)" 3863 "Not_Used(3863)" 3862 "Not_Used(3862)" 3861 "Not_Used(3861)" 3860 "Not_Used(3860)" 3859 "Not_Used(3859)" 3858 "Not_Used(3858)" 3857 "Not_Used(3857)" 3856 "Not_Used(3856)" 3855 "Not_Used(3855)" 3854 "Not_Used(3854)" 3853 "Not_Used(3853)" 3852 "Not_Used(3852)" 3851 "Not_Used(3851)" 3850 "Not_Used(3850)" 3849 "Not_Used(3849)" 3848 "Not_Used(3848)" 3847 "Not_Used(3847)" 3846 "Not_Used(3846)" 3845 "Not_Used(3845)" 3844 "Not_Used(3844)" 3843 "Not_Used(3843)" 3842 "Not_Used(3842)" 3841 "Not_Used(3841)" 3840 "Not_Used(3840)" 3839 "Not_Used(3839)" 3838 "Not_Used(3838)" 3837 "Not_Used(3837)" 3836 "Not_Used(3836)" 3835 "Not_Used(3835)" 3834 "Not_Used(3834)" 3833 "Not_Used(3833)" 3832 "Not_Used(3832)" 3831 "Not_Used(3831)" 3830 "Not_Used(3830)" 3829 "Not_Used(3829)" 3828 "Not_Used(3828)" 3827 "Not_Used(3827)" 3826 "Not_Used(3826)" 3825 "Not_Used(3825)" 3824 "Not_Used(3824)" 3823 "Not_Used(3823)" 3822 "Not_Used(3822)" 3821 "Not_Used(3821)" 3820 "Not_Used(3820)" 3819 "Not_Used(3819)" 3818 "Not_Used(3818)" 3817 "Not_Used(3817)" 3816 "Not_Used(3816)" 3815 "Not_Used(3815)" 3814 "Not_Used(3814)" 3813 "Not_Used(3813)" 3812 "Not_Used(3812)" 3811 "Not_Used(3811)" 3810 "Not_Used(3810)" 3809 "Not_Used(3809)" 3808 "Not_Used(3808)" 3807 "Not_Used(3807)" 3806 "Not_Used(3806)" 3805 "Not_Used(3805)" 3804 "Not_Used(3804)" 3803 "Not_Used(3803)" 3802 "Not_Used(3802)" 3801 "Not_Used(3801)" 3800 "Not_Used(3800)" 3799 "Not_Used(3799)" 3798 "Not_Used(3798)" 3797 "Not_Used(3797)" 3796 "Not_Used(3796)" 3795 "Not_Used(3795)" 3794 "Not_Used(3794)" 3793 "Not_Used(3793)" 3792 "Not_Used(3792)" 3791 "Not_Used(3791)" 3790 "Not_Used(3790)" 3789 "Not_Used(3789)" 3788 "Not_Used(3788)" 3787 "Not_Used(3787)" 3786 "Not_Used(3786)" 3785 "Not_Used(3785)" 3784 "Not_Used(3784)" 3783 "Not_Used(3783)" 3782 "Not_Used(3782)" 3781 "Not_Used(3781)" 3780 "Not_Used(3780)" 3779 "Not_Used(3779)" 3778 "Not_Used(3778)" 3777 "Not_Used(3777)" 3776 "Not_Used(3776)" 3775 "Not_Used(3775)" 3774 "Not_Used(3774)" 3773 "Not_Used(3773)" 3772 "Not_Used(3772)" 3771 "Not_Used(3771)" 3770 "Not_Used(3770)" 3769 "Not_Used(3769)" 3768 "Not_Used(3768)" 3767 "Not_Used(3767)" 3766 "Not_Used(3766)" 3765 "Not_Used(3765)" 3764 "Not_Used(3764)" 3763 "Not_Used(3763)" 3762 "Not_Used(3762)" 3761 "Not_Used(3761)" 3760 "Not_Used(3760)" 3759 "Not_Used(3759)" 3758 "Not_Used(3758)" 3757 "Not_Used(3757)" 3756 "Not_Used(3756)" 3755 "Not_Used(3755)" 3754 "Not_Used(3754)" 3753 "Not_Used(3753)" 3752 "Not_Used(3752)" 3751 "Not_Used(3751)" 3750 "Not_Used(3750)" 3749 "Not_Used(3749)" 3748 "Not_Used(3748)" 3747 "Not_Used(3747)" 3746 "Not_Used(3746)" 3745 "Not_Used(3745)" 3744 "Not_Used(3744)" 3743 "Not_Used(3743)" 3742 "Not_Used(3742)" 3741 "Not_Used(3741)" 3740 "Not_Used(3740)" 3739 "Not_Used(3739)" 3738 "Not_Used(3738)" 3737 "Not_Used(3737)" 3736 "Not_Used(3736)" 3735 "Not_Used(3735)" 3734 "Not_Used(3734)" 3733 "Not_Used(3733)" 3732 "Not_Used(3732)" 3731 "Not_Used(3731)" 3730 "Not_Used(3730)" 3729 "Not_Used(3729)" 3728 "Not_Used(3728)" 3727 "Not_Used(3727)" 3726 "Not_Used(3726)" 3725 "Not_Used(3725)" 3724 "Not_Used(3724)" 3723 "Not_Used(3723)" 3722 "Not_Used(3722)" 3721 "Not_Used(3721)" 3720 "Not_Used(3720)" 3719 "Not_Used(3719)" 3718 "Not_Used(3718)" 3717 "Not_Used(3717)" 3716 "Not_Used(3716)" 3715 "Not_Used(3715)" 3714 "Not_Used(3714)" 3713 "Not_Used(3713)" 3712 "Not_Used(3712)" 3711 "Not_Used(3711)" 3710 "Not_Used(3710)" 3709 "Not_Used(3709)" 3708 "Not_Used(3708)" 3707 "Not_Used(3707)" 3706 "Not_Used(3706)" 3705 "Not_Used(3705)" 3704 "Not_Used(3704)" 3703 "Not_Used(3703)" 3702 "Not_Used(3702)" 3701 "Not_Used(3701)" 3700 "Not_Used(3700)" 3699 "Not_Used(3699)" 3698 "Not_Used(3698)" 3697 "Not_Used(3697)" 3696 "Not_Used(3696)" 3695 "Not_Used(3695)" 3694 "Not_Used(3694)" 3693 "Not_Used(3693)" 3692 "Not_Used(3692)" 3691 "Not_Used(3691)" 3690 "Not_Used(3690)" 3689 "Not_Used(3689)" 3688 "Not_Used(3688)" 3687 "Not_Used(3687)" 3686 "Not_Used(3686)" 3685 "Not_Used(3685)" 3684 "Not_Used(3684)" 3683 "Not_Used(3683)" 3682 "Not_Used(3682)" 3681 "Not_Used(3681)" 3680 "Not_Used(3680)" 3679 "Not_Used(3679)" 3678 "Not_Used(3678)" 3677 "Not_Used(3677)" 3676 "Not_Used(3676)" 3675 "Not_Used(3675)" 3674 "Not_Used(3674)" 3673 "Not_Used(3673)" 3672 "Not_Used(3672)" 3671 "Not_Used(3671)" 3670 "Not_Used(3670)" 3669 "Not_Used(3669)" 3668 "Not_Used(3668)" 3667 "Not_Used(3667)" 3666 "Not_Used(3666)" 3665 "Not_Used(3665)" 3664 "Not_Used(3664)" 3663 "Not_Used(3663)" 3662 "Not_Used(3662)" 3661 "Not_Used(3661)" 3660 "Not_Used(3660)" 3659 "Not_Used(3659)" 3658 "Not_Used(3658)" 3657 "Not_Used(3657)" 3656 "Not_Used(3656)" 3655 "Not_Used(3655)" 3654 "Not_Used(3654)" 3653 "Not_Used(3653)" 3652 "Not_Used(3652)" 3651 "Not_Used(3651)" 3650 "Not_Used(3650)" 3649 "Not_Used(3649)" 3648 "Not_Used(3648)" 3647 "Not_Used(3647)" 3646 "Not_Used(3646)" 3645 "Not_Used(3645)" 3644 "Not_Used(3644)" 3643 "Not_Used(3643)" 3642 "Not_Used(3642)" 3641 "Not_Used(3641)" 3640 "Not_Used(3640)" 3639 "Not_Used(3639)" 3638 "Not_Used(3638)" 3637 "Not_Used(3637)" 3636 "Not_Used(3636)" 3635 "Not_Used(3635)" 3634 "Not_Used(3634)" 3633 "Not_Used(3633)" 3632 "Not_Used(3632)" 3631 "Not_Used(3631)" 3630 "Not_Used(3630)" 3629 "Not_Used(3629)" 3628 "Not_Used(3628)" 3627 "Not_Used(3627)" 3626 "Not_Used(3626)" 3625 "Not_Used(3625)" 3624 "Not_Used(3624)" 3623 "Not_Used(3623)" 3622 "Not_Used(3622)" 3621 "Not_Used(3621)" 3620 "Not_Used(3620)" 3619 "Not_Used(3619)" 3618 "Not_Used(3618)" 3617 "Not_Used(3617)" 3616 "Not_Used(3616)" 3615 "Not_Used(3615)" 3614 "Not_Used(3614)" 3613 "Not_Used(3613)" 3612 "Not_Used(3612)" 3611 "Not_Used(3611)" 3610 "Not_Used(3610)" 3609 "Not_Used(3609)" 3608 "Not_Used(3608)" 3607 "Not_Used(3607)" 3606 "Not_Used(3606)" 3605 "Not_Used(3605)" 3604 "Not_Used(3604)" 3603 "Not_Used(3603)" 3602 "Not_Used(3602)" 3601 "Not_Used(3601)" 3600 "Not_Used(3600)" 3599 "Not_Used(3599)" 3598 "Not_Used(3598)" 3597 "Not_Used(3597)" 3596 "Not_Used(3596)" 3595 "Not_Used(3595)" 3594 "Not_Used(3594)" 3593 "Not_Used(3593)" 3592 "Not_Used(3592)" 3591 "Not_Used(3591)" 3590 "Not_Used(3590)" 3589 "Not_Used(3589)" 3588 "Not_Used(3588)" 3587 "Not_Used(3587)" 3586 "Not_Used(3586)" 3585 "Not_Used(3585)" 3584 "Not_Used(3584)" 3583 "Not_Used(3583)" 3582 "Not_Used(3582)" 3581 "Not_Used(3581)" 3580 "Not_Used(3580)" 3579 "Not_Used(3579)" 3578 "Not_Used(3578)" 3577 "Not_Used(3577)" 3576 "Not_Used(3576)" 3575 "Not_Used(3575)" 3574 "Not_Used(3574)" 3573 "Not_Used(3573)" 3572 "Not_Used(3572)" 3571 "Not_Used(3571)" 3570 "Not_Used(3570)" 3569 "Not_Used(3569)" 3568 "Not_Used(3568)" 3567 "Not_Used(3567)" 3566 "Not_Used(3566)" 3565 "Not_Used(3565)" 3564 "Not_Used(3564)" 3563 "Not_Used(3563)" 3562 "Not_Used(3562)" 3561 "Not_Used(3561)" 3560 "Not_Used(3560)" 3559 "Not_Used(3559)" 3558 "Not_Used(3558)" 3557 "Not_Used(3557)" 3556 "Not_Used(3556)" 3555 "Not_Used(3555)" 3554 "Not_Used(3554)" 3553 "Not_Used(3553)" 3552 "Not_Used(3552)" 3551 "Not_Used(3551)" 3550 "Not_Used(3550)" 3549 "Not_Used(3549)" 3548 "Not_Used(3548)" 3547 "Not_Used(3547)" 3546 "Not_Used(3546)" 3545 "Not_Used(3545)" 3544 "Not_Used(3544)" 3543 "Not_Used(3543)" 3542 "Not_Used(3542)" 3541 "Not_Used(3541)" 3540 "Not_Used(3540)" 3539 "Not_Used(3539)" 3538 "Not_Used(3538)" 3537 "Not_Used(3537)" 3536 "Not_Used(3536)" 3535 "Not_Used(3535)" 3534 "Not_Used(3534)" 3533 "Not_Used(3533)" 3532 "Not_Used(3532)" 3531 "Not_Used(3531)" 3530 "Not_Used(3530)" 3529 "Not_Used(3529)" 3528 "Not_Used(3528)" 3527 "Not_Used(3527)" 3526 "Not_Used(3526)" 3525 "Not_Used(3525)" 3524 "Not_Used(3524)" 3523 "Not_Used(3523)" 3522 "Not_Used(3522)" 3521 "Not_Used(3521)" 3520 "Not_Used(3520)" 3519 "Not_Used(3519)" 3518 "Not_Used(3518)" 3517 "Not_Used(3517)" 3516 "Not_Used(3516)" 3515 "Not_Used(3515)" 3514 "Not_Used(3514)" 3513 "Not_Used(3513)" 3512 "Not_Used(3512)" 3511 "Not_Used(3511)" 3510 "Not_Used(3510)" 3509 "Not_Used(3509)" 3508 "Not_Used(3508)" 3507 "Not_Used(3507)" 3506 "Not_Used(3506)" 3505 "Not_Used(3505)" 3504 "Not_Used(3504)" 3503 "Not_Used(3503)" 3502 "Not_Used(3502)" 3501 "Not_Used(3501)" 3500 "Not_Used(3500)" 3499 "Not_Used(3499)" 3498 "Not_Used(3498)" 3497 "Not_Used(3497)" 3496 "Not_Used(3496)" 3495 "Not_Used(3495)" 3494 "Not_Used(3494)" 3493 "Not_Used(3493)" 3492 "Not_Used(3492)" 3491 "Not_Used(3491)" 3490 "Not_Used(3490)" 3489 "Not_Used(3489)" 3488 "Not_Used(3488)" 3487 "Not_Used(3487)" 3486 "Not_Used(3486)" 3485 "Not_Used(3485)" 3484 "Not_Used(3484)" 3483 "Not_Used(3483)" 3482 "Not_Used(3482)" 3481 "Not_Used(3481)" 3480 "Not_Used(3480)" 3479 "Not_Used(3479)" 3478 "Not_Used(3478)" 3477 "Not_Used(3477)" 3476 "Not_Used(3476)" 3475 "Not_Used(3475)" 3474 "Not_Used(3474)" 3473 "Not_Used(3473)" 3472 "Not_Used(3472)" 3471 "Not_Used(3471)" 3470 "Not_Used(3470)" 3469 "Not_Used(3469)" 3468 "Not_Used(3468)" 3467 "Not_Used(3467)" 3466 "Not_Used(3466)" 3465 "Not_Used(3465)" 3464 "Not_Used(3464)" 3463 "Not_Used(3463)" 3462 "Not_Used(3462)" 3461 "Not_Used(3461)" 3460 "Not_Used(3460)" 3459 "Not_Used(3459)" 3458 "Not_Used(3458)" 3457 "Not_Used(3457)" 3456 "Not_Used(3456)" 3455 "Not_Used(3455)" 3454 "Not_Used(3454)" 3453 "Not_Used(3453)" 3452 "Not_Used(3452)" 3451 "Not_Used(3451)" 3450 "Not_Used(3450)" 3449 "Not_Used(3449)" 3448 "Not_Used(3448)" 3447 "Not_Used(3447)" 3446 "Not_Used(3446)" 3445 "Not_Used(3445)" 3444 "Not_Used(3444)" 3443 "Not_Used(3443)" 3442 "Not_Used(3442)" 3441 "Not_Used(3441)" 3440 "Not_Used(3440)" 3439 "Not_Used(3439)" 3438 "Not_Used(3438)" 3437 "Not_Used(3437)" 3436 "Not_Used(3436)" 3435 "Not_Used(3435)" 3434 "Not_Used(3434)" 3433 "Not_Used(3433)" 3432 "Not_Used(3432)" 3431 "Not_Used(3431)" 3430 "Not_Used(3430)" 3429 "Not_Used(3429)" 3428 "Not_Used(3428)" 3427 "Not_Used(3427)" 3426 "Not_Used(3426)" 3425 "Not_Used(3425)" 3424 "Not_Used(3424)" 3423 "Not_Used(3423)" 3422 "Not_Used(3422)" 3421 "Not_Used(3421)" 3420 "Not_Used(3420)" 3419 "Not_Used(3419)" 3418 "Not_Used(3418)" 3417 "Not_Used(3417)" 3416 "Not_Used(3416)" 3415 "Not_Used(3415)" 3414 "Not_Used(3414)" 3413 "Not_Used(3413)" 3412 "Not_Used(3412)" 3411 "Not_Used(3411)" 3410 "Not_Used(3410)" 3409 "Not_Used(3409)" 3408 "Not_Used(3408)" 3407 "Not_Used(3407)" 3406 "Not_Used(3406)" 3405 "Not_Used(3405)" 3404 "Not_Used(3404)" 3403 "Not_Used(3403)" 3402 "Not_Used(3402)" 3401 "Not_Used(3401)" 3400 "Not_Used(3400)" 3399 "Not_Used(3399)" 3398 "Not_Used(3398)" 3397 "Not_Used(3397)" 3396 "Not_Used(3396)" 3395 "Not_Used(3395)" 3394 "Not_Used(3394)" 3393 "Not_Used(3393)" 3392 "Not_Used(3392)" 3391 "Not_Used(3391)" 3390 "Not_Used(3390)" 3389 "Not_Used(3389)" 3388 "Not_Used(3388)" 3387 "Not_Used(3387)" 3386 "Not_Used(3386)" 3385 "Not_Used(3385)" 3384 "Not_Used(3384)" 3383 "Not_Used(3383)" 3382 "Not_Used(3382)" 3381 "Not_Used(3381)" 3380 "Not_Used(3380)" 3379 "Not_Used(3379)" 3378 "Not_Used(3378)" 3377 "Not_Used(3377)" 3376 "Not_Used(3376)" 3375 "Not_Used(3375)" 3374 "Not_Used(3374)" 3373 "Not_Used(3373)" 3372 "Not_Used(3372)" 3371 "Not_Used(3371)" 3370 "Not_Used(3370)" 3369 "Not_Used(3369)" 3368 "Not_Used(3368)" 3367 "Not_Used(3367)" 3366 "Not_Used(3366)" 3365 "Not_Used(3365)" 3364 "Not_Used(3364)" 3363 "Not_Used(3363)" 3362 "Not_Used(3362)" 3361 "Not_Used(3361)" 3360 "Not_Used(3360)" 3359 "Not_Used(3359)" 3358 "Not_Used(3358)" 3357 "Not_Used(3357)" 3356 "Not_Used(3356)" 3355 "Not_Used(3355)" 3354 "Not_Used(3354)" 3353 "Not_Used(3353)" 3352 "Not_Used(3352)" 3351 "Not_Used(3351)" 3350 "Not_Used(3350)" 3349 "Not_Used(3349)" 3348 "Not_Used(3348)" 3347 "Not_Used(3347)" 3346 "Not_Used(3346)" 3345 "Not_Used(3345)" 3344 "Not_Used(3344)" 3343 "Not_Used(3343)" 3342 "Not_Used(3342)" 3341 "Not_Used(3341)" 3340 "Not_Used(3340)" 3339 "Not_Used(3339)" 3338 "Not_Used(3338)" 3337 "Not_Used(3337)" 3336 "Not_Used(3336)" 3335 "Not_Used(3335)" 3334 "Not_Used(3334)" 3333 "Not_Used(3333)" 3332 "Not_Used(3332)" 3331 "Not_Used(3331)" 3330 "Not_Used(3330)" 3329 "Not_Used(3329)" 3328 "Not_Used(3328)" 3327 "Not_Used(3327)" 3326 "Not_Used(3326)" 3325 "Not_Used(3325)" 3324 "Not_Used(3324)" 3323 "Not_Used(3323)" 3322 "Not_Used(3322)" 3321 "Not_Used(3321)" 3320 "Not_Used(3320)" 3319 "Not_Used(3319)" 3318 "Not_Used(3318)" 3317 "Not_Used(3317)" 3316 "Not_Used(3316)" 3315 "Not_Used(3315)" 3314 "Not_Used(3314)" 3313 "Not_Used(3313)" 3312 "Not_Used(3312)" 3311 "Not_Used(3311)" 3310 "Not_Used(3310)" 3309 "Not_Used(3309)" 3308 "Not_Used(3308)" 3307 "Not_Used(3307)" 3306 "Not_Used(3306)" 3305 "Not_Used(3305)" 3304 "Not_Used(3304)" 3303 "Not_Used(3303)" 3302 "Not_Used(3302)" 3301 "Not_Used(3301)" 3300 "Not_Used(3300)" 3299 "Not_Used(3299)" 3298 "Not_Used(3298)" 3297 "Not_Used(3297)" 3296 "Not_Used(3296)" 3295 "Not_Used(3295)" 3294 "Not_Used(3294)" 3293 "Not_Used(3293)" 3292 "Not_Used(3292)" 3291 "Not_Used(3291)" 3290 "Not_Used(3290)" 3289 "Not_Used(3289)" 3288 "Not_Used(3288)" 3287 "Not_Used(3287)" 3286 "Not_Used(3286)" 3285 "Not_Used(3285)" 3284 "Not_Used(3284)" 3283 "Not_Used(3283)" 3282 "Not_Used(3282)" 3281 "Not_Used(3281)" 3280 "Not_Used(3280)" 3279 "Not_Used(3279)" 3278 "Not_Used(3278)" 3277 "Not_Used(3277)" 3276 "Not_Used(3276)" 3275 "Not_Used(3275)" 3274 "Not_Used(3274)" 3273 "Not_Used(3273)" 3272 "Not_Used(3272)" 3271 "Not_Used(3271)" 3270 "Not_Used(3270)" 3269 "Not_Used(3269)" 3268 "Not_Used(3268)" 3267 "Not_Used(3267)" 3266 "Not_Used(3266)" 3265 "Not_Used(3265)" 3264 "Not_Used(3264)" 3263 "Not_Used(3263)" 3262 "Not_Used(3262)" 3261 "Not_Used(3261)" 3260 "Not_Used(3260)" 3259 "Not_Used(3259)" 3258 "Not_Used(3258)" 3257 "Not_Used(3257)" 3256 "Not_Used(3256)" 3255 "Not_Used(3255)" 3254 "Not_Used(3254)" 3253 "Not_Used(3253)" 3252 "Not_Used(3252)" 3251 "Not_Used(3251)" 3250 "Not_Used(3250)" 3249 "Not_Used(3249)" 3248 "Not_Used(3248)" 3247 "Not_Used(3247)" 3246 "Not_Used(3246)" 3245 "Not_Used(3245)" 3244 "Not_Used(3244)" 3243 "Not_Used(3243)" 3242 "Not_Used(3242)" 3241 "Not_Used(3241)" 3240 "Not_Used(3240)" 3239 "Not_Used(3239)" 3238 "Not_Used(3238)" 3237 "Not_Used(3237)" 3236 "Not_Used(3236)" 3235 "Not_Used(3235)" 3234 "Not_Used(3234)" 3233 "Not_Used(3233)" 3232 "Not_Used(3232)" 3231 "Not_Used(3231)" 3230 "Not_Used(3230)" 3229 "Not_Used(3229)" 3228 "Not_Used(3228)" 3227 "Not_Used(3227)" 3226 "Not_Used(3226)" 3225 "Not_Used(3225)" 3224 "Not_Used(3224)" 3223 "Not_Used(3223)" 3222 "Not_Used(3222)" 3221 "Not_Used(3221)" 3220 "Not_Used(3220)" 3219 "Not_Used(3219)" 3218 "Not_Used(3218)" 3217 "Not_Used(3217)" 3216 "Not_Used(3216)" 3215 "Not_Used(3215)" 3214 "Not_Used(3214)" 3213 "Not_Used(3213)" 3212 "Not_Used(3212)" 3211 "Not_Used(3211)" 3210 "Not_Used(3210)" 3209 "Not_Used(3209)" 3208 "Not_Used(3208)" 3207 "Not_Used(3207)" 3206 "Not_Used(3206)" 3205 "Not_Used(3205)" 3204 "Not_Used(3204)" 3203 "Not_Used(3203)" 3202 "Not_Used(3202)" 3201 "Not_Used(3201)" 3200 "Not_Used(3200)" 3199 "Not_Used(3199)" 3198 "Not_Used(3198)" 3197 "Not_Used(3197)" 3196 "Not_Used(3196)" 3195 "Not_Used(3195)" 3194 "Not_Used(3194)" 3193 "Not_Used(3193)" 3192 "Not_Used(3192)" 3191 "Not_Used(3191)" 3190 "Not_Used(3190)" 3189 "Not_Used(3189)" 3188 "Not_Used(3188)" 3187 "Not_Used(3187)" 3186 "Not_Used(3186)" 3185 "Not_Used(3185)" 3184 "Not_Used(3184)" 3183 "Not_Used(3183)" 3182 "Not_Used(3182)" 3181 "Not_Used(3181)" 3180 "Not_Used(3180)" 3179 "Not_Used(3179)" 3178 "Not_Used(3178)" 3177 "Not_Used(3177)" 3176 "Not_Used(3176)" 3175 "Not_Used(3175)" 3174 "Not_Used(3174)" 3173 "Not_Used(3173)" 3172 "Not_Used(3172)" 3171 "Not_Used(3171)" 3170 "Not_Used(3170)" 3169 "Not_Used(3169)" 3168 "Not_Used(3168)" 3167 "Not_Used(3167)" 3166 "Not_Used(3166)" 3165 "Not_Used(3165)" 3164 "Not_Used(3164)" 3163 "Not_Used(3163)" 3162 "Not_Used(3162)" 3161 "Not_Used(3161)" 3160 "Not_Used(3160)" 3159 "Not_Used(3159)" 3158 "Not_Used(3158)" 3157 "Not_Used(3157)" 3156 "Not_Used(3156)" 3155 "Not_Used(3155)" 3154 "Not_Used(3154)" 3153 "Not_Used(3153)" 3152 "Not_Used(3152)" 3151 "Not_Used(3151)" 3150 "Not_Used(3150)" 3149 "Not_Used(3149)" 3148 "Not_Used(3148)" 3147 "Not_Used(3147)" 3146 "Not_Used(3146)" 3145 "Not_Used(3145)" 3144 "Not_Used(3144)" 3143 "Not_Used(3143)" 3142 "Not_Used(3142)" 3141 "Not_Used(3141)" 3140 "Not_Used(3140)" 3139 "Not_Used(3139)" 3138 "Not_Used(3138)" 3137 "Not_Used(3137)" 3136 "Not_Used(3136)" 3135 "Not_Used(3135)" 3134 "Not_Used(3134)" 3133 "Not_Used(3133)" 3132 "Not_Used(3132)" 3131 "Not_Used(3131)" 3130 "Not_Used(3130)" 3129 "Not_Used(3129)" 3128 "Not_Used(3128)" 3127 "Not_Used(3127)" 3126 "Not_Used(3126)" 3125 "Not_Used(3125)" 3124 "Not_Used(3124)" 3123 "Not_Used(3123)" 3122 "Not_Used(3122)" 3121 "Not_Used(3121)" 3120 "Not_Used(3120)" 3119 "Not_Used(3119)" 3118 "Not_Used(3118)" 3117 "Not_Used(3117)" 3116 "Not_Used(3116)" 3115 "Not_Used(3115)" 3114 "Not_Used(3114)" 3113 "Not_Used(3113)" 3112 "Not_Used(3112)" 3111 "Not_Used(3111)" 3110 "Not_Used(3110)" 3109 "Not_Used(3109)" 3108 "Not_Used(3108)" 3107 "Not_Used(3107)" 3106 "Not_Used(3106)" 3105 "Not_Used(3105)" 3104 "Not_Used(3104)" 3103 "Not_Used(3103)" 3102 "Not_Used(3102)" 3101 "Not_Used(3101)" 3100 "Not_Used(3100)" 3099 "Not_Used(3099)" 3098 "Not_Used(3098)" 3097 "Not_Used(3097)" 3096 "Not_Used(3096)" 3095 "Not_Used(3095)" 3094 "Not_Used(3094)" 3093 "Not_Used(3093)" 3092 "Not_Used(3092)" 3091 "Not_Used(3091)" 3090 "Not_Used(3090)" 3089 "Not_Used(3089)" 3088 "Not_Used(3088)" 3087 "Not_Used(3087)" 3086 "Not_Used(3086)" 3085 "Not_Used(3085)" 3084 "Not_Used(3084)" 3083 "Not_Used(3083)" 3082 "Not_Used(3082)" 3081 "Not_Used(3081)" 3080 "Not_Used(3080)" 3079 "Not_Used(3079)" 3078 "Not_Used(3078)" 3077 "Not_Used(3077)" 3076 "Not_Used(3076)" 3075 "Not_Used(3075)" 3074 "Not_Used(3074)" 3073 "Not_Used(3073)" 3072 "Not_Used(3072)" 3071 "Not_Used(3071)" 3070 "Not_Used(3070)" 3069 "Not_Used(3069)" 3068 "Not_Used(3068)" 3067 "Not_Used(3067)" 3066 "Not_Used(3066)" 3065 "Not_Used(3065)" 3064 "Not_Used(3064)" 3063 "Not_Used(3063)" 3062 "Not_Used(3062)" 3061 "Not_Used(3061)" 3060 "Not_Used(3060)" 3059 "Not_Used(3059)" 3058 "Not_Used(3058)" 3057 "Not_Used(3057)" 3056 "Not_Used(3056)" 3055 "Not_Used(3055)" 3054 "Not_Used(3054)" 3053 "Not_Used(3053)" 3052 "Not_Used(3052)" 3051 "Not_Used(3051)" 3050 "Not_Used(3050)" 3049 "Not_Used(3049)" 3048 "Not_Used(3048)" 3047 "Not_Used(3047)" 3046 "Not_Used(3046)" 3045 "Not_Used(3045)" 3044 "Not_Used(3044)" 3043 "Not_Used(3043)" 3042 "Not_Used(3042)" 3041 "Not_Used(3041)" 3040 "Not_Used(3040)" 3039 "Not_Used(3039)" 3038 "Not_Used(3038)" 3037 "Not_Used(3037)" 3036 "Not_Used(3036)" 3035 "Not_Used(3035)" 3034 "Not_Used(3034)" 3033 "Not_Used(3033)" 3032 "Not_Used(3032)" 3031 "Not_Used(3031)" 3030 "Not_Used(3030)" 3029 "Not_Used(3029)" 3028 "Not_Used(3028)" 3027 "Not_Used(3027)" 3026 "Not_Used(3026)" 3025 "Not_Used(3025)" 3024 "Not_Used(3024)" 3023 "Not_Used(3023)" 3022 "Not_Used(3022)" 3021 "Not_Used(3021)" 3020 "Not_Used(3020)" 3019 "Not_Used(3019)" 3018 "Not_Used(3018)" 3017 "Not_Used(3017)" 3016 "Not_Used(3016)" 3015 "Not_Used(3015)" 3014 "Not_Used(3014)" 3013 "Not_Used(3013)" 3012 "Not_Used(3012)" 3011 "Not_Used(3011)" 3010 "Not_Used(3010)" 3009 "Not_Used(3009)" 3008 "Not_Used(3008)" 3007 "Not_Used(3007)" 3006 "Not_Used(3006)" 3005 "Not_Used(3005)" 3004 "Not_Used(3004)" 3003 "Not_Used(3003)" 3002 "Not_Used(3002)" 3001 "Not_Used(3001)" 3000 "Not_Used(3000)" 2999 "Not_Used(2999)" 2998 "Not_Used(2998)" 2997 "Not_Used(2997)" 2996 "Not_Used(2996)" 2995 "Not_Used(2995)" 2994 "Not_Used(2994)" 2993 "Not_Used(2993)" 2992 "Not_Used(2992)" 2991 "Not_Used(2991)" 2990 "Not_Used(2990)" 2989 "Not_Used(2989)" 2988 "Not_Used(2988)" 2987 "Not_Used(2987)" 2986 "Not_Used(2986)" 2985 "Not_Used(2985)" 2984 "Not_Used(2984)" 2983 "Not_Used(2983)" 2982 "Not_Used(2982)" 2981 "Not_Used(2981)" 2980 "Not_Used(2980)" 2979 "Not_Used(2979)" 2978 "Not_Used(2978)" 2977 "Not_Used(2977)" 2976 "Not_Used(2976)" 2975 "Not_Used(2975)" 2974 "Not_Used(2974)" 2973 "Not_Used(2973)" 2972 "Not_Used(2972)" 2971 "Not_Used(2971)" 2970 "Not_Used(2970)" 2969 "Not_Used(2969)" 2968 "Not_Used(2968)" 2967 "Not_Used(2967)" 2966 "Not_Used(2966)" 2965 "Not_Used(2965)" 2964 "Not_Used(2964)" 2963 "Not_Used(2963)" 2962 "Not_Used(2962)" 2961 "Not_Used(2961)" 2960 "Not_Used(2960)" 2959 "Not_Used(2959)" 2958 "Not_Used(2958)" 2957 "Not_Used(2957)" 2956 "Not_Used(2956)" 2955 "Not_Used(2955)" 2954 "Not_Used(2954)" 2953 "Not_Used(2953)" 2952 "Not_Used(2952)" 2951 "Not_Used(2951)" 2950 "Not_Used(2950)" 2949 "Not_Used(2949)" 2948 "Not_Used(2948)" 2947 "Not_Used(2947)" 2946 "Not_Used(2946)" 2945 "Not_Used(2945)" 2944 "Not_Used(2944)" 2943 "Not_Used(2943)" 2942 "Not_Used(2942)" 2941 "Not_Used(2941)" 2940 "Not_Used(2940)" 2939 "Not_Used(2939)" 2938 "Not_Used(2938)" 2937 "Not_Used(2937)" 2936 "Not_Used(2936)" 2935 "Not_Used(2935)" 2934 "Not_Used(2934)" 2933 "Not_Used(2933)" 2932 "Not_Used(2932)" 2931 "Not_Used(2931)" 2930 "Not_Used(2930)" 2929 "Not_Used(2929)" 2928 "Not_Used(2928)" 2927 "Not_Used(2927)" 2926 "Not_Used(2926)" 2925 "Not_Used(2925)" 2924 "Not_Used(2924)" 2923 "Not_Used(2923)" 2922 "Not_Used(2922)" 2921 "Not_Used(2921)" 2920 "Not_Used(2920)" 2919 "Not_Used(2919)" 2918 "Not_Used(2918)" 2917 "Not_Used(2917)" 2916 "Not_Used(2916)" 2915 "Not_Used(2915)" 2914 "Not_Used(2914)" 2913 "Not_Used(2913)" 2912 "Not_Used(2912)" 2911 "Not_Used(2911)" 2910 "Not_Used(2910)" 2909 "Not_Used(2909)" 2908 "Not_Used(2908)" 2907 "Not_Used(2907)" 2906 "Not_Used(2906)" 2905 "Not_Used(2905)" 2904 "Not_Used(2904)" 2903 "Not_Used(2903)" 2902 "Not_Used(2902)" 2901 "Not_Used(2901)" 2900 "Not_Used(2900)" 2899 "Not_Used(2899)" 2898 "Not_Used(2898)" 2897 "Not_Used(2897)" 2896 "Not_Used(2896)" 2895 "Not_Used(2895)" 2894 "Not_Used(2894)" 2893 "Not_Used(2893)" 2892 "Not_Used(2892)" 2891 "Not_Used(2891)" 2890 "Not_Used(2890)" 2889 "Not_Used(2889)" 2888 "Not_Used(2888)" 2887 "Not_Used(2887)" 2886 "Not_Used(2886)" 2885 "Not_Used(2885)" 2884 "Not_Used(2884)" 2883 "Not_Used(2883)" 2882 "Not_Used(2882)" 2881 "Not_Used(2881)" 2880 "Not_Used(2880)" 2879 "Not_Used(2879)" 2878 "Not_Used(2878)" 2877 "Not_Used(2877)" 2876 "Not_Used(2876)" 2875 "Not_Used(2875)" 2874 "Not_Used(2874)" 2873 "Not_Used(2873)" 2872 "Not_Used(2872)" 2871 "Not_Used(2871)" 2870 "Not_Used(2870)" 2869 "Not_Used(2869)" 2868 "Not_Used(2868)" 2867 "Not_Used(2867)" 2866 "Not_Used(2866)" 2865 "Not_Used(2865)" 2864 "Not_Used(2864)" 2863 "Not_Used(2863)" 2862 "Not_Used(2862)" 2861 "Not_Used(2861)" 2860 "Not_Used(2860)" 2859 "Not_Used(2859)" 2858 "Not_Used(2858)" 2857 "Not_Used(2857)" 2856 "Not_Used(2856)" 2855 "Not_Used(2855)" 2854 "Not_Used(2854)" 2853 "Not_Used(2853)" 2852 "Not_Used(2852)" 2851 "Not_Used(2851)" 2850 "Not_Used(2850)" 2849 "Not_Used(2849)" 2848 "Not_Used(2848)" 2847 "Not_Used(2847)" 2846 "Not_Used(2846)" 2845 "Not_Used(2845)" 2844 "Not_Used(2844)" 2843 "Not_Used(2843)" 2842 "Not_Used(2842)" 2841 "Not_Used(2841)" 2840 "Not_Used(2840)" 2839 "Not_Used(2839)" 2838 "Not_Used(2838)" 2837 "Not_Used(2837)" 2836 "Not_Used(2836)" 2835 "Not_Used(2835)" 2834 "Not_Used(2834)" 2833 "Not_Used(2833)" 2832 "Not_Used(2832)" 2831 "Not_Used(2831)" 2830 "Not_Used(2830)" 2829 "Not_Used(2829)" 2828 "Not_Used(2828)" 2827 "Not_Used(2827)" 2826 "Not_Used(2826)" 2825 "Not_Used(2825)" 2824 "Not_Used(2824)" 2823 "Not_Used(2823)" 2822 "Not_Used(2822)" 2821 "Not_Used(2821)" 2820 "Not_Used(2820)" 2819 "Not_Used(2819)" 2818 "Not_Used(2818)" 2817 "Not_Used(2817)" 2816 "Not_Used(2816)" 2815 "Not_Used(2815)" 2814 "Not_Used(2814)" 2813 "Not_Used(2813)" 2812 "Not_Used(2812)" 2811 "Not_Used(2811)" 2810 "Not_Used(2810)" 2809 "Not_Used(2809)" 2808 "Not_Used(2808)" 2807 "Not_Used(2807)" 2806 "Not_Used(2806)" 2805 "Not_Used(2805)" 2804 "Not_Used(2804)" 2803 "Not_Used(2803)" 2802 "Not_Used(2802)" 2801 "Not_Used(2801)" 2800 "Not_Used(2800)" 2799 "Not_Used(2799)" 2798 "Not_Used(2798)" 2797 "Not_Used(2797)" 2796 "Not_Used(2796)" 2795 "Not_Used(2795)" 2794 "Not_Used(2794)" 2793 "Not_Used(2793)" 2792 "Not_Used(2792)" 2791 "Not_Used(2791)" 2790 "Not_Used(2790)" 2789 "Not_Used(2789)" 2788 "Not_Used(2788)" 2787 "Not_Used(2787)" 2786 "Not_Used(2786)" 2785 "Not_Used(2785)" 2784 "Not_Used(2784)" 2783 "Not_Used(2783)" 2782 "Not_Used(2782)" 2781 "Not_Used(2781)" 2780 "Not_Used(2780)" 2779 "Not_Used(2779)" 2778 "Not_Used(2778)" 2777 "Not_Used(2777)" 2776 "Not_Used(2776)" 2775 "Not_Used(2775)" 2774 "Not_Used(2774)" 2773 "Not_Used(2773)" 2772 "Not_Used(2772)" 2771 "Not_Used(2771)" 2770 "Not_Used(2770)" 2769 "Not_Used(2769)" 2768 "Not_Used(2768)" 2767 "Not_Used(2767)" 2766 "Not_Used(2766)" 2765 "Not_Used(2765)" 2764 "Not_Used(2764)" 2763 "Not_Used(2763)" 2762 "Not_Used(2762)" 2761 "Not_Used(2761)" 2760 "Not_Used(2760)" 2759 "Not_Used(2759)" 2758 "Not_Used(2758)" 2757 "Not_Used(2757)" 2756 "Not_Used(2756)" 2755 "Not_Used(2755)" 2754 "Not_Used(2754)" 2753 "Not_Used(2753)" 2752 "Not_Used(2752)" 2751 "Not_Used(2751)" 2750 "Not_Used(2750)" 2749 "Not_Used(2749)" 2748 "Not_Used(2748)" 2747 "Not_Used(2747)" 2746 "Not_Used(2746)" 2745 "Not_Used(2745)" 2744 "Not_Used(2744)" 2743 "Not_Used(2743)" 2742 "Not_Used(2742)" 2741 "Not_Used(2741)" 2740 "Not_Used(2740)" 2739 "Not_Used(2739)" 2738 "Not_Used(2738)" 2737 "Not_Used(2737)" 2736 "Not_Used(2736)" 2735 "Not_Used(2735)" 2734 "Not_Used(2734)" 2733 "Not_Used(2733)" 2732 "Not_Used(2732)" 2731 "Not_Used(2731)" 2730 "Not_Used(2730)" 2729 "Not_Used(2729)" 2728 "Not_Used(2728)" 2727 "Not_Used(2727)" 2726 "Not_Used(2726)" 2725 "Not_Used(2725)" 2724 "Not_Used(2724)" 2723 "Not_Used(2723)" 2722 "Not_Used(2722)" 2721 "Not_Used(2721)" 2720 "Not_Used(2720)" 2719 "Not_Used(2719)" 2718 "Not_Used(2718)" 2717 "Not_Used(2717)" 2716 "Not_Used(2716)" 2715 "Not_Used(2715)" 2714 "Not_Used(2714)" 2713 "Not_Used(2713)" 2712 "Not_Used(2712)" 2711 "Not_Used(2711)" 2710 "Not_Used(2710)" 2709 "Not_Used(2709)" 2708 "Not_Used(2708)" 2707 "Not_Used(2707)" 2706 "Not_Used(2706)" 2705 "Not_Used(2705)" 2704 "Not_Used(2704)" 2703 "Not_Used(2703)" 2702 "Not_Used(2702)" 2701 "Not_Used(2701)" 2700 "Not_Used(2700)" 2699 "Not_Used(2699)" 2698 "Not_Used(2698)" 2697 "Not_Used(2697)" 2696 "Not_Used(2696)" 2695 "Not_Used(2695)" 2694 "Not_Used(2694)" 2693 "Not_Used(2693)" 2692 "Not_Used(2692)" 2691 "Not_Used(2691)" 2690 "Not_Used(2690)" 2689 "Not_Used(2689)" 2688 "Not_Used(2688)" 2687 "Not_Used(2687)" 2686 "Not_Used(2686)" 2685 "Not_Used(2685)" 2684 "Not_Used(2684)" 2683 "Not_Used(2683)" 2682 "Not_Used(2682)" 2681 "Not_Used(2681)" 2680 "Not_Used(2680)" 2679 "Not_Used(2679)" 2678 "Not_Used(2678)" 2677 "Not_Used(2677)" 2676 "Not_Used(2676)" 2675 "Not_Used(2675)" 2674 "Not_Used(2674)" 2673 "Not_Used(2673)" 2672 "Not_Used(2672)" 2671 "Not_Used(2671)" 2670 "Not_Used(2670)" 2669 "Not_Used(2669)" 2668 "Not_Used(2668)" 2667 "Not_Used(2667)" 2666 "Not_Used(2666)" 2665 "Not_Used(2665)" 2664 "Not_Used(2664)" 2663 "Not_Used(2663)" 2662 "Not_Used(2662)" 2661 "Not_Used(2661)" 2660 "Not_Used(2660)" 2659 "Not_Used(2659)" 2658 "Not_Used(2658)" 2657 "Not_Used(2657)" 2656 "Not_Used(2656)" 2655 "Not_Used(2655)" 2654 "Not_Used(2654)" 2653 "Not_Used(2653)" 2652 "Not_Used(2652)" 2651 "Not_Used(2651)" 2650 "Not_Used(2650)" 2649 "Not_Used(2649)" 2648 "Not_Used(2648)" 2647 "Not_Used(2647)" 2646 "Not_Used(2646)" 2645 "Not_Used(2645)" 2644 "Not_Used(2644)" 2643 "Not_Used(2643)" 2642 "Not_Used(2642)" 2641 "Not_Used(2641)" 2640 "Not_Used(2640)" 2639 "Not_Used(2639)" 2638 "Not_Used(2638)" 2637 "Not_Used(2637)" 2636 "Not_Used(2636)" 2635 "Not_Used(2635)" 2634 "Not_Used(2634)" 2633 "Not_Used(2633)" 2632 "Not_Used(2632)" 2631 "Not_Used(2631)" 2630 "Not_Used(2630)" 2629 "Not_Used(2629)" 2628 "Not_Used(2628)" 2627 "Not_Used(2627)" 2626 "Not_Used(2626)" 2625 "Not_Used(2625)" 2624 "Not_Used(2624)" 2623 "Not_Used(2623)" 2622 "Not_Used(2622)" 2621 "Not_Used(2621)" 2620 "Not_Used(2620)" 2619 "Not_Used(2619)" 2618 "Not_Used(2618)" 2617 "Not_Used(2617)" 2616 "Not_Used(2616)" 2615 "Not_Used(2615)" 2614 "Not_Used(2614)" 2613 "Not_Used(2613)" 2612 "Not_Used(2612)" 2611 "Not_Used(2611)" 2610 "Not_Used(2610)" 2609 "Not_Used(2609)" 2608 "Not_Used(2608)" 2607 "Not_Used(2607)" 2606 "Not_Used(2606)" 2605 "Not_Used(2605)" 2604 "Not_Used(2604)" 2603 "Not_Used(2603)" 2602 "Not_Used(2602)" 2601 "Not_Used(2601)" 2600 "Not_Used(2600)" 2599 "Not_Used(2599)" 2598 "Not_Used(2598)" 2597 "Not_Used(2597)" 2596 "Not_Used(2596)" 2595 "Not_Used(2595)" 2594 "Not_Used(2594)" 2593 "Not_Used(2593)" 2592 "Not_Used(2592)" 2591 "Not_Used(2591)" 2590 "Not_Used(2590)" 2589 "Not_Used(2589)" 2588 "Not_Used(2588)" 2587 "Not_Used(2587)" 2586 "Not_Used(2586)" 2585 "Not_Used(2585)" 2584 "Not_Used(2584)" 2583 "Not_Used(2583)" 2582 "Not_Used(2582)" 2581 "Not_Used(2581)" 2580 "Not_Used(2580)" 2579 "Not_Used(2579)" 2578 "Not_Used(2578)" 2577 "Not_Used(2577)" 2576 "Not_Used(2576)" 2575 "Not_Used(2575)" 2574 "Not_Used(2574)" 2573 "Not_Used(2573)" 2572 "Not_Used(2572)" 2571 "Not_Used(2571)" 2570 "Not_Used(2570)" 2569 "Not_Used(2569)" 2568 "Not_Used(2568)" 2567 "Not_Used(2567)" 2566 "Not_Used(2566)" 2565 "Not_Used(2565)" 2564 "Not_Used(2564)" 2563 "Not_Used(2563)" 2562 "Not_Used(2562)" 2561 "Not_Used(2561)" 2560 "Not_Used(2560)" ;
VAL_ 1335 IHU10_NavSts 3 "Invalid(3)" 2 "Reserved(2)" 1 "Open(1)" 0 "Close(0)" ;
VAL_ 1335 IHU_9_IHUResolutionY 2046 "Not_Used(2046)" 2045 "Not_Used(2045)" 2044 "Not_Used(2044)" 2043 "Not_Used(2043)" 2042 "Not_Used(2042)" 2041 "Not_Used(2041)" 2040 "Not_Used(2040)" 2039 "Not_Used(2039)" 2038 "Not_Used(2038)" 2037 "Not_Used(2037)" 2036 "Not_Used(2036)" 2035 "Not_Used(2035)" 2034 "Not_Used(2034)" 2033 "Not_Used(2033)" 2032 "Not_Used(2032)" 2031 "Not_Used(2031)" 2030 "Not_Used(2030)" 2029 "Not_Used(2029)" 2028 "Not_Used(2028)" 2027 "Not_Used(2027)" 2026 "Not_Used(2026)" 2025 "Not_Used(2025)" 2024 "Not_Used(2024)" 2023 "Not_Used(2023)" 2022 "Not_Used(2022)" 2021 "Not_Used(2021)" 2020 "Not_Used(2020)" 2019 "Not_Used(2019)" 2018 "Not_Used(2018)" 2017 "Not_Used(2017)" 2016 "Not_Used(2016)" 2015 "Not_Used(2015)" 2014 "Not_Used(2014)" 2013 "Not_Used(2013)" 2012 "Not_Used(2012)" 2011 "Not_Used(2011)" 2010 "Not_Used(2010)" 2009 "Not_Used(2009)" 2008 "Not_Used(2008)" 2007 "Not_Used(2007)" 2006 "Not_Used(2006)" 2005 "Not_Used(2005)" 2004 "Not_Used(2004)" 2003 "Not_Used(2003)" 2002 "Not_Used(2002)" 2001 "Not_Used(2001)" 2000 "Not_Used(2000)" 1999 "Not_Used(1999)" 1998 "Not_Used(1998)" 1997 "Not_Used(1997)" 1996 "Not_Used(1996)" 1995 "Not_Used(1995)" 1994 "Not_Used(1994)" 1993 "Not_Used(1993)" 1992 "Not_Used(1992)" 1991 "Not_Used(1991)" 1990 "Not_Used(1990)" 1989 "Not_Used(1989)" 1988 "Not_Used(1988)" 1987 "Not_Used(1987)" 1986 "Not_Used(1986)" 1985 "Not_Used(1985)" 1984 "Not_Used(1984)" 1983 "Not_Used(1983)" 1982 "Not_Used(1982)" 1981 "Not_Used(1981)" 1980 "Not_Used(1980)" 1979 "Not_Used(1979)" 1978 "Not_Used(1978)" 1977 "Not_Used(1977)" 1976 "Not_Used(1976)" 1975 "Not_Used(1975)" 1974 "Not_Used(1974)" 1973 "Not_Used(1973)" 1972 "Not_Used(1972)" 1971 "Not_Used(1971)" 1970 "Not_Used(1970)" 1969 "Not_Used(1969)" 1968 "Not_Used(1968)" 1967 "Not_Used(1967)" 1966 "Not_Used(1966)" 1965 "Not_Used(1965)" 1964 "Not_Used(1964)" 1963 "Not_Used(1963)" 1962 "Not_Used(1962)" 1961 "Not_Used(1961)" 1960 "Not_Used(1960)" 1959 "Not_Used(1959)" 1958 "Not_Used(1958)" 1957 "Not_Used(1957)" 1956 "Not_Used(1956)" 1955 "Not_Used(1955)" 1954 "Not_Used(1954)" 1953 "Not_Used(1953)" 1952 "Not_Used(1952)" 1951 "Not_Used(1951)" 1950 "Not_Used(1950)" 1949 "Not_Used(1949)" 1948 "Not_Used(1948)" 1947 "Not_Used(1947)" 1946 "Not_Used(1946)" 1945 "Not_Used(1945)" 1944 "Not_Used(1944)" 1943 "Not_Used(1943)" 1942 "Not_Used(1942)" 1941 "Not_Used(1941)" 1940 "Not_Used(1940)" 1939 "Not_Used(1939)" 1938 "Not_Used(1938)" 1937 "Not_Used(1937)" 1936 "Not_Used(1936)" 1935 "Not_Used(1935)" 1934 "Not_Used(1934)" 1933 "Not_Used(1933)" 1932 "Not_Used(1932)" 1931 "Not_Used(1931)" 1930 "Not_Used(1930)" 1929 "Not_Used(1929)" 1928 "Not_Used(1928)" 1927 "Not_Used(1927)" 1926 "Not_Used(1926)" 1925 "Not_Used(1925)" 1924 "Not_Used(1924)" 1923 "Not_Used(1923)" 1922 "Not_Used(1922)" 1921 "Not_Used(1921)" 1920 "Not_Used(1920)" 1919 "Not_Used(1919)" 1918 "Not_Used(1918)" 1917 "Not_Used(1917)" 1916 "Not_Used(1916)" 1915 "Not_Used(1915)" 1914 "Not_Used(1914)" 1913 "Not_Used(1913)" 1912 "Not_Used(1912)" 1911 "Not_Used(1911)" 1910 "Not_Used(1910)" 1909 "Not_Used(1909)" 1908 "Not_Used(1908)" 1907 "Not_Used(1907)" 1906 "Not_Used(1906)" 1905 "Not_Used(1905)" 1904 "Not_Used(1904)" 1903 "Not_Used(1903)" 1902 "Not_Used(1902)" 1901 "Not_Used(1901)" 1900 "Not_Used(1900)" 1899 "Not_Used(1899)" 1898 "Not_Used(1898)" 1897 "Not_Used(1897)" 1896 "Not_Used(1896)" 1895 "Not_Used(1895)" 1894 "Not_Used(1894)" 1893 "Not_Used(1893)" 1892 "Not_Used(1892)" 1891 "Not_Used(1891)" 1890 "Not_Used(1890)" 1889 "Not_Used(1889)" 1888 "Not_Used(1888)" 1887 "Not_Used(1887)" 1886 "Not_Used(1886)" 1885 "Not_Used(1885)" 1884 "Not_Used(1884)" 1883 "Not_Used(1883)" 1882 "Not_Used(1882)" 1881 "Not_Used(1881)" 1880 "Not_Used(1880)" 1879 "Not_Used(1879)" 1878 "Not_Used(1878)" 1877 "Not_Used(1877)" 1876 "Not_Used(1876)" 1875 "Not_Used(1875)" 1874 "Not_Used(1874)" 1873 "Not_Used(1873)" 1872 "Not_Used(1872)" 1871 "Not_Used(1871)" 1870 "Not_Used(1870)" 1869 "Not_Used(1869)" 1868 "Not_Used(1868)" 1867 "Not_Used(1867)" 1866 "Not_Used(1866)" 1865 "Not_Used(1865)" 1864 "Not_Used(1864)" 1863 "Not_Used(1863)" 1862 "Not_Used(1862)" 1861 "Not_Used(1861)" 1860 "Not_Used(1860)" 1859 "Not_Used(1859)" 1858 "Not_Used(1858)" 1857 "Not_Used(1857)" 1856 "Not_Used(1856)" 1855 "Not_Used(1855)" 1854 "Not_Used(1854)" 1853 "Not_Used(1853)" 1852 "Not_Used(1852)" 1851 "Not_Used(1851)" 1850 "Not_Used(1850)" 1849 "Not_Used(1849)" 1848 "Not_Used(1848)" 1847 "Not_Used(1847)" 1846 "Not_Used(1846)" 1845 "Not_Used(1845)" 1844 "Not_Used(1844)" 1843 "Not_Used(1843)" 1842 "Not_Used(1842)" 1841 "Not_Used(1841)" 1840 "Not_Used(1840)" 1839 "Not_Used(1839)" 1838 "Not_Used(1838)" 1837 "Not_Used(1837)" 1836 "Not_Used(1836)" 1835 "Not_Used(1835)" 1834 "Not_Used(1834)" 1833 "Not_Used(1833)" 1832 "Not_Used(1832)" 1831 "Not_Used(1831)" 1830 "Not_Used(1830)" 1829 "Not_Used(1829)" 1828 "Not_Used(1828)" 1827 "Not_Used(1827)" 1826 "Not_Used(1826)" 1825 "Not_Used(1825)" 1824 "Not_Used(1824)" 1823 "Not_Used(1823)" 1822 "Not_Used(1822)" 1821 "Not_Used(1821)" 1820 "Not_Used(1820)" 1819 "Not_Used(1819)" 1818 "Not_Used(1818)" 1817 "Not_Used(1817)" 1816 "Not_Used(1816)" 1815 "Not_Used(1815)" 1814 "Not_Used(1814)" 1813 "Not_Used(1813)" 1812 "Not_Used(1812)" 1811 "Not_Used(1811)" 1810 "Not_Used(1810)" 1809 "Not_Used(1809)" 1808 "Not_Used(1808)" 1807 "Not_Used(1807)" 1806 "Not_Used(1806)" 1805 "Not_Used(1805)" 1804 "Not_Used(1804)" 1803 "Not_Used(1803)" 1802 "Not_Used(1802)" 1801 "Not_Used(1801)" 1800 "Not_Used(1800)" 1799 "Not_Used(1799)" 1798 "Not_Used(1798)" 1797 "Not_Used(1797)" 1796 "Not_Used(1796)" 1795 "Not_Used(1795)" 1794 "Not_Used(1794)" 1793 "Not_Used(1793)" 1792 "Not_Used(1792)" 1791 "Not_Used(1791)" 1790 "Not_Used(1790)" 1789 "Not_Used(1789)" 1788 "Not_Used(1788)" 1787 "Not_Used(1787)" 1786 "Not_Used(1786)" 1785 "Not_Used(1785)" 1784 "Not_Used(1784)" 1783 "Not_Used(1783)" 1782 "Not_Used(1782)" 1781 "Not_Used(1781)" 1780 "Not_Used(1780)" 1779 "Not_Used(1779)" 1778 "Not_Used(1778)" 1777 "Not_Used(1777)" 1776 "Not_Used(1776)" 1775 "Not_Used(1775)" 1774 "Not_Used(1774)" 1773 "Not_Used(1773)" 1772 "Not_Used(1772)" 1771 "Not_Used(1771)" 1770 "Not_Used(1770)" 1769 "Not_Used(1769)" 1768 "Not_Used(1768)" 1767 "Not_Used(1767)" 1766 "Not_Used(1766)" 1765 "Not_Used(1765)" 1764 "Not_Used(1764)" 1763 "Not_Used(1763)" 1762 "Not_Used(1762)" 1761 "Not_Used(1761)" 1760 "Not_Used(1760)" 1759 "Not_Used(1759)" 1758 "Not_Used(1758)" 1757 "Not_Used(1757)" 1756 "Not_Used(1756)" 1755 "Not_Used(1755)" 1754 "Not_Used(1754)" 1753 "Not_Used(1753)" 1752 "Not_Used(1752)" 1751 "Not_Used(1751)" 1750 "Not_Used(1750)" 1749 "Not_Used(1749)" 1748 "Not_Used(1748)" 1747 "Not_Used(1747)" 1746 "Not_Used(1746)" 1745 "Not_Used(1745)" 1744 "Not_Used(1744)" 1743 "Not_Used(1743)" 1742 "Not_Used(1742)" 1741 "Not_Used(1741)" 1740 "Not_Used(1740)" 1739 "Not_Used(1739)" 1738 "Not_Used(1738)" 1737 "Not_Used(1737)" 1736 "Not_Used(1736)" 1735 "Not_Used(1735)" 1734 "Not_Used(1734)" 1733 "Not_Used(1733)" 1732 "Not_Used(1732)" 1731 "Not_Used(1731)" 1730 "Not_Used(1730)" 1729 "Not_Used(1729)" 1728 "Not_Used(1728)" 1727 "Not_Used(1727)" 1726 "Not_Used(1726)" 1725 "Not_Used(1725)" 1724 "Not_Used(1724)" 1723 "Not_Used(1723)" 1722 "Not_Used(1722)" 1721 "Not_Used(1721)" 1720 "Not_Used(1720)" 1719 "Not_Used(1719)" 1718 "Not_Used(1718)" 1717 "Not_Used(1717)" 1716 "Not_Used(1716)" 1715 "Not_Used(1715)" 1714 "Not_Used(1714)" 1713 "Not_Used(1713)" 1712 "Not_Used(1712)" 1711 "Not_Used(1711)" 1710 "Not_Used(1710)" 1709 "Not_Used(1709)" 1708 "Not_Used(1708)" 1707 "Not_Used(1707)" 1706 "Not_Used(1706)" 1705 "Not_Used(1705)" 1704 "Not_Used(1704)" 1703 "Not_Used(1703)" 1702 "Not_Used(1702)" 1701 "Not_Used(1701)" 1700 "Not_Used(1700)" 1699 "Not_Used(1699)" 1698 "Not_Used(1698)" 1697 "Not_Used(1697)" 1696 "Not_Used(1696)" 1695 "Not_Used(1695)" 1694 "Not_Used(1694)" 1693 "Not_Used(1693)" 1692 "Not_Used(1692)" 1691 "Not_Used(1691)" 1690 "Not_Used(1690)" 1689 "Not_Used(1689)" 1688 "Not_Used(1688)" 1687 "Not_Used(1687)" 1686 "Not_Used(1686)" 1685 "Not_Used(1685)" 1684 "Not_Used(1684)" 1683 "Not_Used(1683)" 1682 "Not_Used(1682)" 1681 "Not_Used(1681)" 1680 "Not_Used(1680)" 1679 "Not_Used(1679)" 1678 "Not_Used(1678)" 1677 "Not_Used(1677)" 1676 "Not_Used(1676)" 1675 "Not_Used(1675)" 1674 "Not_Used(1674)" 1673 "Not_Used(1673)" 1672 "Not_Used(1672)" 1671 "Not_Used(1671)" 1670 "Not_Used(1670)" 1669 "Not_Used(1669)" 1668 "Not_Used(1668)" 1667 "Not_Used(1667)" 1666 "Not_Used(1666)" 1665 "Not_Used(1665)" 1664 "Not_Used(1664)" 1663 "Not_Used(1663)" 1662 "Not_Used(1662)" 1661 "Not_Used(1661)" 1660 "Not_Used(1660)" 1659 "Not_Used(1659)" 1658 "Not_Used(1658)" 1657 "Not_Used(1657)" 1656 "Not_Used(1656)" 1655 "Not_Used(1655)" 1654 "Not_Used(1654)" 1653 "Not_Used(1653)" 1652 "Not_Used(1652)" 1651 "Not_Used(1651)" 1650 "Not_Used(1650)" 1649 "Not_Used(1649)" 1648 "Not_Used(1648)" 1647 "Not_Used(1647)" 1646 "Not_Used(1646)" 1645 "Not_Used(1645)" 1644 "Not_Used(1644)" 1643 "Not_Used(1643)" 1642 "Not_Used(1642)" 1641 "Not_Used(1641)" 1640 "Not_Used(1640)" 1639 "Not_Used(1639)" 1638 "Not_Used(1638)" 1637 "Not_Used(1637)" 1636 "Not_Used(1636)" 1635 "Not_Used(1635)" 1634 "Not_Used(1634)" 1633 "Not_Used(1633)" 1632 "Not_Used(1632)" 1631 "Not_Used(1631)" 1630 "Not_Used(1630)" 1629 "Not_Used(1629)" 1628 "Not_Used(1628)" 1627 "Not_Used(1627)" 1626 "Not_Used(1626)" 1625 "Not_Used(1625)" 1624 "Not_Used(1624)" 1623 "Not_Used(1623)" 1622 "Not_Used(1622)" 1621 "Not_Used(1621)" 1620 "Not_Used(1620)" 1619 "Not_Used(1619)" 1618 "Not_Used(1618)" 1617 "Not_Used(1617)" 1616 "Not_Used(1616)" 1615 "Not_Used(1615)" 1614 "Not_Used(1614)" 1613 "Not_Used(1613)" 1612 "Not_Used(1612)" 1611 "Not_Used(1611)" 1610 "Not_Used(1610)" 1609 "Not_Used(1609)" 1608 "Not_Used(1608)" 1607 "Not_Used(1607)" 1606 "Not_Used(1606)" 1605 "Not_Used(1605)" 1604 "Not_Used(1604)" 1603 "Not_Used(1603)" 1602 "Not_Used(1602)" 1601 "Not_Used(1601)" 1600 "Not_Used(1600)" ;
VAL_ 1335 IHU_9_NavCurrRoadType 10 "Nonaviway(10)" 9 "Commonway(9)" 8 "Minorway(8)" 7 "Mainway(7)" 6 "Expressway(6)" 5 "CountyandTownlway(5)" 4 "Townway(4)" 3 "Countylway(3)" 2 "Provincialway(2)" 1 "Nationalway(1)" 0 "Highway(0)" ;
VAL_ 1335 IHU_9_ECOModeSWSts 1 "Active_Startup(1)" 0 "Not_Actve(0)" ;
VAL_ 1335 IHU_9_DriveMode_6DCT_wet 2 "Normal_Mode(2)" 1 "ECO_Mode(1)" 0 "Sport_Mode(0)" ;
VAL_ 1335 IHU_9_DriveMode 7 "Reserved(7)" 6 "Reserved(6)" 5 "SAND(5)" 4 "MUD(4)" 3 "SNOW(3)" 2 "SPORT(2)" 1 "NORMAL(1)" 0 "ECO(0)" ;
VAL_ 1335 IHU_9_NavSpeedLimitUnits 3 "Reserved(3)" 2 "KMH(2)" 1 "MPH(1)" 0 "Unknown(0)" ;
VAL_ 1335 IHU_9_NavSpeedLimit 63 "Reserved(63)" 62 "Reserved(62)" 61 "Reserved(61)" 60 "Reserved(60)" 59 "Reserved(59)" 58 "Reserved(58)" 57 "Reserved(57)" 56 "Reserved(56)" 55 "Reserved(55)" 54 "Reserved(54)" 53 "Reserved(53)" 52 "Reserved(52)" 51 "Reserved(51)" 50 "Reserved(50)" 49 "Reserved(49)" 48 "Reserved(48)" 47 "Reserved(47)" 46 "Reserved(46)" 45 "Reserved(45)" 44 "Reserved(44)" 43 "Reserved(43)" 42 "Reserved(42)" 41 "Reserved(41)" 40 "Reserved(40)" 39 "Reserved(39)" 38 "Reserved(38)" 37 "Reserved(37)" 36 "Reserved(36)" 35 "Reserved(35)" 34 "Reserved(34)" 33 "Reserved(33)" 32 "Reserved(32)" 31 "Reserved(31)" 30 "Reserved(30)" 29 "Reserved(29)" 28 "Reserved(28)" 27 "Reserved(27)" 26 "SPL_130(26)" 25 "SPL_125(25)" 24 "SPL_120(24)" 23 "SPL_115(23)" 22 "SPL_110(22)" 21 "SPL_105(21)" 20 "SPL_100(20)" 19 "SPL_95(19)" 18 "SPL_90(18)" 17 "SPL_85(17)" 16 "SPL_80(16)" 15 "SPL_75(15)" 14 "SPL_70(14)" 13 "SPL_65(13)" 12 "SPL_60(12)" 11 "SPL_55(11)" 10 "SPL_50(10)" 9 "SPL_45(9)" 8 "SPL_40(8)" 7 "SPL_35(7)" 6 "SPL_30(6)" 5 "SPL_25(5)" 4 "SPL_20(4)" 3 "SPL_15(3)" 2 "SPL_10(2)" 1 "SPL_5(1)" ;
VAL_ 1335 IHU_9_NavSpeedLimitStatus 3 "SL_PLURAL(3)" 2 "SL_NOLIMIT(2)" 1 "SL_EXISTS(1)" 0 "SL_UNKNOWN(0)" ;
VAL_ 1309 Child_Safety_Lock 3 "Reserved" 2 "Unlock" 1 "Lock" 0 "Not active" ;
VAL_ 1309 SET_PAS_Switch 3 "Not_Used(3)" 2 "Switch_On(2)" 1 "Switch_Off(1)" 0 "Initial_Startup(0)" ;
VAL_ 1309 CGW_DVDSET_IPBAssociateDriveMode 3 "_Not_Used(3)" 2 "_OFF(2)" 1 "_ON(1)" 0 "_Not_Active(0)" ;
VAL_ 1309 CGW_CST_SensitivityReq 3 "_Reserved(3)" 2 "_HighSensitivity(2)" 1 "_LowSensitivity(1)" 0 "_Not_Active(0)" ;
VAL_ 1309 ESCOFF_ON_OFF 3 "Not_Used(3)" 2 "OFF(2)" 1 "ON(1)" 0 "Not_Active(0)" ;
VAL_ 1309 HDC_ON_OFF 3 "Not_Used(3)" 2 "OFF(2)" 1 "ON(1)" 0 "Not_Active(0)" ;
VAL_ 1309 AVH_ON_OFF 3 "Not_Used(3)" 2 "OFF(2)" 1 "ON(1)" 0 "Not_Active(0)" ;
VAL_ 1309 IHU_CGW_BrakepedalfeelModeSetReq 3 "_Reserved(3)" 2 "_Sport(2)" 1 "_Comfort(1)" 0 "_Initial_Startup_NoReq(0)" ;
VAL_ 1309 IHU_8_CGW_Set_CSTFunctionSts 3 "_Not_Used(3)" 2 "_CST_OFF(2)" 1 "_CST_ON(1)" 0 "Initial_Startup_NoReq(0)" ;
VAL_ 1309 IHU_8_LDWLKA_LaneAssit_TypeReq 3 "OFF(3)" 2 "LKA(2)" 1 "LDW(1)" 0 "Default(0)" ;
VAL_ 1309 IHU_8_SLAOnOffReq 3 "Reserved(3)" 2 "Not_Active(2)" 1 "On(1)" 0 "Off(0)" ;
VAL_ 1309 IHU_8_HMAOnOffReq 3 "Reserved(3)" 2 "Not_Active(2)" 1 "HMA_Selected(1)" 0 "HMA_Not_Selected(0)" ;
VAL_ 1309 IHU_8_LDW_LKA_SensitivityReq 3 "Reserved(3)" 2 "Not_Active(2)" 1 "HighSensitivity(1)" 0 "LowSensitivity(0)" ;
VAL_ 1309 IHU_8_TimeGapLastSetReq 3 "Reserved(3)" 2 "Not_Active(2)" 1 "On(1)" 0 "Off(0)" ;
VAL_ 1309 IHU_8_DistanceWarning_On_Off 3 "reserved(3)" 2 "switch_On(2)" 1 "switch_Off(1)" 0 "Not_Active(0)" ;
VAL_ 1309 IHU_8_TJA_ICA_ON_OFF 3 "reserved(3)" 2 "switch_On(2)" 1 "switch_Off(1)" 0 "Not_Active(0)" ;
VAL_ 1309 IHU_8_AEB_ON_OFF 3 "reserved(3)" 2 "switch_On(2)" 1 "switch_Off(1)" 0 "Not_Active(0)" ;
VAL_ 1309 IHU_8_FCW_OPTION 3 "far(3)" 2 "near(2)" 1 "standard(1)" 0 "Not_Active(0)" ;
VAL_ 1309 IHU_8_FCW_ON_OFF 3 "reserved(3)" 2 "switch_On(2)" 1 "switch_Off(1)" 0 "Not_Active(0)" ;
VAL_ 1309 IHU_8_TimeGapSet1Req 7 "reserved(7)" 6 "reserved(6)" 5 "reserved(5)" 4 "reserved(4)" 3 "tauGap_2(3)" 2 "tauGap_1(2)" 1 "tauGap_0(1)" 0 "Not_Active(0)" ;
VAL_ 1344 IHU_6_AmbientLight_SceneMode 3 "OFF(3)" 2 "Rset Mode (2)" 1 "VideoMode(1)" 0 "No Request(0)" ;
VAL_ 1344 IHU_6_SET_MusicLoudness_6000HZ 15 "Invalid(15)" 14 "Level_15(14)" 13 "Level_14(13)" 12 "Level_13(12)" 11 "Level_12(11)" 10 "Level_11(10)" 9 "Level_10(9)" 8 "Level_9(8)" 7 "Level_8(7)" 6 "Level_7(6)" 5 "Level_6(5)" 4 "Level_5(4)" 3 "Level_4(3)" 2 "Level_3(2)" 1 "Level_2(1)" 0 "Level_1(0)" ;
VAL_ 1344 IHU_6_SET_MusicLoudness_2000HZ 15 "Invalid(15)" 14 "Level_15(14)" 13 "Level_14(13)" 12 "Level_13(12)" 11 "Level_12(11)" 10 "Level_11(10)" 9 "Level_10(9)" 8 "Level_9(8)" 7 "Level_8(7)" 6 "Level_7(6)" 5 "Level_6(5)" 4 "Level_5(4)" 3 "Level_4(3)" 2 "Level_3(2)" 1 "Level_2(1)" 0 "Level_1(0)" ;
VAL_ 1344 IHU_6_SET_MusicLoudness_1500HZ 15 "Invalid(15)" 14 "Level_15(14)" 13 "Level_14(13)" 12 "Level_13(12)" 11 "Level_12(11)" 10 "Level_11(10)" 9 "Level_10(9)" 8 "Level_9(8)" 7 "Level_8(7)" 6 "Level_7(6)" 5 "Level_6(5)" 4 "Level_5(4)" 3 "Level_4(3)" 2 "Level_3(2)" 1 "Level_2(1)" 0 "Level_1(0)" ;
VAL_ 1344 IHU_6_SET_MusicLoudness_1000HZ 15 "Invalid(15)" 14 "Level_15(14)" 13 "Level_14(13)" 12 "Level_13(12)" 11 "Level_12(11)" 10 "Level_11(10)" 9 "Level_10(9)" 8 "Level_9(8)" 7 "Level_8(7)" 6 "Level_7(6)" 5 "Level_6(5)" 4 "Level_5(4)" 3 "Level_4(3)" 2 "Level_3(2)" 1 "Level_2(1)" 0 "Level_1(0)" ;
VAL_ 1344 IHU_6_SET_MusicLoudness_500HZ 15 "Invalid(15)" 14 "Level_15(14)" 13 "Level_14(13)" 12 "Level_13(12)" 11 "Level_12(11)" 10 "Level_11(10)" 9 "Level_10(9)" 8 "Level_9(8)" 7 "Level_8(7)" 6 "Level_7(6)" 5 "Level_6(5)" 4 "Level_5(4)" 3 "Level_4(3)" 2 "Level_3(2)" 1 "Level_2(1)" 0 "Level_1(0)" ;
VAL_ 1344 IHU_6_SET_MusicLoudness_250HZ 15 "Invalid(15)" 14 "Level_15(14)" 13 "Level_14(13)" 12 "Level_13(12)" 11 "Level_12(11)" 10 "Level_11(10)" 9 "Level_10(9)" 8 "Level_9(8)" 7 "Level_8(7)" 6 "Level_7(6)" 5 "Level_6(5)" 4 "Level_5(4)" 3 "Level_4(3)" 2 "Level_3(2)" 1 "Level_2(1)" 0 "Level_1(0)" ;
VAL_ 1344 IHU_6_SET_MusicLoudness_120HZ 15 "Invalid(15)" 14 "Level_15(14)" 13 "Level_14(13)" 12 "Level_13(12)" 11 "Level_12(11)" 10 "Level_11(10)" 9 "Level_10(9)" 8 "Level_9(8)" 7 "Level_8(7)" 6 "Level_7(6)" 5 "Level_6(5)" 4 "Level_5(4)" 3 "Level_4(3)" 2 "Level_3(2)" 1 "Level_2(1)" 0 "Level_1(0)" ;
VAL_ 1344 IHU_6_SET_Apiluminance 15 "Invalid(15)" 14 "Reserved(14)" 13 "Reserved(13)" 12 "Reserved(12)" 11 "Reserved(11)" 10 "Reserved(10)" 9 "Reserved(9)" 8 "Reserved(8)" 7 "Level8(7)" 6 "Level7(6)" 5 "Level6(5)" 4 "Level5_Startup(4)" 3 "Level4(3)" 2 "Level3(2)" 1 "Level2(1)" 0 "Level1(0)" ;
VAL_ 1344 IHU_6_SET_DMSMonitoring 3 "Invalid(3)" 2 "Reserved(2)" 1 "ON(1)" 0 "OFF_Startup(0)" ;
VAL_ 1344 IHU_6_SET_PM2_5Monitoring 3 "Invalid(3)" 2 "Reserved(2)" 1 "ON(1)" 0 "OFF_Startup(0)" ;
VAL_ 1344 IHU_6_SET_DriveApiluminance 3 "Close(3)" 2 "Dark(2)" 1 "Normal(1)" 0 "Invalid(0)" ;
VAL_ 1344 IHU_6_SET_Static_Colour 15 "Invalid(15)" 14 "Reserved(14)" 13 "Reserved(13)" 12 "Reserved(12)" 11 "Reserved(11)" 10 "Reserved(10)" 9 "Reserved(9)" 8 "Reserved(8)" 7 "Colour_8_Purple(7)" 6 "Colour_7_Pink(6)" 5 "Colour_6_Red(5)" 4 "Colour_5_Orange(4)" 3 "Colour_4_Yellow(3)" 2 "Colour_3_Green(2)" 1 "Colour_2_Cyan(1)" 0 "Colour_1_Blue(0)" ;
VAL_ 1344 IHU_6_SET_StaticEffect 7 "Startup(7)" 3 "All_Discolour_Breath(3)" 2 "Discolour_Breath(2)" 1 "Monochrome_Breath(1)" 0 "Monochrome_Static(0)" ;
VAL_ 1344 IHU_6_SET_ControlSwitch 3 "Invalid(3)" 2 "Force(2)" 1 "OFF(1)" 0 "Control_Startup(0)" ;
VAL_ 1344 IHU_6_SET_WelcomeWaterLamp 3 "Invalid(3)" 2 "Reserved(2)" 1 "ON_Startup(1)" 0 "OFF(0)" ;
VAL_ 1344 IHU_6_SET_AssociatedWithDriverMo 3 "Invalid(3)" 2 "Reserved(2)" 1 "ON(1)" 0 "OFF_Startup(0)" ;
VAL_ 1344 IHU_6_SET_Music 3 "Invalid(3)" 2 "Reserved(2)" 1 "ON(1)" 0 "OFF_Startup(0)" ;
VAL_ 1327 IHU_5_UVC_LuminanceReq 3 "Reserved(3)" 2 "High(2)" 1 "Low(1)" 0 "No Request(0)" ;
VAL_ 1327 IHU_5_UVC_ControlReq 3 "Auto(3)" 2 "Closed(2)" 1 "Open(1)" 0 "No Request(0)" ;
VAL_ 1327 IHU_5_PM25DisplayToggle 2 "Out(2)" 1 "In(1)" 0 "No Request(0)" ;
VAL_ 1327 IHU_5_DVD_DWMCon_Req 3 "Rise(3)" 2 "Close(2)" 1 "Open(1)" ;
VAL_ 1327 IHU_5_SyncSwtich_Req 3 "Reserved(3)" 0 "Invalid(0)" 2 "Active(2)" 1 "Not_Active(1)" ;
VAL_ 1327 IHU_5_AnionPurify_Req 3 "Reserved(3)" 0 "Invalid(0)" 2 "Active(2)" 1 "Not_Active(1)" ;
VAL_ 1327 IHU_5_AutoState 3 "Reserved(3)" 0 "Invalid(0)" 2 "Active(2)" 1 "Not_Active(1)" ;
VAL_ 1327 IHU_5_EngineControlEDReq 0 "Startup_Default(0)" 1 "Engine_Control_Enable(1)" ;
VAL_ 1327 IHU_5_RRWindowCon_Req 0 "Startup_Default(0)" 4 "Open~80_Bottom_To_80%(4)" 3 "80%~Close_80%_To_Top(3)" 2 "Open_Bottom(2)" 1 "Closed_Top(1)" ;
VAL_ 1327 IHU_5_LRWindowCon_Req 0 "Startup_Default(0)" 4 "Open~80_Bottom_To_80%(4)" 3 "80%~Close_80%_To_Top(3)" 2 "Open_Bottom(2)" 1 "Closed_Top(1)" ;
VAL_ 1327 IHU_5_FLWindowCon_Req 0 "Startup_Default(0)" 4 "Open~80_Bottom_To_80%(4)" 3 "80%~Close_80%_To_Top(3)" 2 "Open_Bottom(2)" 1 "Closed_Top(1)" ;
VAL_ 1327 IHU_5_FRWindowCon_Req 0 "Startup_Default(0)" 4 "Open~80_Bottom_To_80%(4)" 3 "80%~Close_80%_To_Top(3)" 2 "Open_Bottom(2)" 1 "Closed_Top(1)" ;
VAL_ 1327 IHU_5_Control_Mode_Req 3 "Reserved(3)" 0 "Invalid(0)" 2 "Heat_Mode(2)" 1 "Cool_Mode(1)" ;
VAL_ 1327 IHU_5_TempknobRollingCounterReq 31 "Reserved(31)" 30 "Reserved(30)" 29 "Reserved(29)" 28 "Reserved(28)" 27 "Reserved(27)" 26 "Reserved(26)" 25 "Reserved(25)" 24 "Reserved(24)" 23 "Reserved(23)" 22 "Reserved(22)" 21 "Reserved(21)" 20 "Reserved(20)" 19 "Reserved(19)" 18 "Reserved(18)" 17 "Reserved(17)" 16 "Reserved(16)" 15 "15(15)" 14 "14(14)" 13 "13(13)" 12 "12(12)" 11 "11(11)" 10 "10(10)" 0 "Invalid(0)" ;
VAL_ 1327 IHU_5_RearDefrostSwitch_Req 3 "Reserved(3)" 0 "Invalid(0)" 2 "Active(2)" 1 "Not_Active(1)" ;
VAL_ 1327 IHU_5_ACRequestCommand 3 "Reserved(3)" 0 "Invalid(0)" 2 "Active(2)" 1 "Not_Active(1)" ;
VAL_ 1327 IHU_5_FrontOFF_Req 3 "Reserved(3)" 0 "Invalid(0)" 2 "Active(2)" 1 "Not_Active(1)" ;
VAL_ 1327 IHU_5_CirculationMode_Req 3 "Reserved(3)" 0 "Invalid(0)" 2 "Air_Circulation_Mode(2)" 1 "Recirculation_Mode(1)" ;
VAL_ 1327 IHU_5_ModeAdjust_Req 7 "Invalid(7)" 6 "Reserved(6)" 5 "Reserved(5)" 4 "Defrost(4)" 3 "BlowFoot_&_Defrost(3)" 2 "BlowFoot(2)" 1 "BlowFace_&_BlowFoot(1)" 0 "BlowFace(0)" ;
VAL_ 1327 IHU_5_BlowSpeedLevel_Req 15 "Invalid(15)" 14 "Reserved(14)" 13 "Reserved(13)" 12 "Reserved(12)" 11 "Reserved(11)" 10 "Reserved(10)" 9 "Reserved(9)" 8 "Reserved(8)" 0 "Startup(0)" 7 "Level_7(7)" 6 "Level_6(6)" 5 "Level_5(5)" 4 "Level_4(4)" 3 "Level_3(3)" 2 "Level_2(2)" 1 "Level_1(1)" ;
VAL_ 1325 IHU_4_PCItype 2 "Consecutive_Frame(2)" 1 "The_First_Frame(1)" 0 "The_Single_Frame(0)" ;
VAL_ 1303 IHU_3_Set_Default 7 "Not_Used(7)" 6 "Not_Used(6)" 5 "Not_Used(5)" 4 "Not_Used(4)" 3 "Not_Used(3)" 2 "Set_All_To_Default(2)" 1 "SetPersonalizationToDefault(1)" 0 "Not_Active(0)" ;
VAL_ 1303 IHU_3_DVD_SetScreen 3 "Press_Move(3)" 2 "Press_Up(2)" 1 "Press_Down(1)" 0 "Not_Event(0)" ;
VAL_ 1303 IHU_3_DVD_SetWorkModeSts 4 "SideParkingRsv(4)" 3 "RationingModeRsv(3)" 2 "3D_Mode(2)" 1 "2D_Mode(1)" 0 "No_Req(0)" ;
VAL_ 1303 IHU_3_DVD_DefDispMode 2 "3D(2)" 1 "2D(1)" 0 "NO_Req(0)" ;
VAL_ 1303 IHU_3_BT_PHONE_Sts 2 "Noactive(2)" 1 "Active(1)" 0 "invalid(0)" ;
VAL_ 1303 IHU_3_DVD_Set_RCW 3 "Not_Used(3)" 2 "OFF(2)" 1 "ON(1)" 0 "Not_Active(0)" ;
VAL_ 1303 IHU_3_DVD_Set_DOW 3 "Not_Used(3)" 2 "OFF(2)" 1 "ON(1)" 0 "Not_Active(0)" ;
VAL_ 1303 IHU_3_DVD_Set_RadarWarining 2 "OFF(2)" 1 "ON(1)" 0 "NO_Req(0)" ;
VAL_ 1303 IHU_3_AVM_SET_LANG 4 "Spanish(4)" 3 "Arabic(3)" 2 "English(2)" 1 "Chinese(1)" 0 "NO_Req(0)" ;
VAL_ 1303 IHU_3_AVM_OP_VIEW_DVR_SW 3 "Close(3)" 2 "OpenDVR(2)" 1 "OpenAVM(1)" 0 "No_Req(0)" ;
VAL_ 1303 IHU_3_DVD_Set_SteeringWheel 2 "OFF(2)" 1 "ON(1)" 0 "NO_Req(0)" ;
VAL_ 1303 IHU_3_BSDSwitch 3 "Not_Used(3)" 2 "OFF(2)" 1 "ON(1)" 0 "Not_Active(0)" ;
VAL_ 1303 IHU_3_LDWSwitch 2 "OFF(2)" 1 "ON(1)" 0 "NO_Req(0)" ;
VAL_ 1303 IHU_3_CalibrationRequest 1 "Enter_Calibration(1)" 0 "No_Action(0)" ;
VAL_ 1303 IHU_APA_OP_SW 3 "Startup/Close(3)" 2 "CloseAPA(2)" 1 "OpenAPA(1)" 0 "No Req(0)" ;
VAL_ 1302 IHU_2_Trip2Reset 1 "Reset(1)" 0 "No Request(0)" ;
VAL_ 1302 IHU_2_Trip1Reset 1 "Reset(1)" 0 "No Request(0)" ;
VAL_ 1302 IHU_2_IHULanguageSet 15 "Reserved(15)" 14 "Reserved(14)" 13 "Reserved(13)" 12 "Reserved(12)" 11 "Reserved(11)" 10 "Reserved(10)" 9 "Reserved(9)" 8 "Reserved(8)" 7 "Farsi(7)" 6 "Arabic(6)" 5 "Russian(5)" 4 "Spanish(4)" 3 "French(3)" 2 "English(2)" 1 "Chinese(1)" 0 "Not_Active(0)" ;
VAL_ 1302 IHU_2_IHU_Set_Theme 7 "Reserved(7)" 6 "Reserved(6)" 5 "Reserved(5)" 4 "Reserved(4)" 3 "Theme3(3)" 2 "Theme2(2)" 1 "Theme1(1)" 0 "Not_Active(0)" ;
VAL_ 1302 IHU_2_FrequencySts 0 "PlayOff(0)" 1 "PlayOn(1)" ;
VAL_ 1302 IHU_2_IHUOnSts 1 "IHUOn(1)" 0 "IHUOff(0)" ;
VAL_ 1302 IHU_2_SourceStationMode 7 "LocalStorage(7)" 6 "iPOD(6)" 5 "Bluetooth(5)" 4 "Online_Radio(4)" 3 "Online_Music(3)" 2 "USB(2)" 1 "Radio(1)" 0 "Not_Active(0)" ;
VAL_ 1302 IHU_2_RadioResearchSts 3 "Reserved(3)" 2 "AST(2)" 1 "Normal(1)" 0 "Not_Active(0)" ;
VAL_ 1302 IHU_2_RadioFrequanceMode 2 "AM_Mode(2)" 1 "FM_Mode(1)" 0 "Not_Active(0)" ;
VAL_ 1301 IHU_1_SET_DWD_Req 3 "Reserved" 2 "Active" 1 "Not_Active" 0 "nvaild" ;
VAL_ 1301 IHU_1_RegenerateLevelCtrl 2 "Down(2)" 1 "UP(1)" 0 "No Request(0)" ;
VAL_ 1301 IHU_1_DVD_SetFraganceTime 3 "reset_taste3(3)" 2 "reset_taste2(2)" 1 "reset_taste1(1)" 0 "No_request(0)" ;
VAL_ 1301 DVD_Set_FraganceConcentration 3 "High(3)" 2 "Mid(2)" 1 "Low(1)" 0 "No_Action(0)" ;
VAL_ 1301 IHU_1_DVD_Set_FraganceTaste 3 "Taste_3(3)" 2 "Taste_2(2)" 1 "Taste_1(1)" 0 "No_Action(0)" ;
VAL_ 1301 IHU_1_DVD_Set_FraganceSwitchSt 3 "Invalid(3)" 2 "Reserved(2)" 1 "AFU_ON(1)" 0 "AFU_OFF(0)" ;
VAL_ 1301 IHU_1_DVD_Set_External_Welcome_L 4 "OFF(4)" 3 "Mode3(3)" 2 "Mode2(2)" 1 "Mode1(1)" 0 "No_Request(0)" ;
VAL_ 1301 IHU_1_DVD_Set_Show_Mode 3 "Mode3(3)" 2 "Mode2(2)" 1 "Mode1(1)" 0 "No_Request(0)" ;
VAL_ 1301 IHU_1_DVD_SET_Polling 2 "Not_Active(2)" 1 "Active(1)" 0 "No_Request(0)" ;
VAL_ 1301 IHU_1_DVD_SET_IPM_First_Blowing 2 "Not_Active(2)" 1 "Active(1)" 0 "No_Request(0)" ;
VAL_ 1301 IHU_1_DVD_SET_IPM_Blower_Delay 2 "Not_Active(2)" 1 "Active(1)" 0 "No_Request(0)" ;
VAL_ 1301 IHU_DVD_SET_BT_Reduce_Wind_Speed 2 "Not_Active(2)" 1 "Active(1)" 0 "No_Request(0)" ;
VAL_ 1301 IHU_1_DVD_SET_RemoteLockFeedback 4 "No_Feedback(4)" 3 "Only_Speaker(3)" 2 "Only_Lamp(2)" 1 "Lamp_And_Speaker(1)" 0 "No_Request(0)" ;
VAL_ 1301 IHU_1_DVD_SET_EPSmode 3 "运动模式_Sport(3)" 2 "舒适模式_Comfort(2)" 1 "经济模式_Economy(1)" 0 "Reseverd（预留位）(0)" ;
VAL_ 1301 IHU_1_DVD_Set_Wash_Car 2 "ON(2)" 1 "OFF(1)" 0 "No_Request(0)" ;
VAL_ 1301 IHU_1_DVD_Set_12_24_Hour 2 "24_Hour(2)" 1 "12_Hour(1)" 0 "No_Request(0)" ;
VAL_ 1301 IHU_1_DVD_SET_Blankingnumber 0 "No_Request(0)" ;
VAL_ 1301 IHU_1_DVD_SET_AutoUnlockSts 2 "AutoUnlockNotActive(2)" 1 "AutoUnlockActive(1)" 0 "No_Request(0)" ;
VAL_ 1301 IHU_1_DVD_SET_AutoLockSts 2 "AutoLockNotActive(2)" 1 "AutoLock_Active(1)" 0 "No_Request(0)" ;
VAL_ 1301 IHU_1_DVD_SET_AidTurningIllumina 2 "NotAidTurningIlluminationMode(2)" 1 "AidTurningIlluminationMode(1)" 0 "No_Request(0)" ;
VAL_ 1301 IHU_1_DVD_SET_FollowMeHome 3 "Close(3)" 2 "60s(2)" 1 "30s(1)" 0 "No_Request(0)" ;
VAL_ 1301 IHU_1_DVD_SET_Mirror_Fold 2 "Off(2)" 1 "Active(1)" 0 "No_Request(0)" ;
SIG_GROUP_ 1069 IHU_20_0x42D_group 1 : IHU_17_EDL_SwtCmd IHU_20_RgnSet IHU_PowermodeSet IHU_SetSOC Set_AVASFuntion IHU_SetSocManage IHU_ChargeModeSet IHU_TimeToStartChargeHourSet IHU_TimeToStartChargeMinuteSet IHU_TimeToStopChargeHourSet IHU_TimeToStopChargeMinuteSet IHU_17_SetChrgnFctMem IHU_17_Set_HundECAverHisClearSts;
SIG_GROUP_ 1407 IHU_15_0x57F_group 1 : SET_Driver_Mirror_Location SET_Passenger_Mirror_Location IHU_IPM_Delayventilation_Req IHU_15_door_lock_req IHU_15_GalleryModeReg IHU_15_AutoDefogEnaSw IHU_15_Parkingairconditioning IHU15_MessageCounter IHU_SpeechControl SET_RightMirrorCtrl SET_LeftMirrorCtrl SET_Mirror_Fold_Switch SET_Mirror_Flip_CFG SET_IPMCustom_Air_Conditioning SET_IPM_Automatic_Ventilation SET_FRSeatHeatVentSwReq SET_FLSeatHeatVentSwReq SET_IHU_ACMAXReq;
SIG_GROUP_ 1400 IHU_14_0x578_group 1 : MFS_ModeSts;
SIG_GROUP_ 1401 IHU_13_0x579_group 1 : SET_Smart_LowBeam SET_Driver_unlockmode SET_Doorkonb_time SET_Doorkonbmode SET_PLG_Control SET_Wiper_Maintenance SET_UnderVoltage IHU13_MessageCounter SET_RearWiper_Switch SET_Welcome_Seat SET_LowBeam_Adjust SET_MFS_Shake SET_Massagemode SET_Vibrationmode SET_Passenger_Massage SET_Abat_VentCMD SET_PSRFCMD SET_MFS_Heat;
SIG_GROUP_ 1309 IHU_8_0x51D_group 1 : IHU_EPB_Cmd IHU_EPBAUTO_Cmd IHU_SpeParkSet IHU_8_TimeGapSet1Req IHU8Curvedeceleration_ON_OFF_Sts IHU_8_FCW_ON_OFF IHU_8_FCW_OPTION IHU_8_AEB_ON_OFF IHU_8_TJA_ICA_ON_OFF IHU_8_DistanceWarning_On_Off IHU_8_TimeGapLastSetReq IHU_8_LDW_LKA_SensitivityReq IHU_8_SLAOnOffReq IHU_8_LDWLKA_LaneAssit_TypeReq IHU_8_CGW_Set_CSTFunctionSts IHU_CGW_BrakepedalfeelModeSetReq CGW_CST_SensitivityReq CGW_DVDSET_IPBAssociateDriveMode IHU_8_CCOSwtReq Child_Safety_Lock SET_PAS_Switch IHU_8_HMAOnOffReq AVH_ON_OFF HDC_ON_OFF ESCOFF_ON_OFF;
SIG_GROUP_ 1327 IHU5_0x52F_group 1 : IHU_5_DVD_DWMCon_Req IHU_5_CoolantFill_Req IHU_5_PM25DisplayToggle IHU_5_TempknobRollingCounterReq IHU_5_Control_Mode_Req IHU_5_EngineControlEDReq IHU_5_RRWindowCon_Req IHU_5_LRWindowCon_Req IHU_5_FLWindowCon_Req IHU_5_FRWindowCon_Req IHU_5_UVC_ControlReq IHU_5_UVC_LuminanceReq IHU_5_AnionPurify_Req IHU_5_CirculationMode_Req IHU_5_BlowSpeedLevel_Req IHU_5_R_Set_Temperature IHU_5_L_Set_Temperature IHU_5_SyncSwtich_Req IHU_5_RearDefrostSwitch_Req IHU_5_ModeAdjust_Req IHU_5_AutoState IHU_5_ACRequestCommand IHU_5_FrontOFF_Req;
SIG_GROUP_ 1303 IHU_3_0x517_group 1 : IHU_APA_OP_SW IHU_3_LDWSwitch IHU_3_DVD_Set_SteeringWheel IHU_3_AVM_OP_VIEW_DVR_SW IHU_3_DVD_Set_RadarWarining IHU_3_DVD_DefDispMode IHU_3_DVD_OP_TP_X IHU_3_DVD_OP_TP_Y IHU_3_DVD_SetWorkModeSts IHU_3_DVD_SetScreen IHU_3_Set_Default IHU_3_CalibrationRequest IHU_3_DVD_Set_RCW IHU_3_DVD_Set_DOW IHU_3_BSDSwitch;
SIG_GROUP_ 1301 IHU_1_0x515_group 1 : IHU_1_DVD_SET_HazardLampForUrgen IHU_1_DVD_SET_Mirror_Flip IHU_1_DVD_SET_Laser_High_Beam_As IHU_1_DVD_SET_PLG_SAS IHU_1_DVD_Set_External_Welcome_L IHU_1_DVD_Set_Show_Mode IHU_1_DVD_Set_Wash_Car IHU_1_DVD_SET_AidTurningIllumina IHU_1_DVD_Set_12_24_Hour IHU_1_RegenerateLevelCtrl IHU_1_DVD_SET_Polling IHU_1_DVD_SET_RemoteLockFeedback IHU_1_DVD_SET_AutoUnlockSts IHU_1_DVD_SET_AutoLockSts IHU_1_SET_DWD_Req IHU_1_DVD_SET_Blankingnumber IHU_1_DVD_SET_FollowMeHome DVD_EPS_AssociWithDriverModeSts IHU_1_DVD_SET_EPSmode IHU_1_DVD_SET_Mirror_Fold IHU_1_DVD_SET_IPM_First_Blowing IHU_DVD_SET_BT_Reduce_Wind_Speed IHU_1_DVD_SET_IPM_Blower_Delay DVD_Set_FraganceConcentration IHU_1_DVD_Set_FraganceSwitchSt IHU_1_DVD_Set_FraganceTaste;
